VERSION ""

NS_ :

BS_:

BU_: AVM_SD CGW IVI eHBox

BO_ 1330 DVR_N101: 8 CGW
  SG_ GeneralRecordingStatus : 0|1@0+ (1,0) [0|0] "" IVI
  SG_ SDCardStatus : 3|3@0+ (1,0) [0|0] "" IVI
  SG_ DVRWorkStatus : 7|4@0+ (1,0) [0|0] "" IVI
  SG_ LanguageStatus : 9|2@0+ (1,0) [0|0] "" IVI
  SG_ FolderStatus : 11|2@0+ (1,0) [0|0] "" IVI
  SG_ FileStatus : 14|3@0+ (1,0) [0|0] "" IVI
  SG_ PhotoReady : 15|1@0+ (1,0) [0|0] "" IVI
  SG_ CollideCheckStatus : 17|2@0+ (1,0) [0|0] "" IVI
  SG_ ParkingMonitor : 19|2@0+ (1,0) [0|0] "" IVI
  SG_ CollideSensitivityStatus : 21|2@0+ (1,0) [0|0] "" IVI
  SG_ MuteRecordStatus : 23|2@0+ (1,0) [0|0] "" IVI
  SG_ SuperpositionSpeedShow : 25|2@0+ (1,0) [0|0] "" IVI
  SG_ SuperpositionOthersShow : 27|2@0+ (1,0) [0|0] "" IVI
  SG_ RecordVideoQuality : 29|2@0+ (1,0) [0|0] "" IVI
  SG_ RecordTime : 31|2@0+ (1,0) [0|0] "" IVI
  SG_ WiFiStatus : 32|1@0+ (1,0) [0|0] "" IVI
  SG_ DVR_FileSelectStatus : 33|1@0+ (1,0) [0|0] "" IVI
  SG_ NetworkStatus : 39|4@0+ (1,0) [0|0] "" IVI
  SG_ SelftimerState : 41|2@0+ (1,0) [0|0] "" IVI
  SG_ ContrastStateRRcam : 44|3@0+ (1,0) [0|0] "" IVI
  SG_ ContrastStateFRcam : 47|3@0+ (1,0) [0|0] "" IVI
  SG_ NetworkStatus_CameraAngle : 49|2@0+ (1,0) [0|0] "" IVI
  SG_ BrightnessStateRRcam : 52|3@0+ (1,0) [0|0] "" IVI
  SG_ BrightnessStateINcam : 55|3@0+ (1,0) [0|0] "" IVI
  SG_ NetworkStatus_CameraView : 57|2@0+ (1,0) [0|0] "" IVI
  SG_ ContrastStateINcam : 60|3@0+ (1,0) [0|0] "" IVI
  SG_ BrightnessState : 63|3@0+ (1,0) [0|0] "" IVI

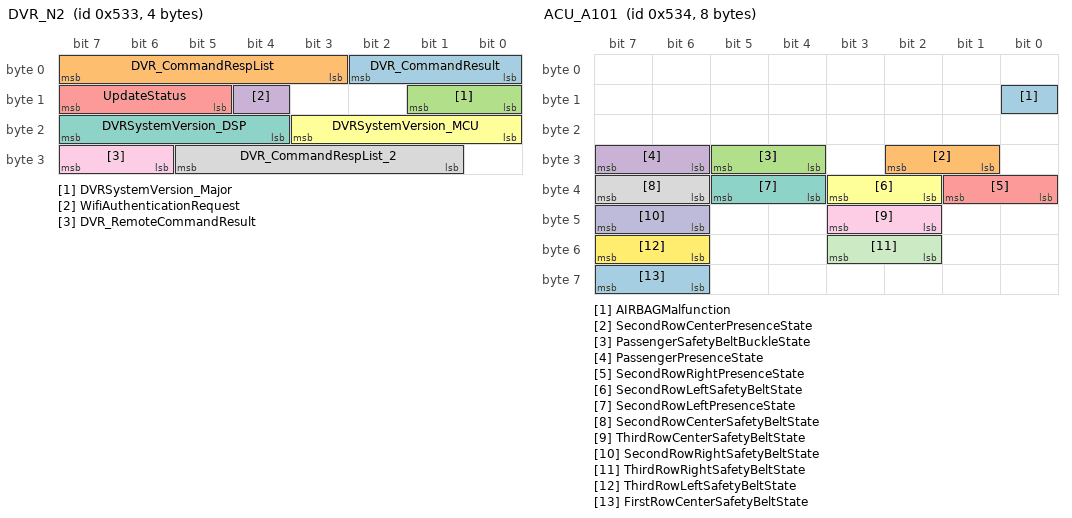
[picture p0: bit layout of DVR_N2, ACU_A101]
BO_ 1331 DVR_N2: 4 CGW
  SG_ DVR_CommandResult : 2|3@0+ (1,0) [0|0] "" IVI
  SG_ DVR_CommandRespList : 7|5@0+ (1,0) [0|0] "" IVI
  SG_ DVRSystemVersion_Major : 9|2@0+ (1,0) [0|0] "" IVI
  SG_ WifiAuthenticationRequest : 12|1@0+ (1,0) [0|0] "" IVI
  SG_ UpdateStatus : 15|3@0+ (1,0) [0|0] "" IVI
  SG_ DVRSystemVersion_MCU : 19|4@0+ (1,0) [0|0] "" IVI
  SG_ DVRSystemVersion_DSP : 23|4@0+ (1,0) [0|0] "" IVI
  SG_ DVR_CommandRespList_2 : 29|5@0+ (1,0) [0|0] "" IVI
  SG_ DVR_RemoteCommandResult : 31|2@0+ (1,0) [0|0] "" IVI

BO_ 1332 ACU_A101: 8 CGW
  SG_ AIRBAGMalfunction : 8|1@0+ (1,0) [0|0] "" IVI
  SG_ SecondRowCenterPresenceState : 26|2@0+ (1,0) [0|0] "" IVI
  SG_ PassengerSafetyBeltBuckleState : 29|2@0+ (1,0) [0|0] "" IVI
  SG_ PassengerPresenceState : 31|2@0+ (1,0) [0|0] "" IVI
  SG_ SecondRowRightPresenceState : 33|2@0+ (1,0) [0|0] "" IVI
  SG_ SecondRowLeftSafetyBeltState : 35|2@0+ (1,0) [0|0] "" IVI
  SG_ SecondRowLeftPresenceState : 37|2@0+ (1,0) [0|0] "" IVI
  SG_ SecondRowCenterSafetyBeltState : 39|2@0+ (1,0) [0|0] "" IVI
  SG_ ThirdRowCenterSafetyBeltState : 43|2@0+ (1,0) [0|0] "" IVI
  SG_ SecondRowRightSafetyBeltState : 47|2@0+ (1,0) [0|0] "" IVI
  SG_ ThirdRowRightSafetyBeltState : 51|2@0+ (1,0) [0|0] "" IVI
  SG_ ThirdRowLeftSafetyBeltState : 55|2@0+ (1,0) [0|0] "" IVI
  SG_ FirstRowCenterSafetyBeltState : 63|2@0+ (1,0) [0|0] "" IVI

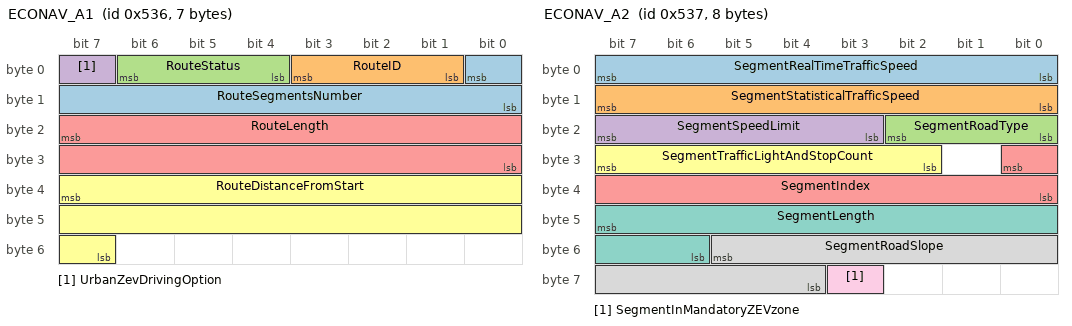
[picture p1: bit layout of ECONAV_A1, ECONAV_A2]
BO_ 1334 ECONAV_A1: 7 IVI
  SG_ RouteSegmentsNumber : 0|9@0+ (1,1) [1|512] "wu" CGW
  SG_ RouteID : 3|3@0+ (1,0) [0|0] "" CGW
  SG_ RouteStatus : 6|3@0+ (1,0) [0|0] "" CGW
  SG_ UrbanZevDrivingOption : 7|1@0+ (1,0) [0|0] "" CGW
  SG_ RouteLength : 23|16@0+ (0.1,0) [0|5000] "km" CGW
  SG_ RouteDistanceFromStart : 39|17@0+ (10,0) [0|1024000] "m" CGW

BO_ 1335 ECONAV_A2: 8 IVI
  SG_ SegmentRealTimeTrafficSpeed : 7|8@0+ (1,0) [0|200] "km/h" CGW
  SG_ SegmentStatisticalTrafficSpeed : 15|8@0+ (1,0) [0|200] "km/h" CGW
  SG_ SegmentRoadType : 18|3@0+ (1,0) [0|0] "" CGW
  SG_ SegmentSpeedLimit : 23|5@0+ (10,0) [0|200] "km/h" CGW
  SG_ SegmentIndex : 24|9@0+ (1,1) [1|512] "" CGW
  SG_ SegmentTrafficLightAndStopCount : 31|6@0+ (1,0) [0|62] "" CGW
  SG_ SegmentLength : 47|10@0+ (10,0) [0|8000] "m" CGW
  SG_ SegmentRoadSlope : 53|10@0+ (0.1,-40) [-40|40] "%" CGW
  SG_ SegmentInMandatoryZEVzone : 59|1@0+ (1,0) [0|0] "" CGW

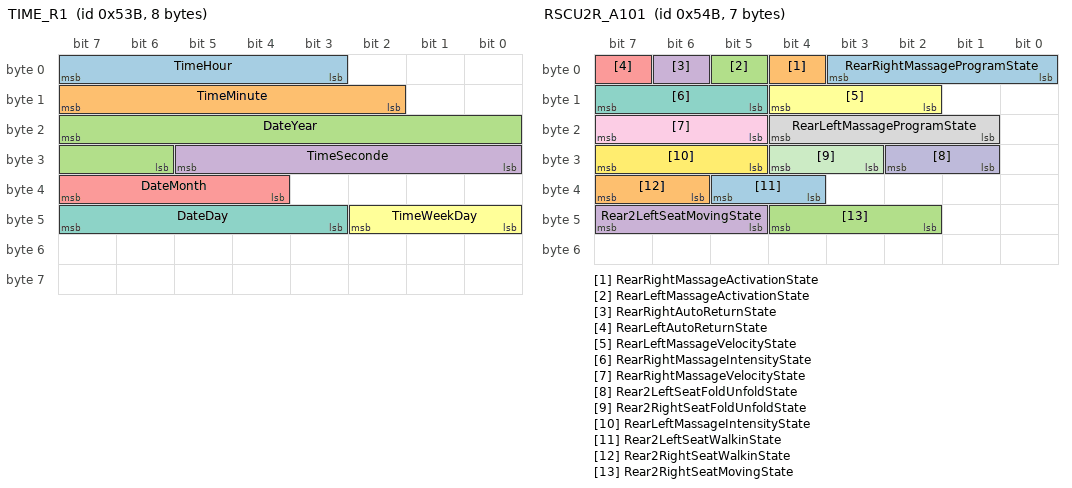
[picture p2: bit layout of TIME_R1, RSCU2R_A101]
BO_ 1339 TIME_R1: 8 IVI
  SG_ TimeHour : 7|5@0+ (1,0) [0|23] "h" CGW
  SG_ TimeMinute : 15|6@0+ (1,0) [0|59] "min" CGW
  SG_ DateYear : 23|10@0+ (1,2000) [2000|3000] "year" CGW
  SG_ TimeSeconde : 29|6@0+ (1,0) [0|59] "s" CGW
  SG_ DateMonth : 39|4@0+ (1,0) [0|12] "month" CGW
  SG_ TimeWeekDay : 42|3@0+ (1,0) [0|0] "" CGW
  SG_ DateDay : 47|5@0+ (1,0) [0|31] "day" CGW

BO_ 1341 SONAR_A4: 8 CGW
  SG_ UPA_SoundRecurrenceType : 0|1@0+ (1,0) [0|0] "" IVI
  SG_ UPA_SoundRecurrencePeriod : 7|7@0+ (0.1,0) [0|12.6] "Hz" IVI
  SG_ UPA_SystemState : 9|2@0+ (1,0) [0|0] "" IVI
  SG_ UPA_Obstacle_Zone_Front_Right : 12|3@0+ (1,0) [0|0] "" AVM_SD,IVI
  SG_ UPA_Obstacle_Zone_Front_Left : 15|3@0+ (1,0) [0|0] "" AVM_SD,IVI
  SG_ UPA_Image_DisplayRequest : 17|2@0+ (1,0) [0|0] "" AVM_SD,IVI
  SG_ UPA_Obstacle_Zone_Rear_Right : 20|3@0+ (1,0) [0|0] "" AVM_SD,IVI
  SG_ UPA_Obstacle_Zone_Rear_Left : 23|3@0+ (1,0) [0|0] "" AVM_SD,IVI
  SG_ UPA_SoundActivationBeep : 24|1@0+ (1,0) [0|0] "" IVI
  SG_ UPA_SoundErrorBeep : 25|1@0+ (1,0) [0|0] "" IVI
  SG_ UPA_Obstacle_Zone_Rear_Center : 28|3@0+ (1,0) [0|0] "" AVM_SD,IVI
  SG_ UPA_Obstacle_Zone_Front_Center : 31|3@0+ (1,0) [0|0] "" AVM_SD,IVI
  SG_ SensorAvailabilityFrontLeft : 32|1@0+ (1,0) [0|0] "" IVI
  SG_ SensorAvailabilityFrontCenter : 33|1@0+ (1,0) [0|0] "" IVI
  SG_ UPA_SoundObstacleZone : 36|3@0+ (1,0) [0|0] "" IVI
  SG_ UPAStatusDisplayRequest : 39|3@0+ (1,0) [0|0] "" IVI
  SG_ SensorAvailabilityFrontRight : 40|1@0+ (1,0) [0|0] "" IVI
  SG_ SonarObstacleDistanceDisplay : 44|4@0+ (1,0) [0|0] "" IVI
  SG_ ParkAssistVolumeState : 47|3@0+ (1,0) [0|0] "" IVI
  SG_ SensorAvailabilityRearRight : 53|1@0+ (1,0) [0|0] "" IVI
  SG_ SensorAvailabilityRearLeft : 54|1@0+ (1,0) [0|0] "" IVI
  SG_ SensorAvailabilityRearCenter : 55|1@0+ (1,0) [0|0] "" IVI
  SG_ UPA_ClosingAuthorization : 58|1@0+ (1,0) [0|0] "" IVI

BO_ 1343 HEVC_A110: 4 CGW
  SG_ V2L_InstantPower : 23|7@0+ (0.1,0) [0|12] "kW" IVI

BO_ 1345 FrCamADAS_R112: 8 CGW
  SG_ Fatigue_CustomShieldRequest : 33|2@0+ (1,0) [0|0] "" IVI
  SG_ Distraction_CustomShieldRequest : 35|2@0+ (1,0) [0|0] "" IVI

BO_ 1354 PSD_A102: 4 CGW
  SG_ PSD_R_AuthorizationState : 1|2@0+ (1,0) [0|0] "" IVI
  SG_ PSD_R_ActivationState : 4|3@0+ (1,0) [0|0] "" IVI
  SG_ PSD_R_ResponseState : 15|3@0+ (1,0) [0|0] "" IVI

BO_ 1355 RSCU2R_A101: 7 CGW
  SG_ RearRightMassageProgramState : 3|4@0+ (1,0) [0|0] "" IVI
  SG_ RearRightMassageActivationState : 4|1@0+ (1,0) [0|0] "" IVI
  SG_ RearLeftMassageActivationState : 5|1@0+ (1,0) [0|0] "" IVI
  SG_ RearRightAutoReturnState : 6|1@0+ (1,0) [0|0] "" IVI
  SG_ RearLeftAutoReturnState : 7|1@0+ (1,0) [0|0] "" IVI
  SG_ RearLeftMassageVelocityState : 12|3@0+ (1,0) [0|0] "" IVI
  SG_ RearRightMassageIntensityState : 15|3@0+ (1,0) [0|0] "" IVI
  SG_ RearLeftMassageProgramState : 20|4@0+ (1,0) [0|0] "" IVI
  SG_ RearRightMassageVelocityState : 23|3@0+ (1,0) [0|0] "" IVI
  SG_ Rear2LeftSeatFoldUnfoldState : 26|2@0+ (1,0) [0|0] "" IVI
  SG_ Rear2RightSeatFoldUnfoldState : 28|2@0+ (1,0) [0|0] "" IVI
  SG_ RearLeftMassageIntensityState : 31|3@0+ (1,0) [0|0] "" IVI
  SG_ Rear2LeftSeatWalkinState : 37|2@0+ (1,0) [0|0] "" IVI
  SG_ Rear2RightSeatWalkinState : 39|2@0+ (1,0) [0|0] "" IVI
  SG_ Rear2RightSeatMovingState : 44|3@0+ (1,0) [0|0] "" IVI
  SG_ Rear2LeftSeatMovingState : 47|3@0+ (1,0) [0|0] "" IVI

BO_ 1356 ADASISv2_A103: 8 IVI
  SG_ ADASISv2_POSITION : 7|64@0+ (1,0) [0|0] "" CGW

BO_ 1358 HEVC_R131: 8 CGW
  SG_ EV_maxChargingPower : 48|9@0+ (1,0) [0|400] "kW" IVI

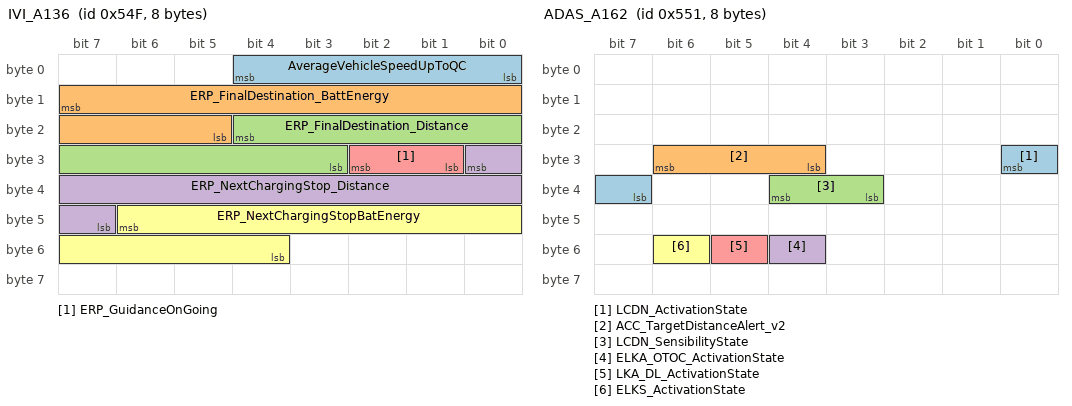
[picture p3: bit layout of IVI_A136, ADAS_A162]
BO_ 1359 IVI_A136: 8 IVI
  SG_ AverageVehicleSpeedUpToQC : 4|5@0+ (10,0) [0|200] "km/h" CGW
  SG_ ERP_FinalDestination_BattEnergy : 15|11@0+ (100,-50000) [-50000|150000] "wh" CGW
  SG_ ERP_FinalDestination_Distance : 20|10@0+ (1,0) [0|1022] "km" CGW
  SG_ ERP_NextChargingStop_Distance : 24|10@0+ (1,0) [0|1022] "km" CGW
  SG_ ERP_GuidanceOnGoing : 26|2@0+ (1,0) [0|0] "" CGW
  SG_ ERP_NextChargingStopBatEnergy : 46|11@0+ (100,-50000) [-50000|150000] "Wh" CGW

BO_ 1361 ADAS_A162: 8 CGW
  SG_ LCDN_ActivationState : 24|2@0+ (1,0) [0|0] "" IVI
  SG_ ACC_TargetDistanceAlert_v2 : 30|3@0+ (1,0) [0|0] "" IVI
  SG_ LCDN_SensibilityState : 36|2@0+ (1,0) [0|0] "" IVI
  SG_ ELKA_OTOC_ActivationState : 52|1@0+ (1,0) [0|0] "" IVI
  SG_ LKA_DL_ActivationState : 53|1@0+ (1,0) [0|0] "" IVI
  SG_ ELKS_ActivationState : 54|1@0+ (1,0) [0|0] "" IVI

BO_ 1364 HVAC_A112: 7 CGW
  SG_ ClimVariableAirFlowDisplay : 4|3@0+ (1,0) [0|0] "" IVI
  SG_ ClimRearOFFModeDisplay : 5|1@0+ (1,0) [0|0] "" IVI
  SG_ ClimRearLockStatus : 7|2@0+ (1,0) [0|0] "" IVI
  SG_ ClimLinkPrio3rdLSeatAutoDisp : 10|3@0+ (1,0) [0|0] "" IVI
  SG_ ClimIRSensorOn_Display : 12|2@0+ (1,0) [0|0] "" IVI
  SG_ ClimLinkPriorityRRSeatAutoDisp : 15|3@0+ (1,0) [0|0] "" IVI
  SG_ ProactiveRecyclingStatus : 16|1@0+ (1,0) [0|0] "" IVI
  SG_ ClimAllSeatAutoDisplay : 18|2@0+ (1,0) [0|0] "" IVI
  SG_ ClimLinkPrio3rdRSeatAutoDisp : 21|3@0+ (1,0) [0|0] "" IVI
  SG_ ClimRearOFFModeDisplayStatus : 22|1@0+ (1,0) [0|0] "" IVI
  SG_ ClimRearLockDisplayStatus : 23|1@0+ (1,0) [0|0] "" IVI
  SG_ RecyPollutionStatus : 27|2@0+ (1,0) [0|0] "" IVI
  SG_ MistingRisk : 31|4@0+ (1,0) [0|10] "WU" IVI
  SG_ SecondRightSeatModeDisp : 33|2@0+ (1,0) [0|0] "" IVI
  SG_ SecondLeftSeatModeDisp : 35|2@0+ (1,0) [0|0] "" IVI
  SG_ FrontRightSeatModeDisp : 37|2@0+ (1,0) [0|0] "" IVI
  SG_ FrontLeftSeatModeDisp : 39|2@0+ (1,0) [0|0] "" IVI
  SG_ ClimLinkOccupantForSeatDisplay : 41|2@0+ (1,0) [0|0] "" IVI
  SG_ ClimLinkOccupantForDRZoneDisp : 43|2@0+ (1,0) [0|0] "" IVI
  SG_ ClimShortcutRequest : 47|4@0+ (1,0) [0|0] "" IVI
  SG_ ClimPartialAutoState : 55|1@0+ (1,0) [0|0] "" IVI

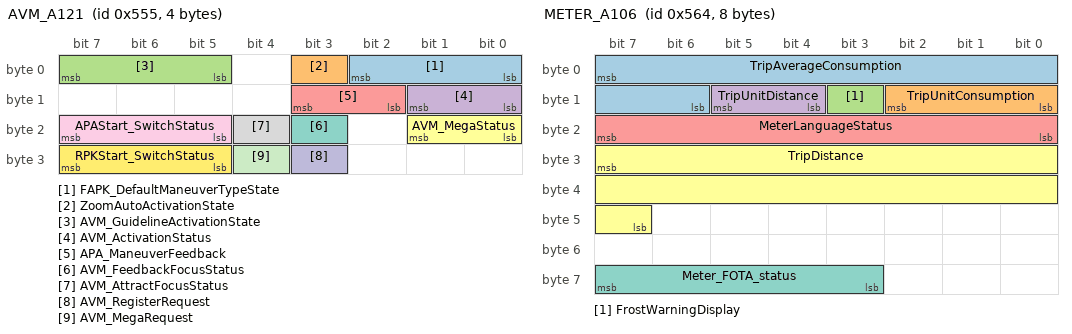
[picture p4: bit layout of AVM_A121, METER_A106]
BO_ 1365 AVM_A121: 4 CGW
  SG_ FAPK_DefaultManeuverTypeState : 2|3@0+ (1,0) [0|0] "" IVI
  SG_ ZoomAutoActivationState : 3|1@0+ (1,0) [0|0] "" IVI
  SG_ AVM_GuidelineActivationState : 7|3@0+ (1,0) [0|0] "" IVI
  SG_ AVM_ActivationStatus : 9|2@0+ (1,0) [0|0] "" IVI
  SG_ APA_ManeuverFeedback : 11|2@0+ (1,0) [0|0] "" IVI
  SG_ AVM_MegaStatus : 17|2@0+ (1,0) [0|0] "" IVI
  SG_ AVM_FeedbackFocusStatus : 19|1@0+ (1,0) [0|0] "" IVI
  SG_ AVM_AttractFocusStatus : 20|1@0+ (1,0) [0|0] "" IVI
  SG_ APAStart_SwitchStatus : 23|3@0+ (1,0) [0|0] "" IVI
  SG_ AVM_RegisterRequest : 27|1@0+ (1,0) [0|0] "" IVI
  SG_ AVM_MegaRequest : 28|1@0+ (1,0) [0|0] "" IVI
  SG_ RPKStart_SwitchStatus : 31|3@0+ (1,0) [0|0] "" IVI

BO_ 1369 ADAS_A125: 8 CGW
  SG_ OSE_RearRightDoorAlert : 17|2@0+ (1,0) [0|0] "" IVI
  SG_ OSE_RearLeftDoorAlert : 19|2@0+ (1,0) [0|0] "" IVI
  SG_ OSE_FrontLeftDoorAlert : 21|2@0+ (1,0) [0|0] "" IVI
  SG_ OSE_FronRightDoorAlert : 23|2@0+ (1,0) [0|0] "" IVI
  SG_ ELKA_AlertLeftRequest : 24|3@0+ (1,0) [0|0] "" IVI
  SG_ ELKA_AlertRightRequest : 37|3@0+ (1,0) [0|0] "" IVI
  SG_ ADAS_LinkFailureRequest : 40|1@0+ (1,0) [0|0] "" IVI
  SG_ ADAS_BranchDirection : 42|2@0+ (1,0) [0|0] "" IVI
  SG_ ADAS_LinkFailurePoint : 47|5@0+ (1,0) [0|30] "-" IVI
  SG_ OSE_ActivationState : 50|1@0+ (1,0) [0|0] "" IVI
  SG_ ELKA_ActivationState : 51|1@0+ (1,0) [0|0] "" IVI
  SG_ EgoCarCenteringPosition : 53|2@0+ (1,0) [0|0] "" IVI
  SG_ ADAS_LinkFailureCounter : 55|2@0+ (1,0) [0|3] "-" IVI
  SG_ SET_MAPAutoUpdate_State : 57|2@0+ (1,0) [0|0] "" IVI
  SG_ SET_FocusState_State : 59|2@0+ (1,0) [0|0] "" IVI
  SG_ SET_ADL3_State : 61|2@0+ (1,0) [0|0] "" IVI
  SG_ SET_ALCP2P_AlertLevel_State : 63|2@0+ (1,0) [0|0] "" IVI

BO_ 1376 HEVC_A145: 5 CGW
  SG_ CRC_HEVC_A145 : 7|8@0+ (1,0) [0|255] "" IVI
  SG_ Clock_HEVC_A145 : 15|4@0+ (1,0) [0|15] "" IVI
  SG_ ChargeTimeDisplayAtEPrct : 20|12@0+ (1,0) [1|4094] "min" IVI
  SG_ V2L_ACoutputPowerRemainingtime : 39|7@0+ (0.1,0) [0|10] "kW" IVI

BO_ 1380 METER_A106: 8 CGW
  SG_ TripAverageConsumption : 7|10@0+ (0.1,0) [0|102.3] "" IVI
  SG_ TripUnitConsumption : 10|3@0+ (1,0) [0|0] "" IVI
  SG_ FrostWarningDisplay : 11|1@0+ (1,0) [0|0] "" IVI
  SG_ TripUnitDistance : 13|2@0+ (1,0) [0|0] "" IVI
  SG_ MeterLanguageStatus : 23|8@0+ (1,0) [0|0] "" IVI
  SG_ TripDistance : 31|17@0+ (0.1,0) [0|13107.1] "" IVI
  SG_ Meter_FOTA_status : 63|5@0+ (1,0) [0|0] "" IVI

BO_ 1381 SRRR_A106: 6 CGW
  SG_ BSWrad_ActivationState : 0|1@0+ (1,0) [0|0] "" IVI
  SG_ CTA_AlertStatus : 7|2@0+ (1,0) [0|0] "" IVI
  SG_ CTA_CollisionRiskAlert : 16|1@0+ (1,0) [0|0] "" IVI

BO_ 1384 IVI_A123: 8 IVI
  SG_ MexModeState_v3 : 3|4@0+ (1,0) [0|0] "" CGW
  SG_ MexAutoState : 4|1@0+ (1,0) [0|0] "" CGW
  SG_ ADBSettingRequest : 7|3@0+ (1,0) [0|0] "" CGW
  SG_ CurrentSpecificUserState : 11|2@0+ (1,0) [0|0] "" CGW
  SG_ VDCSettingRequest : 15|4@0+ (1,0) [0|0] "" CGW
  SG_ ClimRearModeOFFPush : 16|1@0+ (1,0) [0|1] "-" CGW
  SG_ ClimLeftFlowDistrRequest : 19|3@0+ (1,0) [0|0] "" CGW
  SG_ ClimRearLockRequest : 25|2@0+ (1,0) [0|0] "" CGW
  SG_ ClimRearLeftFlowDistRequest : 28|3@0+ (1,0) [0|0] "" CGW
  SG_ ClimRearRightFlowDistRequest : 31|3@0+ (1,0) [0|0] "" CGW
  SG_ FrontLeftSeatAutoRequest : 33|2@0+ (1,0) [0|0] "" CGW
  SG_ ClimRecyclingModeRequest : 36|3@0+ (1,0) [0|0] "" CGW
  SG_ ClimLinkPrioRearSeatsAutoReq : 39|3@0+ (1,0) [0|0] "" CGW
  SG_ FrontRightSeatAutoRequest : 41|2@0+ (1,0) [0|0] "" CGW
  SG_ ClimVariableAirFlowRequest : 44|3@0+ (1,0) [0|0] "" CGW
  SG_ ClimRightFlowDistrRequest : 47|3@0+ (1,0) [0|0] "" CGW
  SG_ SuspensionSettingRequest2_v2 : 51|4@0+ (1,0) [0|0] "" CGW
  SG_ DriveModeRequest2_v2 : 55|4@0+ (1,0) [0|0] "" CGW
  SG_ SecondRowRightSeatAutoRequest : 58|2@0+ (1,0) [0|0] "" CGW
  SG_ SecondRowLeftSeatAutoRequest : 60|2@0+ (1,0) [0|0] "" CGW

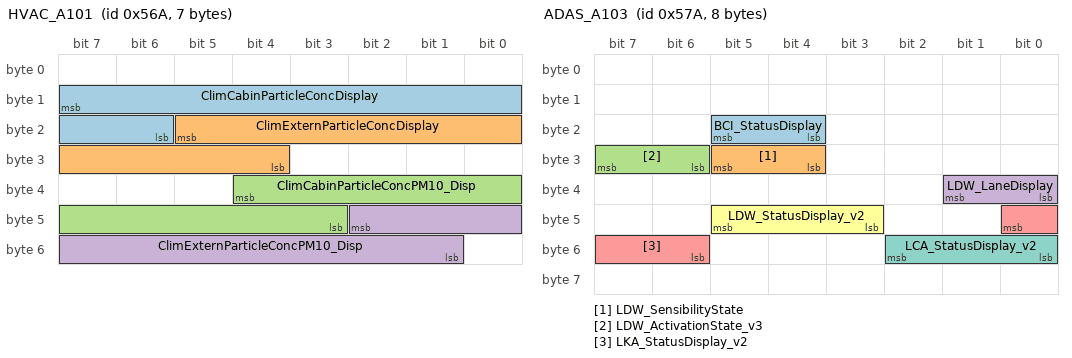
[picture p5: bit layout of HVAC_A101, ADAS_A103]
BO_ 1386 HVAC_A101: 7 CGW
  SG_ ClimCabinParticleConcDisplay : 15|10@0+ (5,0) [0|4095] "µg/m3" IVI
  SG_ ClimExternParticleConcDisplay : 21|10@0+ (5,0) [0|4095] "µg/m3" IVI
  SG_ ClimCabinParticleConcPM10_Disp : 36|10@0+ (5,0) [0|4095] "µg/m3" IVI
  SG_ ClimExternParticleConcPM10_Disp : 42|10@0+ (5,0) [0|4095] "µg/m3" IVI

BO_ 1392 IVI_A119: 8 IVI
  SG_ HUD_ADASactivationRequest2 : 1|2@0+ (1,0) [0|0] "" CGW
  SG_ VSPsoundChoiceActivationRequest2 : 4|3@0+ (1,0) [0|0] "" CGW
  SG_ FAPK_DefaultManeuverTypeRequest2 : 7|3@0+ (1,0) [0|0] "" CGW
  SG_ AmbientLightingColor_v3 : 8|7@0+ (1,0) [0|0] "" CGW
  SG_ FOTA_ReadyToSleep_IVI : 9|1@0+ (1,0) [0|0] "" CGW
  SG_ VSPSoundActivationRequest2 : 11|2@0+ (1,0) [0|0] "" CGW
  SG_ HUD_TurnByTurnActivationRequest2 : 13|2@0+ (1,0) [0|0] "" CGW
  SG_ HUD_TSRactivationRequest2 : 15|2@0+ (1,0) [0|0] "" CGW
  SG_ SET_Acceleration_Request2 : 17|3@0+ (1,0) [0|0] "" CGW
  SG_ SET_NavigatDriveAssist_Request2 : 25|2@0+ (1,0) [0|0] "" CGW
  SG_ SET_ALCActivationByTSIG_Request2 : 27|2@0+ (1,0) [0|0] "" CGW
  SG_ SET_Deceleration_Request2 : 30|3@0+ (1,0) [0|0] "" CGW
  SG_ SET_OvertakingAssist_Request2 : 33|2@0+ (1,0) [0|0] "" CGW
  SG_ SET_LaneChangeSwiftness_Request2 : 36|3@0+ (1,0) [0|0] "" CGW
  SG_ SET_CornerSpeedLevel_Request2 : 39|3@0+ (1,0) [0|0] "" CGW
  SG_ SET_VoiceGuidance_Request2 : 41|2@0+ (1,0) [0|0] "" CGW
  SG_ SET_PositionInLane_Request2 : 44|3@0+ (1,0) [0|0] "" CGW
  SG_ SET_OvertakeRelatSpeed_Request2 : 47|3@0+ (1,0) [0|0] "" CGW
  SG_ IVI_SafeModeAck : 48|1@0+ (1,0) [0|0] "" CGW
  SG_ WDA_ActivationRequest2 : 50|2@0+ (1,0) [0|0] "" CGW
  SG_ RAB_ActivationRequest2 : 52|2@0+ (1,0) [0|0] "" CGW
  SG_ VirtualKeySuspendReq2 : 57|2@0+ (1,0) [0|0] "" CGW
  SG_ SET_MAPAutoUpdate_Request2 : 59|2@0+ (1,0) [0|0] "" CGW
  SG_ SET_FocusState_Request2 : 61|2@0+ (1,0) [0|0] "" CGW
  SG_ SET_ADL3_Request2 : 63|2@0+ (1,0) [0|0] "" CGW

BO_ 1398 HEVC_A155: 7 CGW
  SG_ ChargingStationComType : 11|3@0+ (1,0) [0|0] "" IVI
  SG_ V2G_ActivationState : 51|3@0+ (1,0) [0|0] "" IVI

BO_ 1402 ADAS_A103: 8 CGW
  SG_ BCI_StatusDisplay : 21|2@0+ (1,0) [0|0] "" IVI
  SG_ LDW_SensibilityState : 29|2@0+ (1,0) [0|0] "" IVI
  SG_ LDW_ActivationState_v3 : 31|2@0+ (1,0) [0|0] "" IVI
  SG_ LDW_LaneDisplay : 33|2@0+ (1,0) [0|0] "" IVI
  SG_ LKA_StatusDisplay_v2 : 40|3@0+ (1,0) [0|0] "" IVI
  SG_ LDW_StatusDisplay_v2 : 45|3@0+ (1,0) [0|0] "" IVI
  SG_ LCA_StatusDisplay_v2 : 50|3@0+ (1,0) [0|0] "" IVI

BO_ 1405 AVM_N104: 7 CGW
  SG_ AVM_SettingRequest : 52|2@0+ (1,0) [0|0] "" IVI
  SG_ RPK_ModeRequest : 55|2@0+ (1,0) [0|0] "" IVI

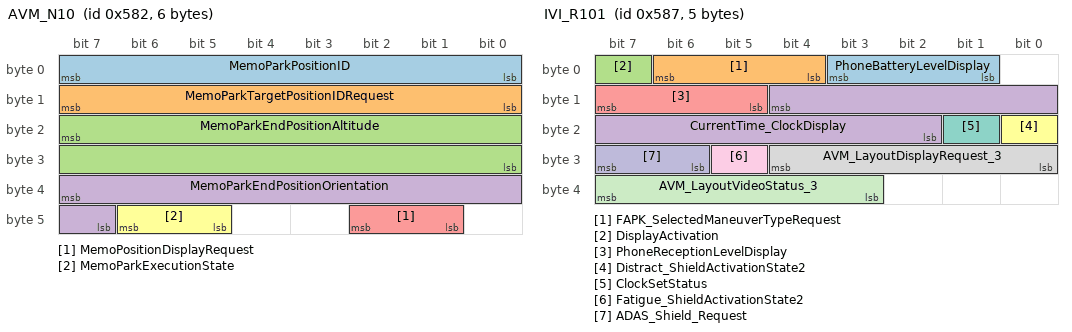
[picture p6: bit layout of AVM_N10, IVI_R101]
BO_ 1410 AVM_N10: 6 CGW
  SG_ MemoParkPositionID : 7|8@0+ (1,0) [0|250] "" IVI
  SG_ MemoParkTargetPositionIDRequest : 15|8@0+ (1,0) [0|250] "" IVI
  SG_ MemoParkEndPositionAltitude : 23|16@0+ (0.1,-500) [-500|3000] "m" IVI
  SG_ MemoParkEndPositionOrientation : 39|9@0+ (1,-180) [-180|179] "°" IVI
  SG_ MemoPositionDisplayRequest : 42|2@0+ (1,0) [0|0] "" IVI
  SG_ MemoParkExecutionState : 46|2@0+ (1,0) [0|0] "" IVI

BO_ 1412 HVAC_A108: 5 CGW
  SG_ HVAC_ClimShortcutPush : 5|1@0+ (1,0) [0|0] "" IVI

BO_ 1413 IVI_A108: 6 IVI
  SG_ AVM_ImagePositionX0 : 7|11@0+ (1,0) [0|2045] "pixel" CGW
  SG_ AVM_ImagePositionY0 : 12|11@0+ (1,0) [0|2045] "pixel" CGW
  SG_ AVM_ImagePositionX1 : 17|11@0+ (1,0) [0|2045] "pixel" CGW
  SG_ AVM_ImagePositionY1 : 38|11@0+ (1,0) [0|2045] "pixel" CGW

BO_ 1415 IVI_R101: 5 IVI
  SG_ PhoneBatteryLevelDisplay : 3|3@0+ (1,0) [0|0] "" CGW
  SG_ FAPK_SelectedManeuverTypeRequest : 6|3@0+ (1,0) [0|0] "" CGW
  SG_ DisplayActivation : 7|1@0+ (1,0) [0|0] "" CGW
  SG_ CurrentTime_ClockDisplay : 12|11@0+ (1,0) [0|1440] "min" CGW
  SG_ PhoneReceptionLevelDisplay : 15|3@0+ (1,0) [0|0] "" CGW
  SG_ Distract_ShieldActivationState2 : 16|1@0+ (1,0) [0|0] "" CGW
  SG_ ClockSetStatus : 17|1@0+ (1,0) [0|0] "" CGW
  SG_ AVM_LayoutDisplayRequest_3 : 28|5@0+ (1,0) [0|0] "" CGW
  SG_ Fatigue_ShieldActivationState2 : 29|1@0+ (1,0) [0|0] "" CGW
  SG_ ADAS_Shield_Request : 31|2@0+ (1,0) [0|0] "" CGW
  SG_ AVM_LayoutVideoStatus_3 : 39|5@0+ (1,0) [0|0] "" CGW

BO_ 1421 SCCM_A102: 2 CGW
  SG_ SCCM_TelescopicMovDisplayReq : 5|2@0+ (1,0) [0|0] "" IVI
  SG_ SCCM_TiltMovDisplayReq : 7|2@0+ (1,0) [0|0] "" IVI

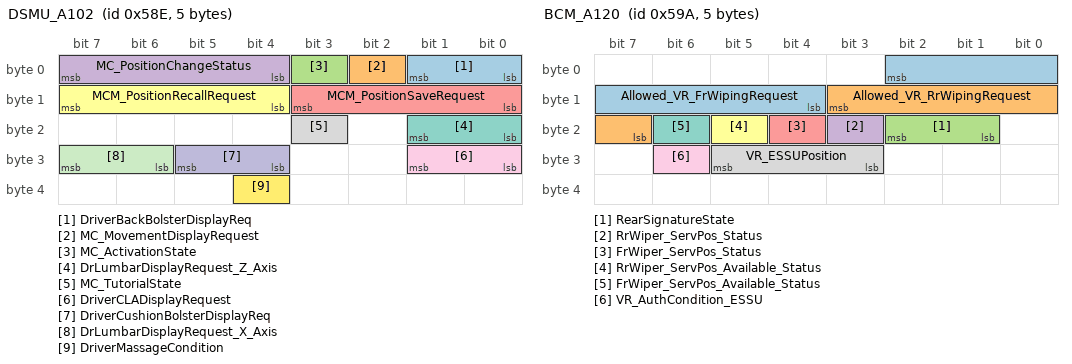
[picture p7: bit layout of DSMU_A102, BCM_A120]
BO_ 1422 DSMU_A102: 5 CGW
  SG_ DriverBackBolsterDisplayReq : 1|2@0+ (1,0) [0|0] "" IVI
  SG_ MC_MovementDisplayRequest : 2|1@0+ (1,0) [0|0] "" IVI
  SG_ MC_ActivationState : 3|1@0+ (1,0) [0|0] "" IVI
  SG_ MC_PositionChangeStatus : 7|4@0+ (1,0) [0|0] "" IVI
  SG_ MCM_PositionSaveRequest : 11|4@0+ (1,0) [0|0] "" IVI
  SG_ MCM_PositionRecallRequest : 15|4@0+ (1,0) [0|0] "" IVI
  SG_ DrLumbarDisplayRequest_Z_Axis : 17|2@0+ (1,0) [0|0] "" IVI
  SG_ MC_TutorialState : 19|1@0+ (1,0) [0|0] "" IVI
  SG_ DriverCLADisplayRequest : 25|2@0+ (1,0) [0|0] "" IVI
  SG_ DriverCushionBolsterDisplayReq : 29|2@0+ (1,0) [0|0] "" IVI
  SG_ DrLumbarDisplayRequest_X_Axis : 31|2@0+ (1,0) [0|0] "" IVI
  SG_ DriverMassageCondition : 36|1@0+ (1,0) [0|0] "" IVI

BO_ 1424 AVM_N11: 8 CGW
  SG_ MemoParkEndPositionLongitude : 7|29@0+ (0.00010,-18000) [-18000.0000|17959.9999] "min" IVI
  SG_ MemoParkEndPositionLatitude : 26|28@0+ (0.00010,-9000) [-9000.0000|8959.9999] "min" IVI

BO_ 1429 AVM_N12: 7 CGW
  SG_ MemoParkStartPositionLongitude : 7|16@0+ (0.00010,-0.2) [-0.2|0.2] "min" IVI
  SG_ MemoParkStartPositionLatitude : 23|16@0+ (0.00010,-0.2) [-0.2|0.2] "min" IVI
  SG_ MemoParkStartPositionAltitude : 39|9@0+ (0.1,-25.5) [-25.5|25.5] "m" IVI
  SG_ MemoParkStartPositionOrientation : 46|9@0+ (1,-180) [-180|179] "°" IVI

BO_ 1434 BCM_A120: 5 CGW
  SG_ Allowed_VR_FrWipingRequest : 2|7@0+ (1,0) [0|0] "" IVI
  SG_ Allowed_VR_RrWipingRequest : 11|5@0+ (1,0) [0|0] "" IVI
  SG_ RearSignatureState : 18|2@0+ (1,0) [0|0] "" IVI
  SG_ RrWiper_ServPos_Status : 19|1@0+ (1,0) [0|0] "" IVI
  SG_ FrWiper_ServPos_Status : 20|1@0+ (1,0) [0|0] "" IVI
  SG_ RrWiper_ServPos_Available_Status : 21|1@0+ (1,0) [0|0] "" IVI
  SG_ FrWiper_ServPos_Available_Status : 22|1@0+ (1,0) [0|0] "" IVI
  SG_ VR_ESSUPosition : 29|3@0+ (1,0) [0|0] "" IVI
  SG_ VR_AuthCondition_ESSU : 30|1@0+ (1,0) [0|0] "" IVI

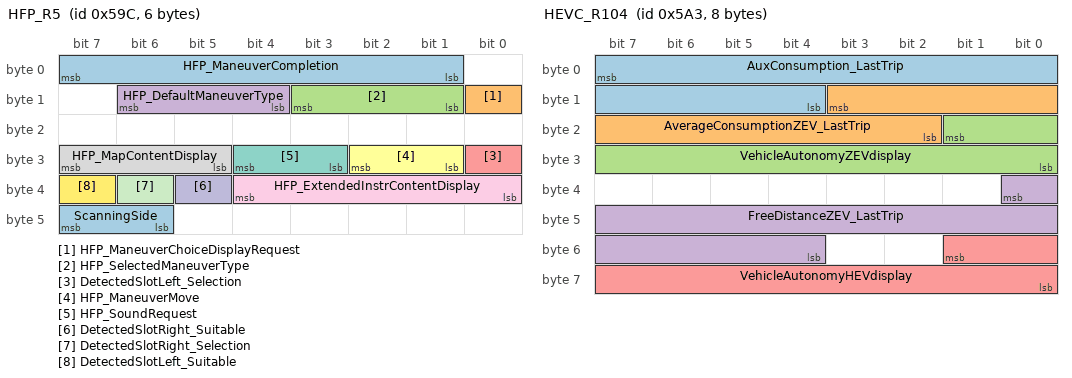
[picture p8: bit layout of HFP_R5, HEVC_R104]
BO_ 1436 HFP_R5: 6 CGW
  SG_ HFP_ManeuverCompletion : 7|7@0+ (1,0) [0|100] "%" IVI
  SG_ HFP_ManeuverChoiceDisplayRequest : 8|1@0+ (1,0) [0|0] "" IVI
  SG_ HFP_SelectedManeuverType : 11|3@0+ (1,0) [0|0] "" IVI
  SG_ HFP_DefaultManeuverType : 14|3@0+ (1,0) [0|0] "" IVI
  SG_ DetectedSlotLeft_Selection : 24|1@0+ (1,0) [0|0] "" IVI
  SG_ HFP_ManeuverMove : 26|2@0+ (1,0) [0|0] "" IVI
  SG_ HFP_SoundRequest : 28|2@0+ (1,0) [0|0] "" IVI
  SG_ HFP_MapContentDisplay : 31|3@0+ (1,0) [0|0] "" AVM_SD,IVI
  SG_ HFP_ExtendedInstrContentDisplay : 36|5@0+ (1,0) [0|0] "" IVI
  SG_ DetectedSlotRight_Suitable : 37|1@0+ (1,0) [0|0] "" IVI
  SG_ DetectedSlotRight_Selection : 38|1@0+ (1,0) [0|0] "" IVI
  SG_ DetectedSlotLeft_Suitable : 39|1@0+ (1,0) [0|0] "" IVI
  SG_ ScanningSide : 47|2@0+ (1,0) [0|0] "" IVI

BO_ 1439 HEVC_A133: 7 CGW
  SG_ InstantPowerZEVdisplay : 7|14@0+ (0.1,-500) [-500|500] "kW" IVI
  SG_ InstantConsumptionZEVdisplay_v3 : 23|11@0+ (0.1,-102.2) [-102.2|102.2] "" IVI
  SG_ InstantChargingApparentPower : 28|12@0+ (0.1,0) [0|400] "kW" IVI

BO_ 1443 HEVC_R104: 8 CGW
  SG_ AuxConsumption_LastTrip : 7|12@0+ (0.1,0) [0|409.4] "kWh" IVI
  SG_ AverageConsumptionZEV_LastTrip : 11|10@0+ (0.1,0) [0|102.2] "" IVI
  SG_ VehicleAutonomyZEVdisplay : 17|10@0+ (1,0) [0|1022] "wu" IVI
  SG_ FreeDistanceZEV_LastTrip : 32|13@0+ (0.1,0) [0|819] "" IVI
  SG_ VehicleAutonomyHEVdisplay : 49|10@0+ (1,0) [0|1022] "" IVI

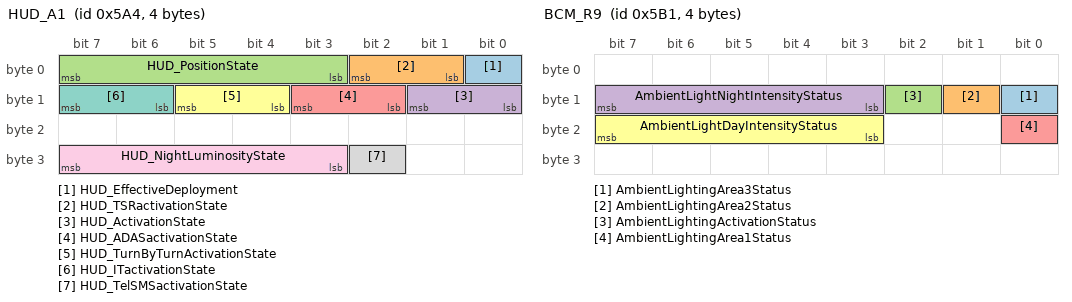
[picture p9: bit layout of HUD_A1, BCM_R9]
BO_ 1444 HUD_A1: 4 CGW
  SG_ HUD_EffectiveDeployment : 0|1@0+ (1,0) [0|0] "" IVI
  SG_ HUD_TSRactivationState : 2|2@0+ (1,0) [0|0] "" IVI
  SG_ HUD_PositionState : 7|5@0+ (1,0) [0|0] "" IVI
  SG_ HUD_ActivationState : 9|2@0+ (1,0) [0|0] "" IVI
  SG_ HUD_ADASactivationState : 11|2@0+ (1,0) [0|0] "" IVI
  SG_ HUD_TurnByTurnActivationState : 13|2@0+ (1,0) [0|0] "" IVI
  SG_ HUD_ITactivationState : 15|2@0+ (1,0) [0|0] "" IVI
  SG_ HUD_TelSMSactivationState : 26|1@0+ (1,0) [0|0] "" IVI
  SG_ HUD_NightLuminosityState : 31|5@0+ (1,0) [0|0] "" IVI

BO_ 1447 MMI_SR_CANHS_R_02: 8 CGW
  SG_ SR_CustomerRecordStatus : 10|2@0+ (1,0) [0|0] "" IVI

BO_ 1448 IVI_N20: 8 IVI
  SG_ ParkEndPositionLongitude : 7|29@0+ (0.00010,-18000) [-18000|17959.9999] "min" CGW
  SG_ ParkEndPositionLatitude : 26|28@0+ (0.00010,-9000) [-9000|8959.9999] "min" CGW

BO_ 1449 IVI_A109: 8 IVI
  SG_ ClimFrontDefrostPush : 0|1@0+ (1,0) [0|1] "-" CGW
  SG_ ClimRearDefrostPush : 1|1@0+ (1,0) [0|1] "-" CGW
  SG_ SecondRowLeftSeatAutoPush : 2|1@0+ (1,0) [0|1] "-" CGW
  SG_ SecondRowRightSeatAutoPush : 3|1@0+ (1,0) [0|1] "-" CGW
  SG_ ThirdRowLeftSeatAutoPush : 4|1@0+ (1,0) [0|1] "-" CGW
  SG_ ThirdRowRightSeatAutoPush : 5|1@0+ (1,0) [0|1] "-" CGW
  SG_ ClimHeatedSteeringWheelPush : 6|1@0+ (1,0) [0|1] "-" CGW
  SG_ ClimHeatedSteeringWheelAutoPush : 7|1@0+ (1,0) [0|1] "-" CGW
  SG_ ClimRearLeftTempRequest : 15|9@0+ (0.5,10) [10|127.5] "°" CGW
  SG_ ClimRearRightTempRequest : 22|9@0+ (0.5,10) [10|127.5] "°" CGW
  SG_ ClimRearRightFlowDistrVentPush : 24|1@0+ (1,0) [0|1] "" CGW
  SG_ ClimRearLeftFlowDistrVentPush : 25|1@0+ (1,0) [0|1] "" CGW
  SG_ ClimRearRightFlowDistrDefPush : 26|1@0+ (1,0) [0|1] "" CGW
  SG_ ClimRearLeftFlowDistrDefPush : 27|1@0+ (1,0) [0|1] "" CGW
  SG_ ClimRearRightSyncPush : 28|1@0+ (1,0) [0|1] "" CGW
  SG_ ClimRearLeftSyncPush : 29|1@0+ (1,0) [0|1] "" CGW
  SG_ ClimLinkPriorityHeatStrgAutoReq : 34|3@0+ (1,0) [0|0] "" CGW
  SG_ ClimRearRightAutoNormalPush : 35|1@0+ (1,0) [0|1] "" CGW
  SG_ ClimRearLeftAutoNormalPush : 36|1@0+ (1,0) [0|1] "" CGW
  SG_ ClimRearACPush : 37|1@0+ (1,0) [0|1] "" CGW
  SG_ ClimRearRightFlowDistrFeetPush : 38|1@0+ (1,0) [0|1] "" CGW
  SG_ ClimRearLeftFlowDistrFeetPush : 39|1@0+ (1,0) [0|1] "" CGW
  SG_ ClimFPrearLeftBlowingRequest : 43|4@0+ (1,0) [0|0] "" CGW
  SG_ ClimFPrearRightBlowingRequest : 47|4@0+ (1,0) [0|0] "" CGW
  SG_ ClimLinkPriorityRRSeatAutoReq : 50|3@0+ (1,0) [0|0] "" CGW
  SG_ ClimACmaxPush : 51|1@0+ (1,0) [0|1] "-" CGW
  SG_ ClimAllSeatAutoNormalRequest : 57|2@0+ (1,0) [0|0] "" CGW
  SG_ ClimLinkPrio3rdRSeatAutoReq : 60|3@0+ (1,0) [0|0] "" CGW
  SG_ ClimLinkPrio3rdLSeatAutoReq : 63|3@0+ (1,0) [0|0] "" CGW

BO_ 1450 MMI_SR_CANHS_R_01: 8 CGW
  SG_ SR_AutomaticRecordStatus : 14|2@0+ (1,0) [0|0] "" IVI

BO_ 1455 VKM_N111: 5 CGW
  SG_ Owner_Key_registration_progress : 7|7@0+ (1,0) [0|100] "wu" IVI
  SG_ VirtualKeyGen2MenuState : 15|6@0+ (1,0) [0|0] "" IVI

BO_ 1457 BCM_R9: 4 CGW
  SG_ AmbientLightingArea3Status : 8|1@0+ (1,0) [0|0] "" IVI
  SG_ AmbientLightingArea2Status : 9|1@0+ (1,0) [0|0] "" IVI
  SG_ AmbientLightingActivationStatus : 10|1@0+ (1,0) [0|0] "" IVI
  SG_ AmbientLightNightIntensityStatus : 15|5@0+ (5,0) [0|100] "%" IVI
  SG_ AmbientLightingArea1Status : 16|1@0+ (1,0) [0|0] "" IVI
  SG_ AmbientLightDayIntensityStatus : 23|5@0+ (5,0) [0|100] "%" IVI

BO_ 1458 HEVC_R112: 8 CGW
  SG_ PnCHEVCactivationStatus : 31|2@0+ (1,0) [0|0] "" IVI
  SG_ SportUsageMPUState : 57|1@0+ (1,0) [0|0] "" IVI
  SG_ SportUsageActivationState : 58|1@0+ (1,0) [0|0] "" IVI
  SG_ PWTConditioningMode : 61|2@0+ (1,0) [0|0] "" IVI

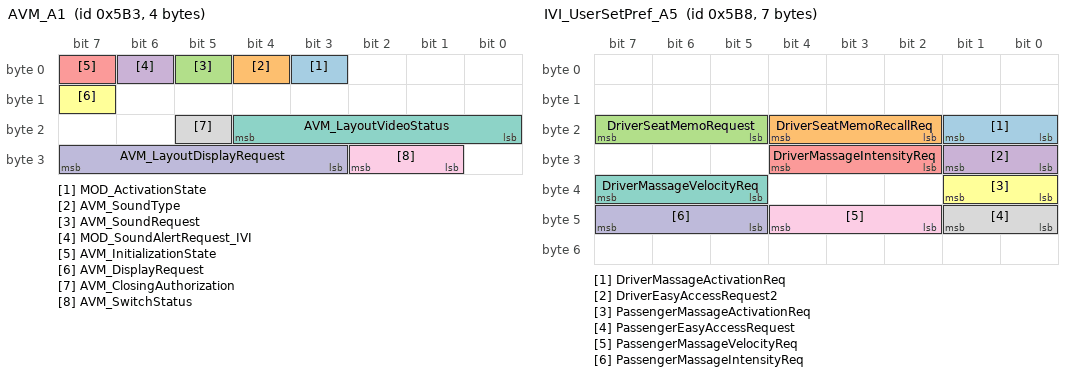
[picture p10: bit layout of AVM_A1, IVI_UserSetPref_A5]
BO_ 1459 AVM_A1: 4 CGW
  SG_ MOD_ActivationState : 3|1@0+ (1,0) [0|0] "" IVI
  SG_ AVM_SoundType : 4|1@0+ (1,0) [0|0] "" IVI
  SG_ AVM_SoundRequest : 5|1@0+ (1,0) [0|0] "" IVI
  SG_ MOD_SoundAlertRequest_IVI : 6|1@0+ (1,0) [0|0] "" IVI
  SG_ AVM_InitializationState : 7|1@0+ (1,0) [0|0] "" IVI
  SG_ AVM_DisplayRequest : 15|1@0+ (1,0) [0|0] "" IVI
  SG_ AVM_LayoutVideoStatus : 20|5@0+ (1,0) [0|0] "" IVI
  SG_ AVM_ClosingAuthorization : 21|1@0+ (1,0) [0|0] "" IVI
  SG_ AVM_SwitchStatus : 26|2@0+ (1,0) [0|0] "" IVI
  SG_ AVM_LayoutDisplayRequest : 31|5@0+ (1,0) [0|0] "" IVI

BO_ 1462 HVAC_A105: 8 CGW
  SG_ ClimRearLeftTempDisplay : 7|9@0+ (0.5,0) [10|127.5] "°" IVI
  SG_ ClimFrontDefrostDisplayStatus : 8|1@0+ (1,0) [0|0] "" IVI
  SG_ ClimHeatedSteerWheelDispStatus : 9|1@0+ (1,0) [0|0] "" IVI
  SG_ ClimRearLeftTempDisplayStatus : 10|1@0+ (1,0) [0|0] "" IVI
  SG_ ClimHeatedSteerWheelAutoDisplay : 12|2@0+ (1,0) [0|0] "" IVI
  SG_ ClimFrontDefrostDisplay : 14|2@0+ (1,0) [0|0] "" IVI
  SG_ ClimRearRightTempDisplay : 23|9@0+ (0.5,0) [10|127.5] "°" IVI
  SG_ ClimRearRightSyncDisplayStatus : 24|1@0+ (1,0) [0|0] "" IVI
  SG_ ClimRearRightSyncDisplay : 26|2@0+ (1,0) [0|0] "" IVI
  SG_ ClimRearLeftSyncDisplayStatus : 27|1@0+ (1,0) [0|0] "" IVI
  SG_ ClimRearLeftSyncDisplay : 29|2@0+ (1,0) [0|0] "" IVI
  SG_ ClimRearRightTempDisplayStatus : 30|1@0+ (1,0) [0|0] "" IVI
  SG_ ClimRearRightFlowDistDispStatus : 32|1@0+ (1,0) [0|0] "" IVI
  SG_ ClimRearRightFlowDistrDisplay : 35|3@0+ (1,0) [0|0] "" IVI
  SG_ ClimRearLeftFlowDistrDispStatus : 36|1@0+ (1,0) [0|0] "" IVI
  SG_ ClimRearLeftFlowDistrDisplay : 39|3@0+ (1,0) [0|0] "" IVI
  SG_ ClimRearLeftBlowingAutoDisplay : 41|2@0+ (1,0) [0|0] "" IVI
  SG_ ClimRearRightBlowingAutoDisplay : 43|2@0+ (1,0) [0|0] "" IVI
  SG_ ClimRearRightBlowLevelDisplay : 47|4@0+ (1,0) [0|0] "" IVI
  SG_ ClimRearACDisplay : 49|2@0+ (1,0) [0|0] "" IVI
  SG_ ClimRearRightBlowLevlDispStatus : 50|1@0+ (1,0) [0|0] "" IVI
  SG_ ClimRearLeftBlowLevelDispStatus : 51|1@0+ (1,0) [0|0] "" IVI
  SG_ ClimRearLeftBlowLevelDisplay : 55|4@0+ (1,0) [0|0] "" IVI
  SG_ ClimLinkPrioritHeatStrgAutoDisp : 58|3@0+ (1,0) [0|0] "" IVI
  SG_ ClimRearRightAutoDisplay : 60|2@0+ (1,0) [0|0] "" IVI
  SG_ ClimRearLeftAutoDisplay : 62|2@0+ (1,0) [0|0] "" IVI
  SG_ ClimRearACDisplayStatus : 63|1@0+ (1,0) [0|0] "" IVI

BO_ 1464 IVI_UserSetPref_A5: 7 IVI
  SG_ DriverMassageActivationReq : 17|2@0+ (1,0) [0|0] "" CGW
  SG_ DriverSeatMemoRecallReq : 20|3@0+ (1,0) [0|0] "" CGW
  SG_ DriverSeatMemoRequest : 23|3@0+ (1,0) [0|0] "" CGW
  SG_ DriverEasyAccessRequest2 : 25|2@0+ (1,0) [0|0] "" CGW
  SG_ DriverMassageIntensityReq : 28|3@0+ (1,0) [0|0] "" CGW
  SG_ PassengerMassageActivationReq : 33|2@0+ (1,0) [0|0] "" CGW
  SG_ DriverMassageVelocityReq : 39|3@0+ (1,0) [0|0] "" CGW
  SG_ PassengerEasyAccessRequest : 41|2@0+ (1,0) [0|0] "" CGW
  SG_ PassengerMassageVelocityReq : 44|3@0+ (1,0) [0|0] "" CGW
  SG_ PassengerMassageIntensityReq : 47|3@0+ (1,0) [0|0] "" CGW

BO_ 1465 IVI_A110: 8 IVI
  SG_ PreSoakHVACfunctionsRequest : 0|2@0+ (1,0) [0|0] "" CGW
  SG_ PreSoakTempValue_MMI_v2 : 7|7@0+ (0.5,16) [16|32] "°C" CGW
  SG_ PreSoakFRseatRequest : 10|3@0+ (1,0) [0|0] "" CGW
  SG_ PreSoakFLseatRequest : 13|3@0+ (1,0) [0|0] "" CGW
  SG_ PreSoakSecondRLseatRequest : 18|3@0+ (1,0) [0|0] "" CGW
  SG_ PreSoakSecondRRseatRequest : 21|3@0+ (1,0) [0|0] "" CGW
  SG_ PreSoak_eACmodeRequest : 23|2@0+ (1,0) [0|0] "" CGW
  SG_ PreSoakThirdRLseatRequest : 26|3@0+ (1,0) [0|0] "" CGW
  SG_ PreSoakBatteryHeatingRequest : 28|2@0+ (1,0) [0|0] "" CGW
  SG_ PreSoakSecondRCseatRequest : 31|3@0+ (1,0) [0|0] "" CGW
  SG_ LivingLightModeRequest : 32|1@0+ (1,0) [0|0] "" CGW
  SG_ PreSoakAirPurifierRequest : 34|2@0+ (1,0) [0|0] "" CGW
  SG_ PreSoakFrontDefrostRequest : 36|2@0+ (1,0) [0|0] "" CGW
  SG_ PreSoakThirdRRseatRequest : 39|3@0+ (1,0) [0|0] "" CGW
  SG_ SecondRowCentralSeatRequest : 43|4@0+ (1,0) [0|0] "" CGW
  SG_ PreSoakRearDefrostRequest : 45|2@0+ (1,0) [0|0] "" CGW
  SG_ PreSoakHeatedStrgWheelRequest : 47|2@0+ (1,0) [0|0] "" CGW
  SG_ FrontRightSeatRequest : 51|4@0+ (1,0) [0|0] "" CGW
  SG_ FrontLeftSeatRequest : 55|4@0+ (1,0) [0|0] "" CGW
  SG_ Dccharge_NextStationTimeArrival : 63|7@0+ (1,0) [0|120] "min" CGW

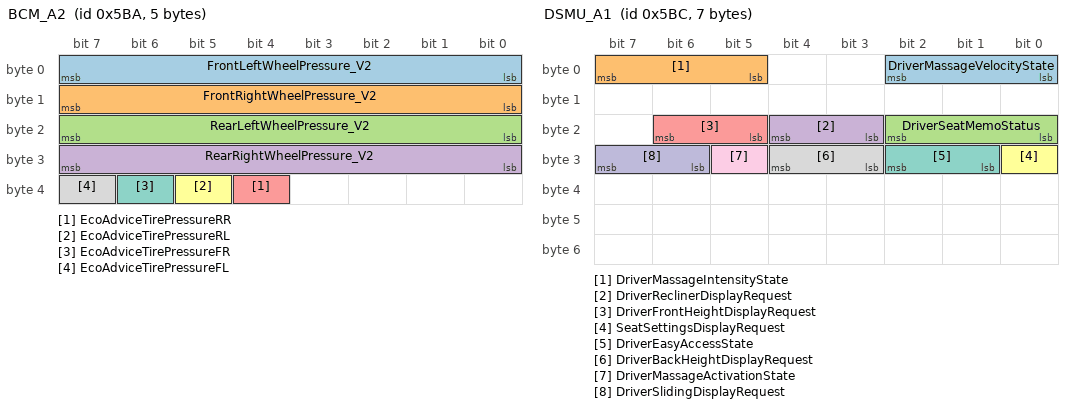
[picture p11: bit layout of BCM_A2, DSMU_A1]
BO_ 1466 BCM_A2: 5 CGW
  SG_ FrontLeftWheelPressure_V2 : 7|8@0+ (30,0) [0|7620] "mbar" IVI
  SG_ FrontRightWheelPressure_V2 : 15|8@0+ (30,0) [0|7620] "mbar" IVI
  SG_ RearLeftWheelPressure_V2 : 23|8@0+ (30,0) [0|7620] "mbar" IVI
  SG_ RearRightWheelPressure_V2 : 31|8@0+ (30,0) [0|7620] "mbar" IVI
  SG_ EcoAdviceTirePressureRR : 36|1@0+ (1,0) [0|0] "" IVI
  SG_ EcoAdviceTirePressureRL : 37|1@0+ (1,0) [0|0] "" IVI
  SG_ EcoAdviceTirePressureFR : 38|1@0+ (1,0) [0|0] "" IVI
  SG_ EcoAdviceTirePressureFL : 39|1@0+ (1,0) [0|0] "" IVI

BO_ 1468 DSMU_A1: 7 CGW
  SG_ DriverMassageVelocityState : 2|3@0+ (1,0) [0|0] "" IVI
  SG_ DriverMassageIntensityState : 7|3@0+ (1,0) [0|0] "" IVI
  SG_ DriverSeatMemoStatus : 18|3@0+ (1,0) [0|0] "" IVI
  SG_ DriverReclinerDisplayRequest : 20|2@0+ (1,0) [0|0] "" IVI
  SG_ DriverFrontHeightDisplayRequest : 22|2@0+ (1,0) [0|0] "" IVI
  SG_ SeatSettingsDisplayRequest : 24|1@0+ (1,0) [0|0] "" IVI
  SG_ DriverEasyAccessState : 26|2@0+ (1,0) [0|0] "" IVI
  SG_ DriverBackHeightDisplayRequest : 28|2@0+ (1,0) [0|0] "" IVI
  SG_ DriverMassageActivationState : 29|1@0+ (1,0) [0|0] "" IVI
  SG_ DriverSlidingDisplayRequest : 31|2@0+ (1,0) [0|0] "" IVI

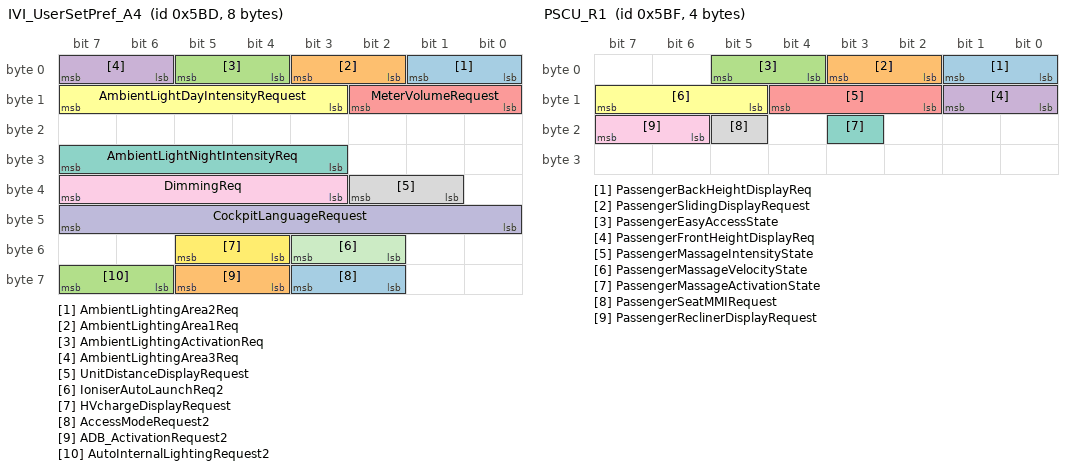
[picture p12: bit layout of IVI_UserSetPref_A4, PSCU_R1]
BO_ 1469 IVI_UserSetPref_A4: 8 IVI
  SG_ AmbientLightingArea2Req : 1|2@0+ (1,0) [0|0] "" CGW
  SG_ AmbientLightingArea1Req : 3|2@0+ (1,0) [0|0] "" CGW
  SG_ AmbientLightingActivationReq : 5|2@0+ (1,0) [0|0] "" CGW
  SG_ AmbientLightingArea3Req : 7|2@0+ (1,0) [0|0] "" CGW
  SG_ MeterVolumeRequest : 10|3@0+ (1,0) [0|0] "" CGW
  SG_ AmbientLightDayIntensityRequest : 15|5@0+ (5,0) [0|100] "%" CGW
  SG_ AmbientLightNightIntensityReq : 31|5@0+ (5,0) [0|100] "%" CGW
  SG_ UnitDistanceDisplayRequest : 34|2@0+ (1,0) [0|0] "" CGW
  SG_ DimmingReq : 39|5@0+ (1,0) [0|0] "" CGW
  SG_ CockpitLanguageRequest : 47|8@0+ (1,0) [0|0] "" CGW
  SG_ IoniserAutoLaunchReq2 : 51|2@0+ (1,0) [0|0] "" CGW
  SG_ HVchargeDisplayRequest : 53|2@0+ (1,0) [0|0] "" CGW
  SG_ AccessModeRequest2 : 59|2@0+ (1,0) [0|0] "" CGW
  SG_ ADB_ActivationRequest2 : 61|2@0+ (1,0) [0|0] "" CGW
  SG_ AutoInternalLightingRequest2 : 63|2@0+ (1,0) [0|0] "" CGW

BO_ 1471 PSCU_R1: 4 CGW
  SG_ PassengerBackHeightDisplayReq : 1|2@0+ (1,0) [0|0] "" IVI
  SG_ PassengerSlidingDisplayRequest : 3|2@0+ (1,0) [0|0] "" IVI
  SG_ PassengerEasyAccessState : 5|2@0+ (1,0) [0|0] "" IVI
  SG_ PassengerFrontHeightDisplayReq : 9|2@0+ (1,0) [0|0] "" IVI
  SG_ PassengerMassageIntensityState : 12|3@0+ (1,0) [0|0] "" IVI
  SG_ PassengerMassageVelocityState : 15|3@0+ (1,0) [0|0] "" IVI
  SG_ PassengerMassageActivationState : 19|1@0+ (1,0) [0|0] "" IVI
  SG_ PassengerSeatMMIRequest : 21|1@0+ (1,0) [0|0] "" IVI
  SG_ PassengerReclinerDisplayRequest : 23|2@0+ (1,0) [0|0] "" IVI

BO_ 1472 MULTIDRIVE_A1: 8 IVI
  SG_ MexModeState : 44|3@0+ (1,0) [0|0] "" CGW

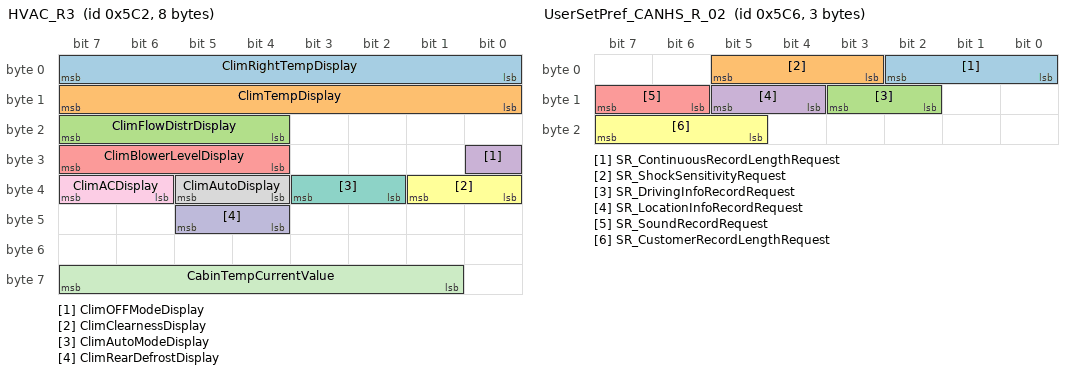
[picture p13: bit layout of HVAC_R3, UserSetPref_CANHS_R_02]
BO_ 1474 HVAC_R3: 8 CGW
  SG_ ClimRightTempDisplay : 7|8@0+ (0.5,0) [10|127.5] "°" IVI
  SG_ ClimTempDisplay : 15|8@0+ (0.5,0) [10|127.5] "°" IVI
  SG_ ClimFlowDistrDisplay : 23|4@0+ (1,0) [0|0] "" IVI
  SG_ ClimOFFModeDisplay : 24|1@0+ (1,0) [0|0] "" IVI
  SG_ ClimBlowerLevelDisplay : 31|4@0+ (1,0) [0|0] "" IVI
  SG_ ClimClearnessDisplay : 33|2@0+ (1,0) [0|0] "" IVI
  SG_ ClimAutoModeDisplay : 35|2@0+ (1,0) [0|0] "" IVI
  SG_ ClimAutoDisplay : 37|2@0+ (1,0) [0|0] "" IVI
  SG_ ClimACDisplay : 39|2@0+ (1,0) [0|0] "" IVI
  SG_ ClimRearDefrostDisplay : 45|2@0+ (1,0) [0|0] "" IVI
  SG_ CabinTempCurrentValue : 63|7@0+ (1,-40) [-40|60] "°C" IVI

BO_ 1478 UserSetPref_CANHS_R_02: 3 IVI
  SG_ SR_ContinuousRecordLengthRequest : 2|3@0+ (1,0) [0|0] "" CGW
  SG_ SR_ShockSensitivityRequest : 5|3@0+ (1,0) [0|0] "" CGW
  SG_ SR_DrivingInfoRecordRequest : 11|2@0+ (1,0) [0|0] "" CGW
  SG_ SR_LocationInfoRecordRequest : 13|2@0+ (1,0) [0|0] "" CGW
  SG_ SR_SoundRecordRequest : 15|2@0+ (1,0) [0|0] "" CGW
  SG_ SR_CustomerRecordLengthRequest : 23|3@0+ (1,0) [0|0] "" CGW

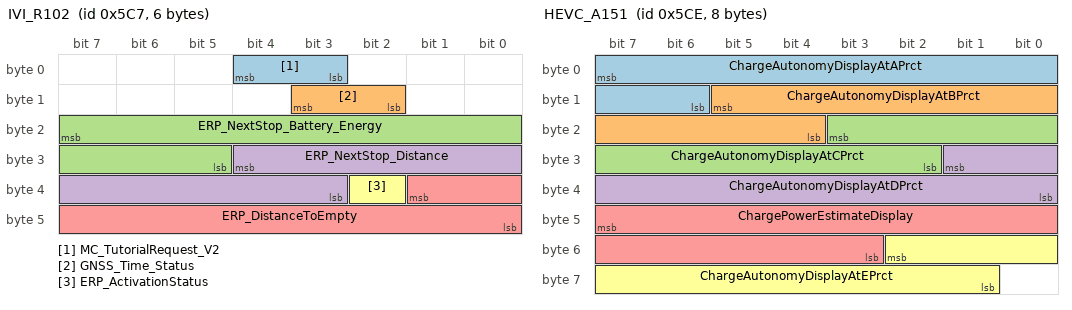
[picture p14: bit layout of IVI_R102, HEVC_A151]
BO_ 1479 IVI_R102: 6 IVI
  SG_ MC_TutorialRequest_V2 : 4|2@0+ (1,0) [0|0] "" CGW
  SG_ GNSS_Time_Status : 11|2@0+ (1,0) [0|0] "" CGW
  SG_ ERP_NextStop_Battery_Energy : 23|11@0+ (100,-50000) [-50000|150000] "Wh" CGW
  SG_ ERP_NextStop_Distance : 28|10@0+ (1,0) [0|1022] "wu" CGW
  SG_ ERP_DistanceToEmpty : 33|10@0+ (1,0) [0|1022] "km" CGW
  SG_ ERP_ActivationStatus : 34|1@0+ (1,0) [0|0] "" CGW

BO_ 1480 HEVC_A152: 8 CGW
  SG_ ChargeTimeDisplayAtAPrct : 23|12@0+ (1,0) [1|4094] "min" IVI
  SG_ ChargeTimeDisplayAtBPrct : 27|12@0+ (1,0) [1|4094] "min" IVI
  SG_ ChargeTimeDisplayAtCPrct : 47|12@0+ (1,0) [1|4094] "min" IVI
  SG_ ChargeTimeDisplayAtDPrct : 51|12@0+ (1,0) [1|4094] "min" IVI

BO_ 1482 IVI_UserSetPref_A2: 8 IVI
  SG_ TSR_OSPActivationRequest2 : 1|2@0+ (1,0) [0|0] "" CGW
  SG_ TPMS_PressureFrontAxleRequest2 : 7|6@0+ (10,140) [150|760] "kPa" CGW
  SG_ TPMS_PressureRearAxleRequest2 : 15|6@0+ (10,140) [150|760] "kPa" CGW
  SG_ LDW_ActivationRequest2 : 17|2@0+ (1,0) [0|0] "" CGW
  SG_ LDW_VibrationIntensityReq2 : 20|3@0+ (1,0) [0|0] "" CGW
  SG_ SailingStopActivationRequest2 : 25|2@0+ (1,0) [0|0] "" CGW
  SG_ AEB_FCWactivationRequest2 : 28|3@0+ (1,0) [0|0] "" CGW
  SG_ LDW_SensibilityRequest2 : 31|3@0+ (1,0) [0|0] "" CGW
  SG_ FKP_ActivationRequest2 : 33|2@0+ (1,0) [0|0] "" CGW
  SG_ MOD_ActivationRequest2 : 35|2@0+ (1,0) [0|0] "" CGW
  SG_ SonarAutoDisplayRequest2 : 37|2@0+ (1,0) [0|0] "" CGW
  SG_ DW_ActivationRequest2 : 39|2@0+ (1,0) [0|0] "" CGW
  SG_ BSWrad_ActivationRequest2 : 41|2@0+ (1,0) [0|0] "" CGW
  SG_ HFP_DefaultManeuverTypeRequest2 : 44|3@0+ (1,0) [0|0] "" CGW
  SG_ HandDrivingActivationRequest2 : 47|2@0+ (1,0) [0|0] "" CGW
  SG_ LKA_ActivationRequest2 : 51|2@0+ (1,0) [0|0] "" CGW
  SG_ SailingIdleActivationReq2 : 53|2@0+ (1,0) [0|0] "" CGW
  SG_ CTA_ActivationRequest2 : 59|2@0+ (1,0) [0|0] "" CGW
  SG_ AFS_ActivationRequest2 : 61|2@0+ (1,0) [0|0] "" CGW
  SG_ LCA_ActivationRequest2 : 63|2@0+ (1,0) [0|0] "" CGW

BO_ 1486 HEVC_A151: 8 CGW
  SG_ ChargeAutonomyDisplayAtAPrct : 7|10@0+ (1,0) [1|1022] "km" IVI
  SG_ ChargeAutonomyDisplayAtBPrct : 13|10@0+ (1,0) [1|1022] "km" IVI
  SG_ ChargeAutonomyDisplayAtCPrct : 19|10@0+ (1,0) [1|1022] "km" IVI
  SG_ ChargeAutonomyDisplayAtDPrct : 25|10@0+ (1,0) [1|1022] "km" IVI
  SG_ ChargePowerEstimateDisplay : 47|13@0+ (0.1,0) [0.1|500] "kW" IVI
  SG_ ChargeAutonomyDisplayAtEPrct : 50|10@0+ (1,0) [1|1022] "km" IVI

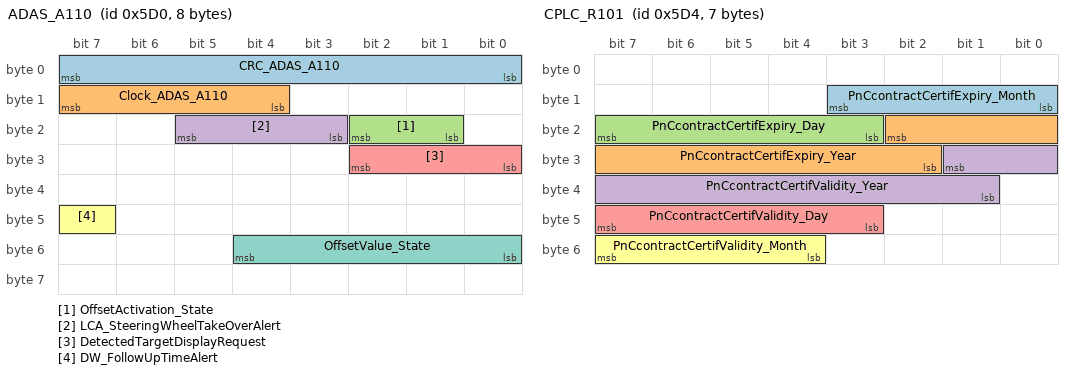
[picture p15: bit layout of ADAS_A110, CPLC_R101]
BO_ 1488 ADAS_A110: 8 CGW
  SG_ CRC_ADAS_A110 : 7|8@0+ (1,0) [0|255] "" IVI
  SG_ Clock_ADAS_A110 : 15|4@0+ (1,0) [0|15] "" IVI
  SG_ OffsetActivation_State : 18|2@0+ (1,0) [0|0] "" IVI
  SG_ LCA_SteeringWheelTakeOverAlert : 21|3@0+ (1,0) [0|0] "" IVI
  SG_ DetectedTargetDisplayRequest : 26|3@0+ (1,0) [0|0] "" IVI
  SG_ DW_FollowUpTimeAlert : 47|1@0+ (1,0) [0|0] "" IVI
  SG_ OffsetValue_State : 52|5@0+ (1,0) [0|0] "" IVI

BO_ 1490 HUD_A101: 3 CGW
  SG_ HUD_IVI_Status : 2|2@0+ (1,0) [0|0] "" IVI
  SG_ HUD_RotationPositionState : 7|5@0+ (1,0) [0|0] "" IVI
  SG_ HUD_FOTA_status : 15|5@0+ (1,0) [0|0] "" IVI

BO_ 1491 METER_UserSetPref_A1: 8 CGW
  SG_ ParkAssistVolumeRequest : 7|3@0+ (1,0) [0|0] "" IVI

BO_ 1492 CPLC_R101: 7 CGW
  SG_ PnCcontractCertifExpiry_Month : 11|4@0+ (1,0) [0|12] "month" IVI
  SG_ PnCcontractCertifExpiry_Year : 18|9@0+ (1,2000) [2000|2500] "year" IVI
  SG_ PnCcontractCertifExpiry_Day : 23|5@0+ (1,0) [0|31] "day" IVI
  SG_ PnCcontractCertifValidity_Year : 25|9@0+ (1,2000) [2000|2500] "year" IVI
  SG_ PnCcontractCertifValidity_Day : 47|5@0+ (1,0) [0|31] "day" IVI
  SG_ PnCcontractCertifValidity_Month : 55|4@0+ (1,0) [0|12] "month" IVI

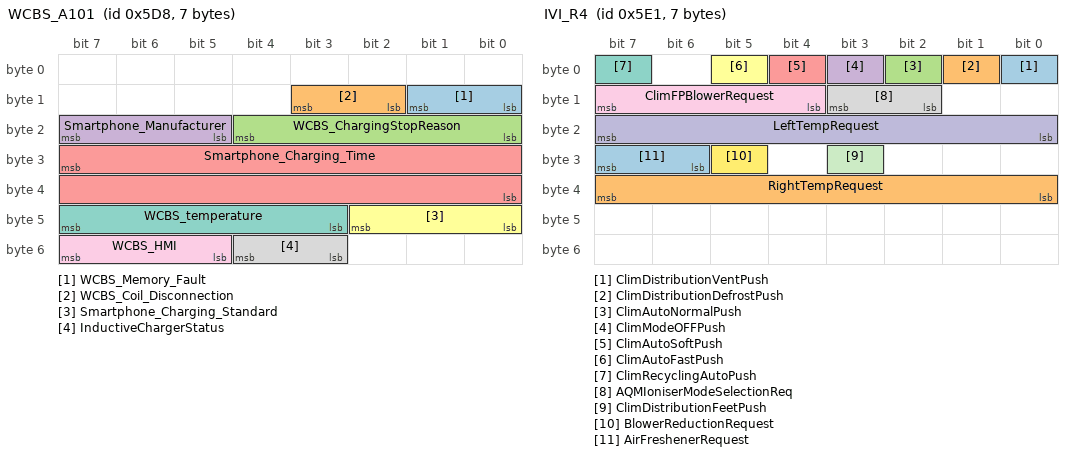
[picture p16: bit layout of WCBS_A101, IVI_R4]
BO_ 1496 WCBS_A101: 7 CGW
  SG_ WCBS_Memory_Fault : 9|2@0+ (1,0) [0|0] "" IVI
  SG_ WCBS_Coil_Disconnection : 11|2@0+ (1,0) [0|0] "" IVI
  SG_ WCBS_ChargingStopReason : 20|5@0+ (1,0) [0|0] "" IVI
  SG_ Smartphone_Manufacturer : 23|3@0+ (1,0) [0|0] "" IVI
  SG_ Smartphone_Charging_Time : 31|16@0+ (1,1) [1|36000] "s" IVI
  SG_ Smartphone_Charging_Standard : 42|3@0+ (1,0) [0|0] "" IVI
  SG_ WCBS_temperature : 47|5@0+ (5,0) [0|100] "°C" IVI
  SG_ InductiveChargerStatus : 52|2@0+ (1,0) [0|0] "" IVI
  SG_ WCBS_HMI : 55|3@0+ (1,0) [0|0] "" IVI

BO_ 1498 ADAS_A155: 5 CGW
  SG_ AD_DistanceDuration : 7|14@0+ (0.1,-0.1) [0|1638] "km" IVI
  SG_ AD_TimeDuration : 9|10@0+ (1,-1) [0|1022] "min" IVI
  SG_ RouteConf_IVI_Request : 24|1@0+ (1,0) [0|0] "" IVI
  SG_ AD_MapLisence_Status : 35|2@0+ (1,0) [0|0] "" IVI

BO_ 1502 CDM_A107: 3 CGW
  SG_ MultiDriveMode_ECM_v2 : 7|4@0+ (1,0) [0|0] "" IVI

BO_ 1503 PSCU_A101: 6 CGW
  SG_ PassengerBackBolsterDisplayReq : 1|2@0+ (1,0) [0|0] "" IVI
  SG_ PassengerSeatMemoState : 7|3@0+ (1,0) [0|0] "" IVI
  SG_ PassengerSwitchMassageRequest : 9|1@0+ (1,0) [0|0] "" IVI
  SG_ PsgerCushionBolsterDisplayReq : 11|2@0+ (1,0) [0|0] "" IVI
  SG_ PsLumbarDisplayRequest_Z_Axis : 13|2@0+ (1,0) [0|0] "" IVI
  SG_ PsLumbarDisplayRequest_X_Axis : 15|2@0+ (1,0) [0|0] "" IVI
  SG_ PassengerCLADisplayRequest : 23|2@0+ (1,0) [0|0] "" IVI
  SG_ PassengerOttomanMotorErrorState : 24|1@0+ (1,0) [0|0] "" IVI
  SG_ PsMassagePopUpActivationState : 25|1@0+ (1,0) [0|0] "" IVI
  SG_ PsMassageExecuteState : 28|3@0+ (1,0) [0|0] "" IVI
  SG_ PassengerMassageCondition : 29|1@0+ (1,0) [0|0] "" IVI
  SG_ PassengerLifterMotorErrorState : 32|1@0+ (1,0) [0|0] "" IVI
  SG_ PassengerReclinerMotorErrorState : 34|2@0+ (1,0) [0|0] "" IVI
  SG_ PassengerMemoryPopUpReq : 35|1@0+ (1,0) [0|0] "" IVI
  SG_ PassengerMemorySetState : 36|1@0+ (1,0) [0|0] "" IVI
  SG_ PassengerMemoryRecallState : 39|3@0+ (1,0) [0|0] "" IVI
  SG_ PassengerSlideMotorErrorState : 47|2@0+ (1,0) [0|0] "" IVI

BO_ 1505 IVI_R4: 7 IVI
  SG_ ClimDistributionVentPush : 0|1@0+ (1,0) [0|1] "" CGW
  SG_ ClimDistributionDefrostPush : 1|1@0+ (1,0) [0|1] "" CGW
  SG_ ClimAutoNormalPush : 2|1@0+ (1,0) [0|1] "" CGW
  SG_ ClimModeOFFPush : 3|1@0+ (1,0) [0|1] "" CGW
  SG_ ClimAutoSoftPush : 4|1@0+ (1,0) [0|1] "" CGW
  SG_ ClimAutoFastPush : 5|1@0+ (1,0) [0|1] "" CGW
  SG_ ClimRecyclingAutoPush : 7|1@0+ (1,0) [0|1] "" CGW
  SG_ AQMIoniserModeSelectionReq : 11|2@0+ (1,0) [0|0] "" CGW
  SG_ ClimFPBlowerRequest : 15|4@0+ (1,0) [0|0] "" CGW
  SG_ LeftTempRequest : 23|8@0+ (0.5,10) [10|127.5] "°" CGW
  SG_ ClimDistributionFeetPush : 27|1@0+ (1,0) [0|1] "" CGW
  SG_ BlowerReductionRequest : 29|1@0+ (1,0) [0|0] "" CGW
  SG_ AirFreshenerRequest : 31|2@0+ (1,0) [0|0] "" CGW
  SG_ RightTempRequest : 39|8@0+ (0.5,10) [10|127.5] "°" CGW

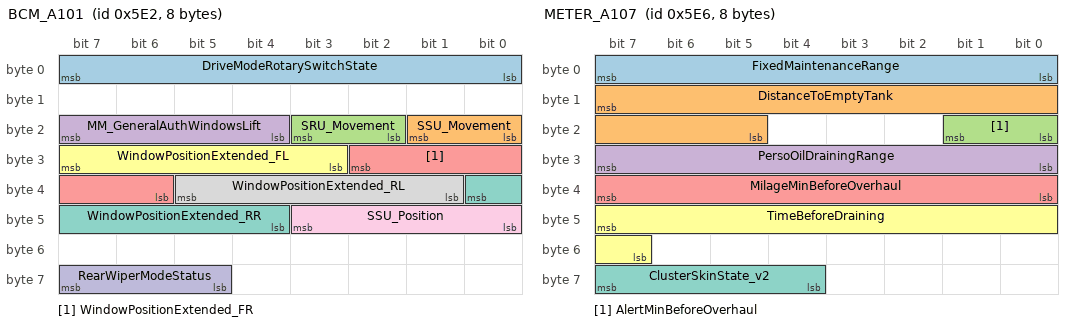
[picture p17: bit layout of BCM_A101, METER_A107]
BO_ 1506 BCM_A101: 8 CGW
  SG_ DriveModeRotarySwitchState : 7|8@0+ (1,0) [0|255] "Position" IVI
  SG_ SSU_Movement : 17|2@0+ (1,0) [0|0] "" IVI
  SG_ SRU_Movement : 19|2@0+ (1,0) [0|0] "" IVI
  SG_ MM_GeneralAuthWindowsLift : 23|4@0+ (1,0) [0|0] "" IVI
  SG_ WindowPositionExtended_FR : 26|5@0+ (1,0) [0|0] "" IVI
  SG_ WindowPositionExtended_FL : 31|5@0+ (1,0) [0|0] "" IVI
  SG_ WindowPositionExtended_RR : 32|5@0+ (1,0) [0|0] "" IVI
  SG_ WindowPositionExtended_RL : 37|5@0+ (1,0) [0|0] "" IVI
  SG_ SSU_Position : 43|4@0+ (1,0) [0|0] "" IVI
  SG_ RearWiperModeStatus : 63|3@0+ (1,0) [0|0] "" IVI

BO_ 1508 BCM_A115: 8 CGW
  SG_ RESPreSoak_ProgStatus : 9|2@0+ (1,0) [0|0] "" IVI
  SG_ InternalLightingIntensityState : 47|3@0+ (1,0) [0|0] "" IVI
  SG_ RES_ProgrammationForbidden : 60|1@0+ (1,0) [0|0] "" IVI

BO_ 1509 RemoteFunctionService_TCU_Frame: 8 CGW
  SG_ RemoteFunctionService_TCU : 7|64@0+ (1,0) [0|0] "" IVI

BO_ 1510 METER_A107: 8 CGW
  SG_ FixedMaintenanceRange : 7|8@0+ (250,0) [0|63250] "km" IVI
  SG_ DistanceToEmptyTank : 15|11@0+ (1,0) [0|2046] "km" IVI
  SG_ AlertMinBeforeOverhaul : 17|2@0+ (1,0) [0|0] "" IVI
  SG_ PersoOilDrainingRange : 31|8@0+ (250,0) [0|63500] "km" IVI
  SG_ MilageMinBeforeOverhaul : 39|8@0+ (250,0) [0|63500] "km" IVI
  SG_ TimeBeforeDraining : 47|9@0+ (1,0) [0|511] "day" IVI
  SG_ ClusterSkinState_v2 : 63|4@0+ (1,0) [0|0] "" IVI

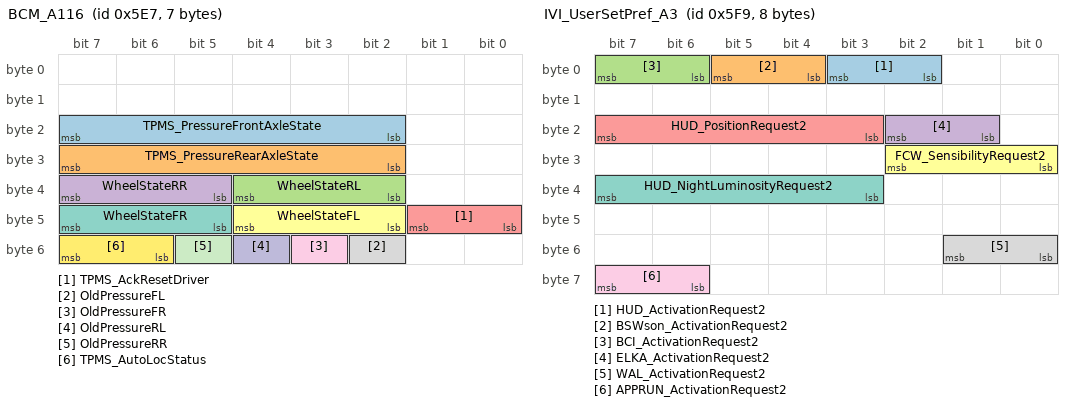
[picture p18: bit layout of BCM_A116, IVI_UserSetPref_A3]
BO_ 1511 BCM_A116: 7 CGW
  SG_ TPMS_PressureFrontAxleState : 23|6@0+ (10,150) [150|760] "kPa" IVI
  SG_ TPMS_PressureRearAxleState : 31|6@0+ (10,150) [150|760] "kPa" IVI
  SG_ WheelStateRL : 36|3@0+ (1,0) [0|0] "" IVI
  SG_ WheelStateRR : 39|3@0+ (1,0) [0|0] "" IVI
  SG_ TPMS_AckResetDriver : 41|2@0+ (1,0) [0|0] "" IVI
  SG_ WheelStateFL : 44|3@0+ (1,0) [0|0] "" IVI
  SG_ WheelStateFR : 47|3@0+ (1,0) [0|0] "" IVI
  SG_ OldPressureFL : 50|1@0+ (1,0) [0|0] "" IVI
  SG_ OldPressureFR : 51|1@0+ (1,0) [0|0] "" IVI
  SG_ OldPressureRL : 52|1@0+ (1,0) [0|0] "" IVI
  SG_ OldPressureRR : 53|1@0+ (1,0) [0|0] "" IVI
  SG_ TPMS_AutoLocStatus : 55|2@0+ (1,0) [0|0] "" IVI

BO_ 1516 METER_UserSetPref_A2: 8 CGW
  SG_ LDW_SoundLevelRequest_v2 : 23|3@0+ (1,0) [0|0] "" IVI

BO_ 1519 IVI_A101: 8 IVI
  SG_ UserSettingCopySource : 2|3@0+ (1,0) [0|0] "" CGW
  SG_ UserSettingCopyTarget : 5|3@0+ (1,0) [0|0] "" CGW
  SG_ User5_RegistrationState : 8|1@0+ (1,0) [0|0] "" CGW
  SG_ User4_RegistrationState : 9|1@0+ (1,0) [0|0] "" CGW
  SG_ KeyLinkInitializationState : 10|1@0+ (1,0) [0|0] "" CGW
  SG_ KeyLinkActivationState : 11|1@0+ (1,0) [0|0] "" CGW
  SG_ User3_RegistrationState : 12|1@0+ (1,0) [0|0] "" CGW
  SG_ User2_RegistrationState : 13|1@0+ (1,0) [0|0] "" CGW
  SG_ User1_RegistrationState : 14|1@0+ (1,0) [0|0] "" CGW
  SG_ UserSettingCopyRequest : 15|1@0+ (1,0) [0|0] "" CGW
  SG_ ClimLinkFreshRecyAndAutoPush : 16|1@0+ (1,0) [0|1] "" CGW
  SG_ ADA1ActivationRequest2 : 18|2@0+ (1,0) [0|0] "" CGW
  SG_ ASAactivationRequest2 : 20|2@0+ (1,0) [0|0] "" CGW
  SG_ CurrentUserState_v2 : 23|3@0+ (1,0) [0|0] "" CGW
  SG_ SteeringSettingRequest2_v2 : 31|4@0+ (1,0) [0|0] "" CGW
  SG_ PowerTrainSettingRequest2 : 39|4@0+ (1,0) [0|0] "" CGW
  SG_ ClimAQSSensitivityRequest : 42|3@0+ (1,0) [0|0] "" CGW
  SG_ UserProfileResetRequest : 45|3@0+ (1,0) [0|0] "" CGW
  SG_ MC_ActivationRequest : 47|2@0+ (1,0) [0|0] "" CGW
  SG_ MC_PositionRecallRequest : 51|4@0+ (1,0) [0|0] "" CGW
  SG_ VMCSettingRequest : 55|4@0+ (1,0) [0|0] "" CGW
  SG_ MC_PositionCalculate : 59|4@0+ (1,0) [0|0] "" CGW
  SG_ MC_PositionSaveRequest : 63|4@0+ (1,0) [0|0] "" CGW

BO_ 1523 HEVC_R107: 3 CGW
  SG_ EcomodeRangeIncreaseDisplay : 7|8@0+ (1,0) [0|255] "" IVI
  SG_ HVbatInstantInputPower_v2 : 15|11@0+ (0.25,-255) [-255|255] "kW" IVI
  SG_ HVchargeDisplayState : 19|1@0+ (1,0) [0|0] "" IVI

BO_ 1526 HEVC_R110: 8 CGW
  SG_ PEBWaterTemp_BLMS : 7|8@0+ (1,-40) [-40|120] "°C" IVI
  SG_ CHG_FaultType_BLMS : 10|3@0+ (1,0) [0|0] "" IVI

BO_ 1529 IVI_UserSetPref_A3: 8 IVI
  SG_ HUD_ActivationRequest2 : 3|2@0+ (1,0) [0|0] "" CGW
  SG_ BSWson_ActivationRequest2 : 5|2@0+ (1,0) [0|0] "" CGW
  SG_ BCI_ActivationRequest2 : 7|2@0+ (1,0) [0|0] "" CGW
  SG_ ELKA_ActivationRequest2 : 18|2@0+ (1,0) [0|0] "" CGW
  SG_ HUD_PositionRequest2 : 23|5@0+ (1,0) [0|0] "" CGW
  SG_ FCW_SensibilityRequest2 : 26|3@0+ (1,0) [0|0] "" CGW
  SG_ HUD_NightLuminosityRequest2 : 39|5@0+ (1,0) [0|0] "" CGW
  SG_ WAL_ActivationRequest2 : 49|2@0+ (1,0) [0|0] "" CGW
  SG_ APPRUN_ActivationRequest2 : 63|2@0+ (1,0) [0|0] "" CGW

BO_ 1531 IVI_UserSetPref_A1: 8 IVI
  SG_ AutoFrontWiperActivationRequest2 : 1|2@0+ (1,0) [0|0] "" CGW
  SG_ AHL_ActivationRequest2 : 3|2@0+ (1,0) [0|0] "" CGW
  SG_ ParkAssistVolumeRequest2 : 7|3@0+ (1,0) [0|0] "" CGW
  SG_ IKeyAccessActivationRequest2 : 9|2@0+ (1,0) [0|0] "" CGW
  SG_ FrontRearWiperDropRequest2 : 11|2@0+ (1,0) [0|0] "" CGW
  SG_ FrontParkAssistActivationReq2 : 13|2@0+ (1,0) [0|0] "" CGW
  SG_ AutoRearWiperActivationRequest2 : 15|2@0+ (1,0) [0|0] "" CGW
  SG_ WGSactivationRequest2 : 16|2@0+ (1,0) [0|0] "" CGW
  SG_ SingleDoorOpeningActivationReq2 : 18|2@0+ (1,0) [0|0] "" CGW
  SG_ RearParkAssistActivationReq2 : 20|2@0+ (1,0) [0|0] "" CGW
  SG_ AutoLightSensitivityRequest2 : 23|3@0+ (1,0) [0|0] "" CGW
  SG_ AutoReLockActivationReq2 : 25|2@0+ (1,0) [0|0] "" CGW
  SG_ MotorwayFlashersNumberRequest2 : 28|3@0+ (1,0) [0|0] "" CGW
  SG_ AutoFMHactivationRequest2 : 30|2@0+ (1,0) [0|0] "" CGW
  SG_ SilentModeActivationRequest2 : 33|2@0+ (1,0) [0|0] "" CGW
  SG_ AutoLockActivationReq2 : 36|3@0+ (1,0) [0|0] "" CGW
  SG_ AutoUnLockActivationReq2 : 39|3@0+ (1,0) [0|0] "" CGW
  SG_ ParkAssistSensitivityRequest2 : 44|3@0+ (1,0) [0|0] "" CGW
  SG_ AutoFoldingActivationRequest2 : 47|3@0+ (1,0) [0|0] "" CGW
  SG_ PredictiveShiftActivationRequest2 : 49|2@0+ (1,0) [0|0] "" CGW
  SG_ AirCondEcoActivationRequest2 : 51|2@0+ (1,0) [0|0] "" CGW
  SG_ CruiseEcoActivationRequest2 : 55|2@0+ (1,0) [0|0] "" CGW
  SG_ AutoFMHdurationRequest2 : 59|4@0+ (1,0) [0|0] "" CGW
  SG_ ISS_EcoActivationRequest2 : 63|2@0+ (1,0) [0|0] "" CGW

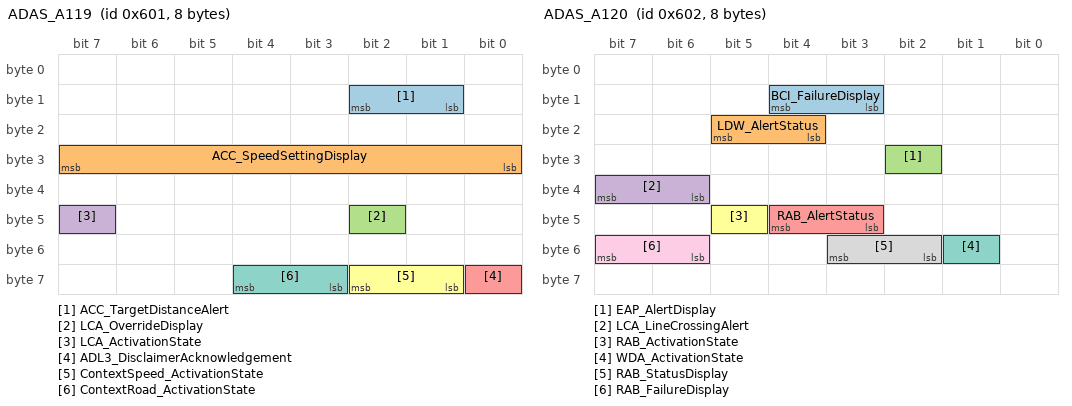
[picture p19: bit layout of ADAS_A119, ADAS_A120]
BO_ 1537 ADAS_A119: 8 CGW
  SG_ ACC_TargetDistanceAlert : 10|2@0+ (1,0) [0|0] "" IVI
  SG_ ACC_SpeedSettingDisplay : 31|8@0+ (1,0) [0|255] "wu" IVI
  SG_ LCA_OverrideDisplay : 42|1@0+ (1,0) [0|0] "" IVI
  SG_ LCA_ActivationState : 47|1@0+ (1,0) [0|0] "" IVI
  SG_ ADL3_DisclaimerAcknowledgement : 56|1@0+ (1,0) [0|0] "" IVI
  SG_ ContextSpeed_ActivationState : 58|2@0+ (1,0) [0|0] "" IVI
  SG_ ContextRoad_ActivationState : 60|2@0+ (1,0) [0|0] "" IVI

BO_ 1538 ADAS_A120: 8 CGW
  SG_ BCI_FailureDisplay : 12|2@0+ (1,0) [0|0] "" IVI
  SG_ LDW_AlertStatus : 21|2@0+ (1,0) [0|0] "" IVI
  SG_ EAP_AlertDisplay : 26|1@0+ (1,0) [0|0] "" IVI
  SG_ LCA_LineCrossingAlert : 39|2@0+ (1,0) [0|0] "" IVI
  SG_ RAB_AlertStatus : 44|2@0+ (1,0) [0|0] "" IVI
  SG_ RAB_ActivationState : 45|1@0+ (1,0) [0|0] "" IVI
  SG_ WDA_ActivationState : 49|1@0+ (1,0) [0|0] "" IVI
  SG_ RAB_StatusDisplay : 51|2@0+ (1,0) [0|0] "" IVI
  SG_ RAB_FailureDisplay : 55|2@0+ (1,0) [0|0] "" IVI

CM_ BO_ 1386 "[C1AHS-T3-2017]: Specific C1A  frame";
VAL_ 1330 GeneralRecordingStatus 0 "turn on" 1 "turn off";
VAL_ 1330 SDCardStatus 0 "SD insert" 1 "SD pull out" 2 "SD failure" 3 "SD full" 4 "emergency video full" 5 "photo full" 6 "emergency video and photo full" 7 "Need format";
VAL_ 1330 DVRWorkStatus 0 "general recording mode" 1 "stop recording mode" 2 "manually start emergency video mode" 3 "auto start emergency video mode" 4 "general video list mode" 5 "emergency video list mode" 6 "photo list mode" 7 "video file playing status" 8 "video file paused status" 9 "photo file playing status" 10 "video playing end" 11 "power off status" 12 "system failure" 13 "inside monitoring mode" 14 "file is exporting" 15 "invalid value";
VAL_ 1330 LanguageStatus 0 "chinese" 1 "english" 2 "Not used" 3 "invalid value";
VAL_ 1330 FolderStatus 0 "only one page" 1 "current is the first page" 2 "current is the last page" 3 "invalid value";
VAL_ 1330 FileStatus 0 "no file" 1 "only one file" 2 "current is the first file" 3 "current is the last file" 4 "Not used" 5 "Not used" 6 "Not used" 7 "invalid value";
VAL_ 1330 PhotoReady 0 "pictures are ready" 1 "No picture";
VAL_ 1330 CollideCheckStatus 0 "turn off collision detection" 1 "turn on collision detection" 2 "reserved" 3 "invalid value";
VAL_ 1330 ParkingMonitor 0 "turn off parking monitoring" 1 "turn on parking monitoring" 2 "reserved" 3 "invalid value";
VAL_ 1330 CollideSensitivityStatus 0 "low sensibility" 1 "medium sensibility" 2 "high sensibility" 3 "invalid value";
VAL_ 1330 MuteRecordStatus 0 "turn off recording" 1 "turn on recording" 2 "reserved" 3 "invalid value";
VAL_ 1330 SuperpositionSpeedShow 0 "turn off overlay display" 1 "turn on overlay display" 2 "reserved" 3 "invalid value";
VAL_ 1330 SuperpositionOthersShow 0 "turn off overlay display" 1 "turn on overlay display" 2 "reserved" 3 "invalid value";
VAL_ 1330 RecordVideoQuality 0 "1080P-30fps" 1 "720P-30fps" 2 "reserved" 3 "invalid value";
VAL_ 1330 RecordTime 0 "1min" 1 "3min" 2 "5min" 3 "invalid value";
VAL_ 1330 WiFiStatus 0 "turn on" 1 "turn off";
VAL_ 1330 DVR_FileSelectStatus 0 "File selected" 1 "File unselected";
VAL_ 1330 NetworkStatus 0 "Connection Successful" 1 "Initialization failed" 2 "No available AP found" 3 "Authentication failed" 4 "Connection refused" 5 "Connection failed" 6 "SSID checksum error" 7 "Passwd checksum error" 8 "reserved" 9 "reserved" 10 "reserved" 11 "reserved" 12 "reserved" 13 "reserved" 14 "reserved" 15 "invalid value";
VAL_ 1330 SelftimerState 0 "Unavailable" 1 "Timer1" 2 "Timer2" 3 "Timer3";
VAL_ 1330 ContrastStateRRcam 0 "Unavailable" 1 "Level1" 2 "Level2" 3 "Level3" 4 "Level4" 5 "Level5" 6 "Not Used" 7 "Not Used";
VAL_ 1330 ContrastStateFRcam 0 "Unavailable" 1 "Level1" 2 "Level2" 3 "Level3" 4 "Level4" 5 "Level5" 6 "Not Used" 7 "Not Used";
VAL_ 1330 NetworkStatus_CameraAngle 0 "camera angle can be changed" 1 "camera right angle limitation" 2 "camera left angle limitation" 3 "invalid value";
VAL_ 1330 BrightnessStateRRcam 0 "Unavailable" 1 "Level1" 2 "Level2" 3 "Level3" 4 "Level4" 5 "Level5" 6 "Not Used" 7 "Not Used";
VAL_ 1330 BrightnessStateINcam 0 "Unavailable" 1 "Level1" 2 "Level2" 3 "Level3" 4 "Level4" 5 "Level5" 6 "Not Used" 7 "Not Used";
VAL_ 1330 NetworkStatus_CameraView 0 "invalid value" 1 "FR camera is displayed" 2 "RR camera is displayed" 3 "INCAM is displayed";
VAL_ 1330 ContrastStateINcam 0 "Unavailable" 1 "Level1" 2 "Level2" 3 "Level3" 4 "Level4" 5 "Level5" 6 "Not Used" 7 "Not Used";
VAL_ 1330 BrightnessState 0 "Unavailable" 1 "Level1" 2 "Level2" 3 "Level3" 4 "Level4" 5 "Level5" 6 "Not Used" 7 "Not Used";
VAL_ 1331 DVR_CommandResult 0 "Command reception success" 1 "Command reception Failed" 2 "Successful implementation" 3 "Execution failure" 4 "reserved" 5 "reserved" 6 "reserved" 7 "invalid value";
VAL_ 1331 DVR_CommandRespList 0 "enter general video" 1 "stop recorded" 2 "enter emergency video" 3 "enter general video directory" 4 "enter emergency video directory" 5 "enter picture directory" 6 "format SD" 7 "factory reset" 8 "photograph" 9 "move file" 10 "deleted file" 11 "turn on video" 12 "play/pause" 13 "format eMMC (reserved)" 14 "play the previous file" 15 "play the next file" 16 "exit play" 17 "filesselected 1" 18 "filesselected 2" 19 "filesselected 3" 20 "filesselected 4" 21 "filesselected 5" 22 "filesselected 6" 23 "filesselected 7" 24 "filesselected 8" 25 "filesselected 9" 26 "select all" 27 "cancel" 28 "previous" 29 "next" 30 "Enable Update" 31 "invalid value";
VAL_ 1331 DVRSystemVersion_Major 0 "Major version number is zero" 1 "Major version number is one" 2 "Major version number is two" 3 "invalid value";
VAL_ 1331 WifiAuthenticationRequest 0 "Request DA to send SSID and Password" 1 "No request";
VAL_ 1331 UpdateStatus 0 "Need to update software" 1 "MCU updating" 2 "DSP updating" 3 "update successful" 4 "update fail" 5 "reserved" 6 "reserved" 7 "invalid value";
VAL_ 1331 DVRSystemVersion_MCU 0 "MCU version number is zero" 1 "MCU version number is one" 2 "MCU version number is two" 3 "MCU version number is three" 4 "MCU version number is four" 5 "MCU version number is five" 6 "MCU version number is six" 7 "MCU version number is seven" 8 "MCU version number is eight" 9 "MCU version number is nine" 10 "reserved" 11 "reserved" 12 "reserved" 13 "reserved" 14 "reserved" 15 "invalid value";
VAL_ 1331 DVRSystemVersion_DSP 0 "DSP version number is zero" 1 "DSP version number is one" 2 "DSP version number is two" 3 "DSP version number is three" 4 "DSP version number is four" 5 "DSP version number is five" 6 "DSP version number is six" 7 "DSP version number is seven" 8 "DSP version number is eight" 9 "DSP version number is nine" 10 "reserved" 11 "reserved" 12 "reserved" 13 "reserved" 14 "reserved" 15 "invalid value";
VAL_ 1331 DVR_CommandRespList_2 0 "Taking inner camera photo" 1 "Taking inner camera video" 2 "Fast forward 10 sec" 3 "Fast forward 20 sec" 4 "Fast rewind 10 sec" 5 "Fast rewind 20 sec" 6 "Play back progress 0%" 7 "Play back progress 10%" 8 "Play back progress 20%" 9 "Play back progress 30%" 10 "Play back progress 40%" 11 "Play back progress 50%" 12 "Play back progress 60%" 13 "Play back progress 70%" 14 "Play back progress 80%" 15 "Play back progress 90%" 16 "Play back progress 100%" 17 "Not Used" 18 "Not Used" 19 "Not Used" 20 "Not Used" 21 "Not Used" 22 "Not Used" 23 "Not Used" 24 "Not Used" 25 "Not Used" 26 "Not Used" 27 "Not Used" 28 "Not Used" 29 "Not Used" 30 "Not Used" 31 "Not Used";
VAL_ 1331 DVR_RemoteCommandResult 0 "Successful implementation" 1 "Execution failure" 2 "reserved" 3 "invalid value";
VAL_ 1332 AIRBAGMalfunction 0 "no AIRBAG system malfunction" 1 "AIRBAG system malfunction";
VAL_ 1332 SecondRowCenterPresenceState 0 "Not monitored" 1 "Present" 2 "Absent" 3 "Unknown";
VAL_ 1332 PassengerSafetyBeltBuckleState 0 "SB Not monitored" 1 "SB unfastened" 2 "SB fastened" 3 "Unavailable";
VAL_ 1332 PassengerPresenceState 0 "Not monitored" 1 "Present" 2 "Absent" 3 "Unknown";
VAL_ 1332 SecondRowRightPresenceState 0 "Not monitored" 1 "Present" 2 "Absent" 3 "Unknown";
VAL_ 1332 SecondRowLeftSafetyBeltState 0 "SB not monitored" 1 "SB unfastened" 2 "SB fastened" 3 "Unavailable";
VAL_ 1332 SecondRowLeftPresenceState 0 "Not monitored" 1 "Present" 2 "Absent" 3 "Unknown";
VAL_ 1332 SecondRowCenterSafetyBeltState 0 "SB not monitored" 1 "SB unfastened" 2 "SB fastened" 3 "Unavailable";
VAL_ 1332 ThirdRowCenterSafetyBeltState 0 "SB not monitored" 1 "SB unfastened" 2 "SB fastened" 3 "Unavailable";
VAL_ 1332 SecondRowRightSafetyBeltState 0 "SB not monitored" 1 "SB unfastened" 2 "SB fastened" 3 "Unavailable";
VAL_ 1332 ThirdRowRightSafetyBeltState 0 "SB not monitored" 1 "SB unfastened" 2 "SB fastened" 3 "Unavailable";
VAL_ 1332 ThirdRowLeftSafetyBeltState 0 "SB not monitored" 1 "SB unfastened" 2 "SB fastened" 3 "Unavailable";
VAL_ 1332 FirstRowCenterSafetyBeltState 0 "SB Not monitored" 1 "SB unfastened" 2 "SB fastened" 3 "Unavailable";
VAL_ 1334 RouteID 0 "No route available" 1 "Route 1" 2 "Route 2" 3 "Route 3" 4 "Route 4" 5 "Route 5" 6 "Route 6" 7 "Route 7";
VAL_ 1334 RouteStatus 0 "Not Available" 1 "Route under calculation" 2 "Route Available From User Input" 3 "Route Available From Estimation" 4 "GPS Signal Lost" 5 "Driver Stopped Following the Route" 6 "Not used" 7 "Not used";
VAL_ 1334 UrbanZevDrivingOption 0 "No ZEV urban mode preference" 1 "ZEV urban mode preference";
VAL_ 1335 SegmentRoadType 0 "Highway" 1 "Freeway" 2 "Rural" 3 "Urban" 4 "Residential" 5 "Service" 6 "Other/unknown" 7 "Unavailable";
VAL_ 1335 SegmentInMandatoryZEVzone 0 "No restrictions" 1 "Segment In Mandatory ZEV Zone";
VAL_ 1339 TimeWeekDay 0 "Monday" 1 "Tuesday" 2 "Wednesday" 3 "Thursday" 4 "Friday" 5 "Saturday" 6 "Sunday" 7 "Unavailable";
VAL_ 1341 UPA_SoundRecurrenceType 0 "Discontinuous sound" 1 "Continuous sound";
VAL_ 1341 UPA_SystemState 0 "Manoeuvring Mode" 1 "Normal Mode" 2 "Standby Mode" 3 "Error Mode";
VAL_ 1341 UPA_Obstacle_Zone_Front_Right 0 "No detection" 1 "Reserve" 2 "Detect level 2 (70~50cm)" 3 "Detect level 3 (50~30cm)" 4 "Detect level 4 (30~cm)" 5 "Detect level 5" 6 "Reserve" 7 "Unavailable";
VAL_ 1341 UPA_Obstacle_Zone_Front_Left 0 "No detection" 1 "Reserve" 2 "Detect level 2 (70~50cm)" 3 "Detect level 3 (50~30cm)" 4 "Detect level 4 (30~cm)" 5 "Detect level 5" 6 "Reserve" 7 "Unavailable";
VAL_ 1341 UPA_Image_DisplayRequest 0 "No display request" 1 "Rear Detection ON" 2 "Front Detection ON" 3 "Front and Rear Detection ON";
VAL_ 1341 UPA_Obstacle_Zone_Rear_Right 0 "No detection" 1 "Detect level 1 (~70cm)" 2 "Detect level 2 (70~50cm)" 3 "Detect level 3 (50~30cm)" 4 "Detect level 4 (30~cm)" 5 "Detect level 5" 6 "Reserve" 7 "Unavailable";
VAL_ 1341 UPA_Obstacle_Zone_Rear_Left 0 "No detection" 1 "Detect level 1 (~70cm)" 2 "Detect level 2 (70~50cm)" 3 "Detect level 3 (50~30cm)" 4 "Detect level 4 (30~cm)" 5 "Detect level 5" 6 "Reserve" 7 "Unavailable";
VAL_ 1341 UPA_SoundActivationBeep 0 "No Request" 1 "Request";
VAL_ 1341 UPA_SoundErrorBeep 0 "No error sound" 1 "Error sound";
VAL_ 1341 UPA_Obstacle_Zone_Rear_Center 0 "No detection" 1 "Detect level 1 (   ~70cm)" 2 "Detect level 2 (70~50cm)" 3 "Detect level 3 (50~30cm)" 4 "Detect level 4 (30~cm)" 5 "Detect level 5" 6 "Reserve" 7 "Unavailable";
VAL_ 1341 UPA_Obstacle_Zone_Front_Center 0 "No detection" 1 "Detect level 1 (   ~70cm)" 2 "Detect level 2 (70~50cm)" 3 "Detect level 3 (50~30cm)" 4 "Detect level 4 (30~cm)" 5 "Detect level 5" 6 "Reserve" 7 "Unavailable";
VAL_ 1341 SensorAvailabilityFrontLeft 0 "Sensor not available" 1 "Sensor available";
VAL_ 1341 SensorAvailabilityFrontCenter 0 "Sensor not available" 1 "Sensor available";
VAL_ 1341 UPA_SoundObstacleZone 0 "No Sound" 1 "Sound front left" 2 "Sound front center" 3 "Sound front right" 4 "Sound rear left" 5 "Sound rear center" 6 "Sound rear right" 7 "reserved";
VAL_ 1341 UPAStatusDisplayRequest 0 "no upa status display request" 1 "Rear and front UPA de-activated" 2 "Rear UPA de-activated and front UPA activated" 3 "Not used" 4 "Rear UPA activated and front UPA de-activated" 5 "Sonar temporarily unavailable" 6 "Rear and front UPA activated" 7 "System Error";
VAL_ 1341 SensorAvailabilityFrontRight 0 "Sensor not available" 1 "Sensor available";
VAL_ 1341 SonarObstacleDistanceDisplay 0 "No detect / No display" 1 "Distance 1" 2 "Distance 2" 3 "Distance 3" 4 "Distance 4" 5 "Distance 5" 6 "Distance 6" 7 "Distance 7" 8 "Distance 8" 9 "Distance 9" 10 "Distance 10" 11 "Distance 11" 12 "Distance 12" 13 "Reserved" 14 "Reserved" 15 "Reserved";
VAL_ 1341 ParkAssistVolumeState 0 "Level 0 (off)" 1 "Level 1" 2 "Level 2" 3 "Level 3" 4 "Level 4" 5 "Level 5" 6 "Not used" 7 "Not used";
VAL_ 1341 SensorAvailabilityRearRight 0 "Sensor not available" 1 "Sensor available";
VAL_ 1341 SensorAvailabilityRearLeft 0 "Sensor not available" 1 "Sensor available";
VAL_ 1341 SensorAvailabilityRearCenter 0 "Sensor not available" 1 "Sensor available";
VAL_ 1341 UPA_ClosingAuthorization 0 "Not authorized" 1 "Authorized";
VAL_ 1345 Fatigue_CustomShieldRequest 0 "No request" 1 "Fatigue activation request" 2 "Fatigue deactivation request" 3 "Reset request";
VAL_ 1345 Distraction_CustomShieldRequest 0 "No request" 1 "Distraction activation request" 2 "Distraction deactivation request" 3 "Reset request";
VAL_ 1354 PSD_R_AuthorizationState 0 "PSDNotAuthorized_AllMovementsInhibited" 1 "PSDAuthorized_AllMovementsAuthorized" 2 "PSDFailure_AllMovementsInhibited" 3 "Not Used";
VAL_ 1354 PSD_R_ActivationState 0 "No activation" 1 "Opening_movement_ongoing" 2 "Closing_movement_ongoing" 3 "Movement_delayed" 4 "Antipinch_movement_ongoing" 5 "Not Used" 6 "Not Used" 7 "Not Used";
VAL_ 1354 PSD_R_ResponseState 0 "No activation" 1 "ActivationRequest_Accepted" 2 "ActivationRequest_Completed" 3 "ActivationRequest_Rejected_Underqualified" 4 "Failure_detected" 5 "Antipinch_detected" 6 "Not Used" 7 "Not Used";
VAL_ 1355 RearRightMassageProgramState 0 "Massage not Running" 1 "Program 1 running" 2 "Program 2 running" 3 "Program 3 running" 4 "Program 4 running" 5 "Program 5 running" 6 "Program 6 running" 7 "Program 7 running" 8 "Program 8 running" 9 "Program 9 running" 10 "Program 10 running" 11 "Program 11 running" 12 "Program 12 running" 13 "Program 13 running" 14 "Program 14 running" 15 "Not used";
VAL_ 1355 RearRightMassageActivationState 0 "Massage OFF" 1 "Massage ON";
VAL_ 1355 RearLeftMassageActivationState 0 "Massage OFF" 1 "Massage ON";
VAL_ 1355 RearRightAutoReturnState 0 "AutoReturn OFF" 1 "AutoReturn ON";
VAL_ 1355 RearLeftAutoReturnState 0 "AutoReturn OFF" 1 "AutoReturn ON";
VAL_ 1355 RearLeftMassageVelocityState 0 "No velocity" 1 "velocity 1" 2 "velocity 2" 3 "velocity 3" 4 "velocity 4" 5 "velocity 5" 6 "Not Used" 7 "Not Used";
VAL_ 1355 RearRightMassageIntensityState 0 "No intensity" 1 "Intensity 1" 2 "Intensity 2" 3 "Intensity 3" 4 "Intensity 4" 5 "Intensity 5" 6 "Not Used" 7 "Not Used";
VAL_ 1355 RearLeftMassageProgramState 0 "Massage not Running" 1 "Program 1 running" 2 "Program 2 running" 3 "Program 3 running" 4 "Program 4 running" 5 "Program 5 running" 6 "Program 6 running" 7 "Program 7 running" 8 "Program 8 running" 9 "Program 9 running" 10 "Program 10 running" 11 "Program 11 running" 12 "Program 12 running" 13 "Program 13 running" 14 "Program 14 running" 15 "Not used";
VAL_ 1355 RearRightMassageVelocityState 0 "No velocity" 1 "velocity 1" 2 "velocity 2" 3 "velocity 3" 4 "velocity 4" 5 "velocity 5" 6 "Not Used" 7 "Not Used";
VAL_ 1355 Rear2LeftSeatFoldUnfoldState 0 "fixed position" 1 "on going" 2 "not used" 3 "unavailable";
VAL_ 1355 Rear2RightSeatFoldUnfoldState 0 "fixed position" 1 "on going" 2 "not used" 3 "unavailable";
VAL_ 1355 RearLeftMassageIntensityState 0 "No intensity" 1 "Intensity 1" 2 "Intensity 2" 3 "Intensity 3" 4 "Intensity 4" 5 "Intensity 5" 6 "Not Used" 7 "Not Used";
VAL_ 1355 Rear2LeftSeatWalkinState 0 "fixed position" 1 "on going" 2 "not used" 3 "unavailable";
VAL_ 1355 Rear2RightSeatWalkinState 0 "fixed position" 1 "on going" 2 "not used" 3 "unavailable";
VAL_ 1355 Rear2RightSeatMovingState 0 "Not moving" 1 "Seat manual moving" 2 "Anti pinch detection" 3 "Walkin lock open" 4 "During walkin forward" 5 "During walkin backward" 6 "During folding" 7 "During unfolding";
VAL_ 1355 Rear2LeftSeatMovingState 0 "Not moving" 1 "Seat manual moving" 2 "Anti pinch detection" 3 "Walkin lock open" 4 "During walkin forward" 5 "During walkin backward" 6 "During folding" 7 "During unfolding";
VAL_ 1356 ADASISv2_POSITION 0 "Table Value30477";
VAL_ 1359 ERP_GuidanceOnGoing 0 "No Navigation" 1 "Navigation on-going" 2 "Re-routing" 3 "Not used";
VAL_ 1361 LCDN_ActivationState 0 "Unavailable" 1 "Activated" 2 "Deactivated" 3 "Not used";
VAL_ 1361 ACC_TargetDistanceAlert_v2 0 "No ACC warning" 1 "ACC approach warning" 2 "ACC collision warning" 3 "ACC cancel warning" 4 "ACC alert reminder" 5 "Not used" 6 "Not used" 7 "Not used";
VAL_ 1361 LCDN_SensibilityState 0 "Unavailable" 1 "Low sensibility" 2 "Middle sensibility" 3 "High sensibility";
VAL_ 1361 ELKA_OTOC_ActivationState 0 "Activated" 1 "Deactivated";
VAL_ 1361 LKA_DL_ActivationState 0 "Activated" 1 "Deactivated";
VAL_ 1361 ELKS_ActivationState 0 "Activated" 1 "Deactivated";
VAL_ 1364 ClimVariableAirFlowDisplay 0 "No display" 1 "Level 1" 2 "Level 2" 3 "Level 3" 4 "Level 4" 5 "Level 5" 6 "OFF" 7 "Not used";
VAL_ 1364 ClimRearOFFModeDisplay 0 "No display" 1 "OFF Mode Activated Display";
VAL_ 1364 ClimRearLockStatus 0 "No display" 1 "Rear climate lock display" 2 "Rear climate unlock display" 3 "Not used";
VAL_ 1364 ClimLinkPrio3rdLSeatAutoDisp 0 "No display" 1 "Level 1" 2 "Level 2" 3 "Level 3" 4 "Level 4" 5 "Level 5" 6 "OFF" 7 "Not Used";
VAL_ 1364 ClimIRSensorOn_Display 0 "No display" 1 "IR sensing function link to Auto ON" 2 "IR sensing function link to Auto OFF" 3 "Not Used";
VAL_ 1364 ClimLinkPriorityRRSeatAutoDisp 0 "No display" 1 "Level 1" 2 "Level 2" 3 "Level 3" 4 "Level 4" 5 "Level 5" 6 "OFF" 7 "Not used";
VAL_ 1364 ProactiveRecyclingStatus 0 "Proactive prohibited" 1 "Proactive authorized";
VAL_ 1364 ClimAllSeatAutoDisplay 0 "No display" 1 "Auto activated" 2 "Auto not activated" 3 "Not Used";
VAL_ 1364 ClimLinkPrio3rdRSeatAutoDisp 0 "No display" 1 "Level 1" 2 "Level 2" 3 "Level 3" 4 "Level 4" 5 "Level 5" 6 "OFF" 7 "Not Used";
VAL_ 1364 ClimRearOFFModeDisplayStatus 0 "Function not available" 1 "Function available";
VAL_ 1364 ClimRearLockDisplayStatus 0 "Function not available" 1 "Function available";
VAL_ 1364 RecyPollutionStatus 0 "No Pollution" 1 "Pollution limited" 2 "Pollution protected" 3 "Unavailable value";
VAL_ 1364 SecondRightSeatModeDisp 0 "No display" 1 "Seat Heater" 2 "Seat Ventilation" 3 "Not used";
VAL_ 1364 SecondLeftSeatModeDisp 0 "No display" 1 "Seat Heater" 2 "Seat Ventilation" 3 "Not used";
VAL_ 1364 FrontRightSeatModeDisp 0 "No display" 1 "Seat Heater" 2 "Seat Ventilation" 3 "Not used";
VAL_ 1364 FrontLeftSeatModeDisp 0 "No display" 1 "Seat Heater" 2 "Seat Ventilation" 3 "Not used";
VAL_ 1364 ClimLinkOccupantForSeatDisplay 0 "No display" 1 "SeatOccupantLink ON" 2 "SeatOccupantLink OFF" 3 "Not Used";
VAL_ 1364 ClimLinkOccupantForDRZoneDisp 0 "No display" 1 "DRZNOccupantLink ON" 2 "DRZNOccupantLink OFF" 3 "Not Used";
VAL_ 1364 ClimShortcutRequest 0 "NoRequest" 1 "FrControlPanel" 2 "RrControlPanel" 3 "FrontLeftSeat" 4 "FrontRightSeat" 5 "FrontLeftSeat and FrontRightSeat" 6 "RearLeftSeat" 7 "RearRightSeat" 8 "RearLeftSeat and RearRightSeat" 9 "Not used" 10 "Not used" 11 "Not used" 12 "Not used" 13 "Not used" 14 "Not used" 15 "Not used";
VAL_ 1364 ClimPartialAutoState 0 "Manual" 1 "FAN AUTO";
VAL_ 1365 FAPK_DefaultManeuverTypeState 0 "Not Used" 1 "park in / parallel" 2 "park in / perpendicular" 3 "park in / angled" 4 "mode auto" 5 "Not Used" 6 "Not Used" 7 "Unavailable";
VAL_ 1365 ZoomAutoActivationState 0 "Zoom auto Deactivated" 1 "Zoom auto Activated";
VAL_ 1365 AVM_GuidelineActivationState 0 "Static and Dynamic Guideline Deactivated" 1 "Static Guideline Activated" 2 "Dynamic Guideline Activated" 3 "Static and Dynamic Guideline Activated" 4 "Not Used" 5 "Not Used" 6 "Not Used" 7 "Unavailable";
VAL_ 1365 AVM_ActivationStatus 0 "No request" 1 "Impossible to execute request" 2 "Operational" 3 "Not Used";
VAL_ 1365 APA_ManeuverFeedback 0 "No request" 1 "Feedback 1" 2 "Feedback 2" 3 "Unavailable";
VAL_ 1365 AVM_MegaStatus 0 "Not support" 1 "OFF" 2 "ON" 3 "Reserved";
VAL_ 1365 AVM_FeedbackFocusStatus 0 "FocusL0FeedbackStatus" 1 "FocusL1FeedbackStatus";
VAL_ 1365 AVM_AttractFocusStatus 0 "AttractLevel1FocusStatus" 1 "AttractLevel2FocusStatus";
VAL_ 1365 APAStart_SwitchStatus 0 "No display" 1 "unusable" 2 "display switch" 3 "display switch maneuver1" 4 "display switch maneuver2" 5 "display switch maneuver3" 6 "display switch maneuver4" 7 "display switch maneuver5";
VAL_ 1365 AVM_RegisterRequest 0 "Not requested" 1 "Requested";
VAL_ 1365 AVM_MegaRequest 0 "Not requested" 1 "Requested";
VAL_ 1365 RPKStart_SwitchStatus 0 "No display" 1 "unusable" 2 "display switch" 3 "display switch maneuver1" 4 "display switch maneuver2" 5 "display switch maneuver3" 6 "display switch maneuver4" 7 "display switch maneuver5";
VAL_ 1369 OSE_RearRightDoorAlert 0 "No alert" 1 "Level1" 2 "Level2" 3 "Not Used";
VAL_ 1369 OSE_RearLeftDoorAlert 0 "No alert" 1 "Level1" 2 "Level2" 3 "Not Used";
VAL_ 1369 OSE_FrontLeftDoorAlert 0 "No alert" 1 "Level1" 2 "Level2" 3 "Not Used";
VAL_ 1369 OSE_FronRightDoorAlert 0 "No alert" 1 "Level1" 2 "Level2" 3 "Not Used";
VAL_ 1369 ELKA_AlertLeftRequest 0 "No Alert" 1 "Oncoming Alert level 1" 2 "Oncoming Alert level 2" 3 "Overtaking Alert level 1" 4 "Overtaking Alert level 2" 5 "Roadedge Alert level 1" 6 "Roadedge Alert level 2" 7 "Alert reminder";
VAL_ 1369 ELKA_AlertRightRequest 0 "No Alert" 1 "Oncoming Alert level 1" 2 "Oncoming Alert level 2" 3 "Overtaking Alert level 1" 4 "Overtaking Alert level 2" 5 "Roadedge Alert level 1" 6 "Roadedge Alert level 2" 7 "Alert reminder";
VAL_ 1369 ADAS_LinkFailureRequest 0 "No request" 1 "Request";
VAL_ 1369 ADAS_BranchDirection 0 "No branch" 1 "Left branch" 2 "Right branch" 3 "Not Used";
VAL_ 1369 OSE_ActivationState 0 "Activated" 1 "Deactivated";
VAL_ 1369 ELKA_ActivationState 0 "Activated" 1 "Deactivated";
VAL_ 1369 EgoCarCenteringPosition 0 "Not Operative" 1 "Operative Left" 2 "Operative Center" 3 "Operative Right";
VAL_ 1369 SET_MAPAutoUpdate_State 0 "Invalid" 1 "OFF" 2 "ON" 3 "Not used";
VAL_ 1369 SET_FocusState_State 0 "Invalid" 1 "OFF" 2 "ON" 3 "Not used";
VAL_ 1369 SET_ADL3_State 0 "Invalid" 1 "OFF" 2 "ON" 3 "Not used";
VAL_ 1369 SET_ALCP2P_AlertLevel_State 0 "Invalid" 1 "Lv1" 2 "Lv2" 3 "Lv3";
VAL_ 1376 ChargeTimeDisplayAtEPrct 0 "No Display";
VAL_ 1380 TripUnitConsumption 0 "L / 100 km and kWh/100km" 1 "Km / L and km/kWh" 2 "MPGus and M/kWh (MPGe)" 3 "MPGuk and M/kWh (MPGe)" 4 "KWh / 100 Km" 5 "KWh / 100 miles" 6 "MPGe (US)" 7 "MPGe (UK)";
VAL_ 1380 FrostWarningDisplay 0 "No alert" 1 "Frost warning Alert";
VAL_ 1380 TripUnitDistance 0 "Km" 1 "Miles" 2 "not used" 3 "not used";
VAL_ 1380 MeterLanguageStatus 0 "Unavailable value" 1 "Language 1 à 253" 255 "Not used";
VAL_ 1380 Meter_FOTA_status 0 "Idle" 1 "Installation in progress" 2 "Copying in progress" 3 "Vehicle Condition check in progress" 4 "Ready for activation" 5 "Switch in progress" 6 "Reboot in progress" 7 "Component version check in progress" 8 "Configuration install in progress" 9 "Activation complete" 10 "Cancel in progress" 11 "Error detected" 12 "Update Error detected" 13 "Rollback in progress" 14 "Rollback complete" 15 "Ready for Slave Distribution" 16 "Slave Distribution in progress" 17 "Slave Integrity check in progress" 18 "Slave Distribution complete" 19 "Slave Installation in progress" 20 "Slave Copying in progress" 21 "Slave Installation complete" 22 "Not used" 23 "Not used" 24 "Not used" 25 "Not used" 26 "Not used" 27 "Not used" 28 "Not used" 29 "Not used" 30 "Not used" 31 "invalid";
VAL_ 1381 BSWrad_ActivationState 0 "Activated" 1 "Deactivated";
VAL_ 1381 CTA_AlertStatus 0 "No alert" 1 "Right alert" 2 "Left alert" 3 "Right and Left alert";
VAL_ 1381 CTA_CollisionRiskAlert 0 "Low collision risk" 1 "High collision risk";
VAL_ 1384 MexModeState_v3 0 "Unavailable" 1 "MEX MODE ECO" 2 "MEX MODE MUD" 3 "MEX MODE MY SENSE" 4 "MEX MODE SPORT" 5 "Reserved" 6 "MEX MODE ECOPLUS" 7 "MEX MODE SNOW" 8 "MEX MODE OFFROAD" 9 "MEX MODE ALLROADS" 10 "MEX MODE PERSO" 11 "MEX MODE SAND" 12 "MEX MODE RACE" 13 "MEX MODE NORMAL" 14 "MEX MODE EXTREM" 15 "MEX MODE PERFO";
VAL_ 1384 MexAutoState 0 "Auto-adaptive function not active" 1 "Auto-adaptive function active";
VAL_ 1384 ADBSettingRequest 0 "No request" 1 "Mode 1 (Normal)" 2 "Mode 2 (Sport)" 3 "Mode 3" 4 "Mode 4" 5 "Mode 5" 6 "Mode 6" 7 "Reset Request";
VAL_ 1384 CurrentSpecificUserState 0 "No specific mode" 1 "Valet mode" 2 "Beginner mode" 3 "Not used";
VAL_ 1384 VDCSettingRequest 0 "No request" 1 "Mode 1" 2 "Mode 2" 3 "Mode 3" 4 "Mode 4" 5 "Mode 5" 6 "Mode 6" 7 "Mode 7" 8 "Mode 8" 9 "Mode 9" 10 "Mode 10" 11 "Mode 11" 12 "Mode 12" 13 "Mode 13" 14 "Mode 14" 15 "Reset Request";
VAL_ 1384 ClimLeftFlowDistrRequest 0 "No request" 1 "Feet" 2 "Vent" 3 "Vent + Feet" 4 "Defrost" 5 "Defrost + Feet" 6 "Defrost + Vent" 7 "Defrost + Vent + Feet";
VAL_ 1384 ClimRearLockRequest 0 "No request" 1 "Rear climate lock request" 2 "Rear climate unlock request" 3 "Reset request";
VAL_ 1384 ClimRearLeftFlowDistRequest 0 "No request" 1 "Feet" 2 "Vent" 3 "Vent + Feet" 4 "Defrost" 5 "Defrost + Feet" 6 "Defrost + Vent" 7 "Defrost + Vent + Feet";
VAL_ 1384 ClimRearRightFlowDistRequest 0 "No request" 1 "Feet" 2 "Vent" 3 "Vent + Feet" 4 "Defrost" 5 "Defrost + Feet" 6 "Defrost + Vent" 7 "Defrost + Vent + Feet";
VAL_ 1384 FrontLeftSeatAutoRequest 0 "No request" 1 "Auto mode activation" 2 "Auto mode deactivation" 3 "Reset request";
VAL_ 1384 ClimRecyclingModeRequest 0 "No request" 1 "Fresh" 2 "Auto" 3 "Recycling" 4 "Auto + Fresh" 5 "Auto + Recycling" 6 "Not Used" 7 "Not Used";
VAL_ 1384 ClimLinkPrioRearSeatsAutoReq 0 "No request" 1 "Level 1" 2 "Level 2" 3 "Level 3" 4 "Level 4" 5 "Level 5" 6 "OFF request" 7 "Reset request";
VAL_ 1384 FrontRightSeatAutoRequest 0 "No request" 1 "Auto mode activation" 2 "Auto mode deactivation" 3 "Reset request";
VAL_ 1384 ClimVariableAirFlowRequest 0 "No request" 1 "Level 1" 2 "Level 2" 3 "Level 3" 4 "Level 4" 5 "Level 5" 6 "OFF request" 7 "Reset request";
VAL_ 1384 ClimRightFlowDistrRequest 0 "No request" 1 "Feet" 2 "Vent" 3 "Vent + Feet" 4 "Defrost" 5 "Defrost + Feet" 6 "Defrost + Vent" 7 "Defrost + Vent + Feet";
VAL_ 1384 SuspensionSettingRequest2_v2 0 "No request" 1 "VADA Setting 1" 2 "VADA Setting 2" 3 "VADA Setting 3" 4 "VADA Setting 4" 5 "VADA Setting 5" 6 "VADA Setting 6" 7 "VADA Setting 7" 8 "VADA Setting 8" 9 "VADA Setting 9" 10 "VADA Setting 10" 11 "VADA Setting 11" 12 "VADA Setting 12" 13 "VADA Setting 13" 14 "Reserved" 15 "Reset request";
VAL_ 1384 DriveModeRequest2_v2 0 "No request" 1 "Mode 1" 2 "Mode 2" 3 "Mode 3" 4 "Mode 4" 5 "Mode 5" 6 "Mode 6" 7 "Mode 7" 8 "Mode 8" 9 "Mode 9" 10 "Mode 10" 11 "Mode 11" 12 "Mode 12" 13 "Mode 13" 14 "Mode 14" 15 "Not used";
VAL_ 1384 SecondRowRightSeatAutoRequest 0 "No request" 1 "Auto mode activation" 2 "Auto mode deactivation" 3 "Reset request";
VAL_ 1384 SecondRowLeftSeatAutoRequest 0 "No request" 1 "Auto mode activation" 2 "Auto mode deactivation" 3 "Reset request";
VAL_ 1392 HUD_ADASactivationRequest2 0 "No request" 1 "Activation request" 2 "De-activation request" 3 "Reset request";
VAL_ 1392 VSPsoundChoiceActivationRequest2 0 "No VSP Choice request" 1 "VSP Choice 1" 2 "VSP Choice 2" 3 "VSP Choice 3" 4 "VSP Choice 4" 5 "VSP Choice 5" 6 "Reset" 7 "Not used";
VAL_ 1392 FAPK_DefaultManeuverTypeRequest2 0 "no request" 1 "park in / parallel" 2 "park in / perpendicular" 3 "park in / angled" 4 "mode auto" 5 "reset request" 6 "Not Used" 7 "Not Used";
VAL_ 1392 AmbientLightingColor_v3 0 "No request" 1 "Color 1" 2 "Color 2" 3 "Color 3" 4 "Color 4" 5 "Color 5" 6 "Color 6" 7 "Color 7" 8 "Color 8" 9 "Color 9" 10 "Color 10" 11 "Color 11" 12 "Color 12" 13 "Color 13" 14 "Color 14" 15 "Color 15" 16 "Color 16" 17 "Color 17" 18 "Color 18" 19 "Color 19" 20 "Color 20" 21 "Color 21" 22 "Color 22" 23 "Color 23" 24 "Color 24" 25 "Color 25" 26 "Color 26" 27 "Color 27" 28 "Color 28" 29 "Color 29" 30 "Color 30" 31 "Color 31" 32 "Color 32" 33 "Color 33" 34 "Color 34" 35 "Color 35" 36 "Color 36" 37 "Color 37" 38 "Color 38" 39 "Color 39" 40 "Color 40" 41 "Color 41" 42 "Color 42" 43 "Color 43" 44 "Color 44" 45 "Color 45" 46 "Color 46" 47 "Color 47" 48 "Color 48" 49 "Color 49" 50 "Color 50" 51 "Color 51" 52 "Color 52" 53 "Color 53" 54 "Color 54" 55 "Color 55" 56 "Color 56" 57 "Color 57" 58 "Color 58" 59 "Color 59" 60 "Color 60" 61 "Color 61" 62 "Color 62" 63 "Color 63" 64 "Color 64" 65 "Color 65" 66 "Color 66" 67 "Color 67" 68 "Color 68" 69 "Color 69" 70 "Color 70" 71 "Color 71" 72 "Color 72" 73 "Color 73" 74 "Color 74" 75 "Color 75" 76 "Color 76" 77 "Color 77" 78 "Color 78" 79 "Color 79" 80 "Color 80" 81 "Color 81" 82 "Color 82" 83 "Color 83" 84 "Color 84" 85 "Color 85" 86 "Color 86" 87 "Color 87" 88 "Color 88" 89 "Color 89" 90 "Color 90" 91 "Color 91" 92 "Color 92" 93 "Color 93" 94 "Color 94" 95 "Color 95" 96 "Color 96" 97 "Color 97" 98 "Color 98" 99 "Color 99" 100 "Color 100" 101 "Color 101" 102 "Color 102" 103 "Color 103" 104 "Color 104" 105 "Color 105" 106 "Color 106" 107 "Color 107" 108 "Color 108" 109 "Color 109" 110 "Color 110" 111 "Color 111" 112 "Color 112" 113 "Color 113" 114 "Color 114" 115 "Color 115" 116 "Color 116" 117 "Color 117" 118 "Color 118" 119 "Color 119" 120 "Color 120" 121 "Color 121" 122 "Color 122" 123 "Color 123" 124 "Color 124" 125 "Color 125" 126 "Color 126" 127 "Reset Request";
VAL_ 1392 FOTA_ReadyToSleep_IVI 0 "Refuse to sleep due to FOTA" 1 "Ready to sleep";
VAL_ 1392 VSPSoundActivationRequest2 0 "No VSP request" 1 "VSP activated" 2 "VSP no activated" 3 "Reset request";
VAL_ 1392 HUD_TurnByTurnActivationRequest2 0 "No request" 1 "Activation request" 2 "De-activation request" 3 "Reset request";
VAL_ 1392 HUD_TSRactivationRequest2 0 "No request" 1 "Activation request" 2 "De-activation request" 3 "Reset request";
VAL_ 1392 SET_Acceleration_Request2 0 "No request" 1 "Quick" 2 "Standard" 3 "Gentle" 4 "Reset request" 5 "Not used" 6 "Not used" 7 "Not used";
VAL_ 1392 SET_NavigatDriveAssist_Request2 0 "No request" 1 "OFF" 2 "ON" 3 "Reset request";
VAL_ 1392 SET_ALCActivationByTSIG_Request2 0 "No request" 1 "OFF" 2 "ON" 3 "Reset request";
VAL_ 1392 SET_Deceleration_Request2 0 "No request" 1 "Quick" 2 "Standard" 3 "Gentle" 4 "Reset request" 5 "Not used" 6 "Not used" 7 "Not used";
VAL_ 1392 SET_OvertakingAssist_Request2 0 "No request" 1 "OFF" 2 "ON" 3 "Reset request";
VAL_ 1392 SET_LaneChangeSwiftness_Request2 0 "No request" 1 "Swift" 2 "Standard" 3 "Comfort" 4 "Reset request" 5 "Not used" 6 "Not used" 7 "Not used";
VAL_ 1392 SET_CornerSpeedLevel_Request2 0 "No request" 1 "Quick" 2 "Standard" 3 "Gentle" 4 "Reset request" 5 "Not used" 6 "Not used" 7 "Not used";
VAL_ 1392 SET_VoiceGuidance_Request2 0 "No request" 1 "OFF" 2 "ON" 3 "Reset request";
VAL_ 1392 SET_PositionInLane_Request2 0 "No request" 1 "To_hard_shoulder" 2 "Centre" 3 "To_overtake_lane" 4 "Reset request" 5 "Not Used" 6 "Not Used" 7 "Not Used";
VAL_ 1392 SET_OvertakeRelatSpeed_Request2 0 "No request" 1 "Low" 2 "Middle" 3 "High" 4 "Reset request" 5 "Not used" 6 "Not used" 7 "Not used";
VAL_ 1392 IVI_SafeModeAck 0 "Not activated" 1 "Activated";
VAL_ 1392 WDA_ActivationRequest2 0 "No request" 1 "Activation request" 2 "Deactivation request" 3 "Reset request";
VAL_ 1392 RAB_ActivationRequest2 0 "No request" 1 "Activation request" 2 "Deactivation request" 3 "Reset Request";
VAL_ 1392 VirtualKeySuspendReq2 0 "No Request" 1 "VK Suspend" 2 "VK Resume" 3 "VK Factory Reset (Switch to Default VK State)";
VAL_ 1392 SET_MAPAutoUpdate_Request2 0 "No request" 1 "OFF" 2 "ON" 3 "Reset request";
VAL_ 1392 SET_FocusState_Request2 0 "No request" 1 "OFF" 2 "ON" 3 "Reset request";
VAL_ 1392 SET_ADL3_Request2 0 "No request" 1 "OFF" 2 "ON" 3 "Reset request";
VAL_ 1398 ChargingStationComType 0 "AC Basic" 1 "AC HLC ISO15118" 2 "DC Combo basic" 3 "DC Combo HLC ISO15118" 4 "DC CHAdeMO" 5 "DC GB/T" 6 "AC BPT Dynamic" 7 "Unavailable";
VAL_ 1398 V2G_ActivationState 0 "Charge Service not activated" 1 "Charge Service activated" 2 "Charge Service deactivated due to an error" 3 "Charge Service deactivated due to certificate error" 4 "Charge Service deactivated due to durability inhibition" 5 "Charge Service activated and V2G session ongoing" 6 "unavailable" 7 "Charge service activated and waiting for resume";
VAL_ 1402 BCI_StatusDisplay 0 "No display" 1 "Not operational" 2 "Operational" 3 "Not used";
VAL_ 1402 LDW_SensibilityState 0 "Unavailable" 1 "Low sensibility" 2 "Middle sensibility" 3 "High sensibility";
VAL_ 1402 LDW_ActivationState_v3 0 "Unavailable" 1 "Activated" 2 "Deactivated" 3 "Not used";
VAL_ 1402 LDW_LaneDisplay 0 "No display" 1 "Right lane monitoring" 2 "Left lane monitoring" 3 "Right and left lane monitoring";
VAL_ 1402 LKA_StatusDisplay_v2 0 "No display" 1 "Not operational" 2 "Operational" 3 "Temporary failure" 4 "Permanent failure" 5 "OFF Value" 6 "Not Used" 7 "Not Used";
VAL_ 1402 LDW_StatusDisplay_v2 0 "No display" 1 "Not operational" 2 "Operational" 3 "Temporary failure" 4 "Permanent failure" 5 "OFF Value" 6 "Not Used" 7 "Not Used";
VAL_ 1402 LCA_StatusDisplay_v2 0 "No display" 1 "Not operational" 2 "Operational" 3 "Temporary failure" 4 "Permanent failure" 5 "MRM active" 6 "Not Used" 7 "Not Used";
VAL_ 1405 AVM_SettingRequest 0 "Not Requested" 1 "All Setting" 2 "Save Location Setting" 3 "Display Settings";
VAL_ 1405 RPK_ModeRequest 0 "Normal Mode Request" 1 "RPK Mode Request" 2 "RPK Register Mode Request" 3 "Not Used";
VAL_ 1410 MemoPositionDisplayRequest 0 "No display" 1 "Display1" 2 "Display2" 3 "Display3";
VAL_ 1410 MemoParkExecutionState 0 "No display" 1 "Execution state1" 2 "Execution state2" 3 "Execution state3";
VAL_ 1412 HVAC_ClimShortcutPush 0 "Switch not pushed" 1 "Switch pushed";
VAL_ 1415 PhoneBatteryLevelDisplay 0 "No display" 1 "Low Battery" 2 "Level 1" 3 "Level 2" 4 "Level 3" 5 "Level 4" 6 "Level 5" 7 "Level 6";
VAL_ 1415 FAPK_SelectedManeuverTypeRequest 0 "no request" 1 "park in / parallel" 2 "park in / perpendicular" 3 "park in / angled" 4 "park out" 5 "mode auto" 6 "Not Used" 7 "Not Used";
VAL_ 1415 DisplayActivation 0 "No display" 1 "Display";
VAL_ 1415 PhoneReceptionLevelDisplay 0 "No display" 1 "No reception" 2 "Level 1" 3 "Level 2" 4 "Level 3" 5 "Level 4" 6 "Level 5" 7 "Level 6";
VAL_ 1415 Distract_ShieldActivationState2 0 "Deactivated" 1 "Activated";
VAL_ 1415 ClockSetStatus 0 "Clock set" 1 "Clock not set";
VAL_ 1415 AVM_LayoutDisplayRequest_3 0 "no message" 1 "Layout 1" 2 "Layout 2" 3 "Layout 3" 4 "Layout 4" 5 "Layout 5" 6 "Layout 6" 7 "Layout 7" 8 "Layout 8" 9 "Layout 9" 10 "Layout 10" 11 "Layout 11" 12 "Layout 12" 13 "Layout 13" 14 "Layout 14" 15 "Layout 15" 16 "Layout 16" 17 "Layout 17" 18 "Layout 18" 19 "Layout 19" 20 "Layout 20" 21 "Layout 21" 22 "Layout 22" 23 "Layout 23" 24 "Layout 24" 25 "Layout 25" 26 "Layout 26" 27 "Layout 27" 28 "Layout 28" 29 "Layout 29" 30 "Layout 30" 31 "Layout 31";
VAL_ 1415 Fatigue_ShieldActivationState2 0 "Deactivated" 1 "Activated";
VAL_ 1415 ADAS_Shield_Request 0 "No request" 1 "CustomShield request" 2 "Full shield request" 3 "Not Used";
VAL_ 1415 AVM_LayoutVideoStatus_3 0 "No display (unavailable)" 1 "Layout 1" 2 "Layout 2" 3 "Layout 3" 4 "Layout 4" 5 "Layout 5" 6 "Layout 6" 7 "Layout 7" 8 "Layout 8" 9 "Layout 9" 10 "Layout 10" 11 "Layout 11" 12 "Layout 12" 13 "Layout 13" 14 "Layout 14" 15 "Layout 15" 16 "Layout 16" 17 "Layout 17" 18 "Layout 18" 19 "Layout 19" 20 "Layout 20" 21 "Layout 21" 22 "Layout 22" 23 "Layout 23" 24 "Layout 24" 25 "Layout 25" 26 "Layout 26" 27 "Layout 27" 28 "Layout 28" 29 "Layout 29" 30 "Layout 30" 31 "Layout 31";
VAL_ 1421 SCCM_TelescopicMovDisplayReq 0 "No display request" 1 "Telescopic forward display request" 2 "Telescopic backward display request" 3 "Not used";
VAL_ 1421 SCCM_TiltMovDisplayReq 0 "No display request" 1 "Tilt up display request" 2 "Tilt down display request" 3 "Not used";
VAL_ 1422 DriverBackBolsterDisplayReq 0 "No display request" 1 "Backrest bolster increase Display Request" 2 "Backrest bolster decrease Display Request" 3 "Not monitored";
VAL_ 1422 MC_MovementDisplayRequest 0 "No display requested" 1 "Display requested";
VAL_ 1422 MC_ActivationState 0 "Magic Cockpit OFF" 1 "Magic Cockpit ON";
VAL_ 1422 MC_PositionChangeStatus 0 "Unavailable" 1 "MC position 1" 2 "MC position 2" 3 "MC position 3" 4 "MC position 4" 5 "MC position 5" 6 "MC position 6" 7 "MC position 7" 8 "MC position 8" 9 "MC position 9" 10 "MC position 10" 11 "MC position 11" 12 "MC position 12" 13 "MC position 13" 14 "MC position 14" 15 "Position Change On Going";
VAL_ 1422 MCM_PositionSaveRequest 0 "No request" 1 "Save MC position 1" 2 "Save MC position 2" 3 "Save MC position 3" 4 "Save MC position 4" 5 "Save MC position 5" 6 "Save MC position 6" 7 "Save MC position 7" 8 "Save MC position 8" 9 "Save MC position 9" 10 "Save MC position 10" 11 "Save MC position 11" 12 "Save MC position 12" 13 "Save MC position 13" 14 "Save MC position 14" 15 "Unavailable";
VAL_ 1422 MCM_PositionRecallRequest 0 "No request" 1 "Recall MC position 1" 2 "Recall MC position 2" 3 "Recall MC position 3" 4 "Recall MC position 4" 5 "Recall MC position 5" 6 "Recall MC position 6" 7 "Recall MC position 7" 8 "Recall MC position 8" 9 "Recall MC position 9" 10 "Recall MC position 10" 11 "Recall MC position 11" 12 "Recall MC position 12" 13 "Recall MC position 13" 14 "Recall MC position 14" 15 "Reset Request";
VAL_ 1422 DrLumbarDisplayRequest_Z_Axis 0 "No display request" 1 "Z Axis Upward" 2 "Z Axis Downward" 3 "Not monitored";
VAL_ 1422 MC_TutorialState 0 "Not Done" 1 "Done";
VAL_ 1422 DriverCLADisplayRequest 0 "No Display Request" 1 "CLA Forward Display Request" 2 "CLA Backward Display Request" 3 "Not Used";
VAL_ 1422 DriverCushionBolsterDisplayReq 0 "No display request" 1 "Cushion bolster increase Display Request" 2 "Cushion bolster decrease Display Request" 3 "Not monitored";
VAL_ 1422 DrLumbarDisplayRequest_X_Axis 0 "No display request" 1 "X Axis Frontward" 2 "X Axis Backward" 3 "Not monitored";
VAL_ 1422 DriverMassageCondition 0 "Function not available" 1 "Function available";
VAL_ 1434 Allowed_VR_FrWipingRequest 0 "Table Value150974";
VAL_ 1434 Allowed_VR_RrWipingRequest 0 "Table Value150975";
VAL_ 1434 RearSignatureState 0 "Unavailable" 1 "Activated" 2 "Deactivated" 3 "Not used";
VAL_ 1434 RrWiper_ServPos_Status 0 "Not activated" 1 "Activated";
VAL_ 1434 FrWiper_ServPos_Status 0 "Not activated" 1 "Activated";
VAL_ 1434 RrWiper_ServPos_Available_Status 0 "Not Available" 1 "Available";
VAL_ 1434 FrWiper_ServPos_Available_Status 0 "Not Available" 1 "Available";
VAL_ 1434 VR_ESSUPosition 0 "Not Available" 1 "All roof Clear" 2 "Front Area roof Clear & Rear area roof opacified" 3 "Front Area roof opacified & Rear area roof clear" 4 "All roof opacified" 5 "Not Used" 6 "Not Used" 7 "Not Used";
VAL_ 1434 VR_AuthCondition_ESSU 0 "Not satisfied" 1 "Satisfied";
VAL_ 1436 HFP_ManeuverChoiceDisplayRequest 0 "Maneuver choice not possible" 1 "Maneuver choice possible";
VAL_ 1436 HFP_SelectedManeuverType 0 "unavailable" 1 "park in / parallel" 2 "park in / perpendicular" 3 "park in / angled" 4 "park out" 5 "Not used" 6 "Not used" 7 "Not used";
VAL_ 1436 HFP_DefaultManeuverType 0 "unavailable" 1 "park in / parallel" 2 "park in / perpendicular" 3 "park in / angled" 4 "park out" 5 "Not used" 6 "Not used" 7 "Not used";
VAL_ 1436 DetectedSlotLeft_Selection 0 "Slot left not selected by user" 1 "Slot left selected by user";
VAL_ 1436 HFP_ManeuverMove 0 "Unavailable" 1 "First move" 2 "Backward move" 3 "Forward move";
VAL_ 1436 HFP_SoundRequest 0 "no sound" 1 "level 1 sound" 2 "level 2 sound" 3 "unavailable";
VAL_ 1436 HFP_MapContentDisplay 0 "Empty Display" 1 "scanning Display" 2 "parkOutConfirmation Display" 3 "guidance Display" 4 "Not used" 5 "Not used" 6 "Not used" 7 "unavailable";
VAL_ 1436 HFP_ExtendedInstrContentDisplay 0 "instruction 1" 1 "instruction 2" 2 "instruction 3" 3 "instruction 4" 4 "instruction 5" 5 "instruction 6" 6 "instruction 7" 7 "instruction 8" 8 "instruction 9" 9 "instruction 10" 10 "instruction 11" 11 "instruction 12" 12 "instruction 13" 13 "instruction 14" 14 "Instruction 15" 15 "Instruction 16" 16 "Instruction 17" 17 "Instruction 18" 18 "Instruction 19" 19 "instruction 20" 20 "Instruction 21" 21 "Instruction 22" 22 "Instruction 23" 23 "Instruction 24" 24 "Instruction 25" 25 "Instruction 26" 26 "Instruction 27" 27 "Instruction 28" 28 "Instruction 29" 29 "Instruction 30" 30 "Instruction 31" 31 "Unavailable";
VAL_ 1436 DetectedSlotRight_Suitable 0 "Slot right unavailable for parking" 1 "Slot right available for parking";
VAL_ 1436 DetectedSlotRight_Selection 0 "Slot right not selected by user" 1 "Slot right selected by user";
VAL_ 1436 DetectedSlotLeft_Suitable 0 "Slot left unavailable for parking" 1 "Slot left available for parking";
VAL_ 1436 ScanningSide 0 "no scanning side" 1 "left" 2 "right" 3 "unavailable";
VAL_ 1444 HUD_EffectiveDeployment 0 "HUD not deployed" 1 "HUD deployed";
VAL_ 1444 HUD_TSRactivationState 0 "Unavailable" 1 "Activated" 2 "De-activated" 3 "Not used";
VAL_ 1444 HUD_PositionState 0 "Step 1" 1 "Step 2" 2 "Step 3" 3 "Step 4" 4 "Step 5" 5 "Step 6" 6 "Step 7" 7 "Step 8" 8 "Step 9" 9 "Step 10" 10 "Step 11" 11 "Step 12" 12 "Step 13" 13 "Step 14" 14 "Step 15" 15 "Step 16" 16 "Step 17" 17 "Step 18" 18 "Step 19" 19 "Step 20" 20 "Step 21" 21 "Not used" 22 "Not used" 23 "Not used" 24 "Not used" 25 "Not used" 26 "Not used" 27 "Not used" 28 "Not used" 29 "Not used" 30 "Not used" 31 "Not used";
VAL_ 1444 HUD_ActivationState 0 "Unavailable" 1 "HUD activated" 2 "HUD de-activated" 3 "Not used";
VAL_ 1444 HUD_ADASactivationState 0 "Unavailable" 1 "Activated" 2 "De-activated" 3 "Not used";
VAL_ 1444 HUD_TurnByTurnActivationState 0 "Unavailable" 1 "Activated" 2 "De-activated" 3 "Not used";
VAL_ 1444 HUD_ITactivationState 0 "Unavailable" 1 "Activated" 2 "De-activated" 3 "Not used";
VAL_ 1444 HUD_TelSMSactivationState 0 "Activated" 1 "No activated";
VAL_ 1444 HUD_NightLuminosityState 0 "Step 1" 1 "Step 2" 2 "Step 3" 3 "Step 4" 4 "Step 5" 5 "Step 6" 6 "Step 7" 7 "Step 8" 8 "Step 9" 9 "Step 10" 10 "Step 11" 11 "Step 12" 12 "Step 13" 13 "Step 14" 14 "Step 15" 15 "Step 16" 16 "Step 17" 17 "Step 18" 18 "Step 19" 19 "Step 20" 20 "Step 21" 21 "Not used" 22 "Not used" 23 "Not used" 24 "Not used" 25 "Not used" 26 "Not used" 27 "Not used" 28 "Not used" 29 "Not used" 30 "Not used" 31 "Not used";
VAL_ 1447 SR_CustomerRecordStatus 0 "No request" 1 "Customer Record In Progress" 2 "Customer Record Stopped" 3 "Customer Record End";
VAL_ 1449 ClimLinkPriorityHeatStrgAutoReq 0 "No request" 1 "Level 1" 2 "Level 2" 3 "Level 3" 4 "Level 4" 5 "Level 5" 6 "OFF request" 7 "Reset request";
VAL_ 1449 ClimFPrearLeftBlowingRequest 0 "No Request" 1 "Level 1" 2 "Level 2" 3 "Level 3" 4 "Level 4" 5 "Level 5" 6 "Level 6" 7 "Level 7" 8 "Level 8" 9 "Level 9" 10 "Level 10" 11 "Level 11" 12 "Level 12" 13 "Level 13" 14 "Level 14" 15 "Blower OFF";
VAL_ 1449 ClimFPrearRightBlowingRequest 0 "No Request" 1 "Level 1" 2 "Level 2" 3 "Level 3" 4 "Level 4" 5 "Level 5" 6 "Level 6" 7 "Level 7" 8 "Level 8" 9 "Level 9" 10 "Level 10" 11 "Level 11" 12 "Level 12" 13 "Level 13" 14 "Level 14" 15 "Blower OFF";
VAL_ 1449 ClimLinkPriorityRRSeatAutoReq 0 "No request" 1 "Level 1" 2 "Level 2" 3 "Level 3" 4 "Level 4" 5 "Level 5" 6 "OFF request" 7 "Reset request";
VAL_ 1449 ClimAllSeatAutoNormalRequest 0 "No Request" 1 "OFF" 2 "ON" 3 "Not used";
VAL_ 1449 ClimLinkPrio3rdRSeatAutoReq 0 "No request" 1 "Level 1" 2 "Level 2" 3 "Level 3" 4 "Level 4" 5 "Level 5" 6 "OFF request" 7 "Reset request";
VAL_ 1449 ClimLinkPrio3rdLSeatAutoReq 0 "No request" 1 "Level 1" 2 "Level 2" 3 "Level 3" 4 "Level 4" 5 "Level 5" 6 "OFF request" 7 "Reset request";
VAL_ 1450 SR_AutomaticRecordStatus 0 "No request" 1 "Automatic Record In Progress" 2 "Automatic Record End" 3 "Not used";
VAL_ 1455 VirtualKeyGen2MenuState 0 "No display request" 1 "Go back to top menu" 2 "Cancel operation" 3 "Registration Start Condition not satisfied - pairing password" 4 "Registration Start Condition not satisfied - key fob" 5 "Registration Start Condition satisfied" 6 "Display pairing password for Owner Key Registration" 7 "Registration communication not started" 8 "Paring password not correct (Owner Key Registration)" 9 "Registration communication in progress" 10 "Registration communication error detected" 11 "Registration completed" 12 "Unpairing Start Condition not satisfied" 13 "Unpairing completed" 14 "Owner Key Change Start Condition not satisfied - pairing password" 15 "Owner Key Change Start Condition not satisfied - key fob" 16 "Owner Key Change Start Condition satisfied" 17 "Display pairing password for Owner Key Change" 18 "Owner Key Change communication not started" 19 "Paring password not correct (Owner Key Change)" 20 "Owner Key Change communication in progress" 21 "Owner Key Change communication error detected" 22 "Owner Key Change completed" 23 "Friend key termination Start Condition not satisfied" 24 "FriendKey1 termination completed" 25 "FriendKey2 termination completed" 26 "FriendKey3 termination completed" 27 "FriendKey4 termination completed" 28 "FriendKey5 termination completed" 29 "All Friend key termination completed" 30 "Display friend key list for owner" 31 "Display friend key list for friend" 32 "Reserved" 33 "Reserved" 34 "Reserved" 35 "Reserved" 36 "Reserved" 37 "Reserved" 38 "Reserved" 39 "Reserved" 40 "Reserved" 41 "Reserved" 42 "Reserved" 43 "Reserved" 44 "Reserved" 45 "Reserved" 46 "Reserved" 47 "Reserved" 48 "Reserved" 49 "Reserved" 50 "Reserved" 51 "Reserved" 52 "Reserved" 53 "Reserved" 54 "Reserved" 55 "Reserved" 56 "Reserved" 57 "Reserved" 58 "Reserved" 59 "Reserved" 60 "Reserved" 61 "Reserved" 62 "Reserved" 63 "Unavailable value";
VAL_ 1457 AmbientLightingArea3Status 0 "AmbientLighting Area 3 Desactivated" 1 "AmbientLighting Area 3 Activated";
VAL_ 1457 AmbientLightingArea2Status 0 "AmbientLighting Area 2 Desactivated" 1 "AmbientLighting Area 2 Activated";
VAL_ 1457 AmbientLightingActivationStatus 0 "Deactivation State" 1 "Activation State";
VAL_ 1457 AmbientLightingArea1Status 0 "AmbientLighting Area 1 Desactivated" 1 "AmbientLighting Area 1 Activated";
VAL_ 1457 AmbientLightDayIntensityStatus 31 "Unavailable";
VAL_ 1458 PnCHEVCactivationStatus 0 "No PnC function activated" 1 "PnC function activated" 2 "Not Used" 3 "Unavailable";
VAL_ 1458 SportUsageMPUState 0 "MPU disable" 1 "MPU enable";
VAL_ 1458 SportUsageActivationState 0 "Auto requested" 1 "Forced requested";
VAL_ 1458 PWTConditioningMode 0 "no cooling request" 1 "Cooling by Radiator" 2 "Heating Recovery (by chiller)" 3 "Not Used";
VAL_ 1459 MOD_ActivationState 0 "Activated" 1 "Deactivated";
VAL_ 1459 AVM_SoundType 0 "Normal sound" 1 "Error sound";
VAL_ 1459 AVM_SoundRequest 0 "Sound not requested" 1 "Sound requested";
VAL_ 1459 MOD_SoundAlertRequest_IVI 0 "Sound alert not requested" 1 "Sound alert requested";
VAL_ 1459 AVM_InitializationState 0 "Initialization completed" 1 "Initialization on going";
VAL_ 1459 AVM_DisplayRequest 0 "Not requested" 1 "Requested";
VAL_ 1459 AVM_LayoutVideoStatus 0 "No display (unavailable)" 1 "Layout1" 2 "Layout2" 3 "Layout3" 4 "Layout4" 5 "Layout5" 6 "Layout6" 7 "Layout7" 8 "Layout8" 9 "Layout9" 10 "Layout10" 11 "Layout11" 12 "Layout12" 13 "Layout13" 14 "Layout14" 15 "Layout15" 16 "Layout16" 17 "Layout17" 18 "Layout18" 19 "Layout19" 20 "Layout20" 21 "Layout21" 22 "Layout22" 23 "Layout23" 24 "Layout24" 25 "Layout25" 26 "Layout26" 27 "Layout27" 28 "Layout28" 29 "Layout29" 30 "Layout30" 31 "Layout31";
VAL_ 1459 AVM_ClosingAuthorization 0 "Not authorized" 1 "Authorized";
VAL_ 1459 AVM_SwitchStatus 0 "OFF" 1 "ON" 2 "unavailable" 3 "Not Used";
VAL_ 1459 AVM_LayoutDisplayRequest 0 "No message" 1 "Layout 1" 2 "Layout 2" 3 "Layout 3" 4 "Layout 4" 5 "Layout 5" 6 "Layout 6" 7 "Layout 7" 8 "Layout 8" 9 "Layout 9" 10 "Layout 10" 11 "Layout 11" 12 "Layout 12" 13 "Layout 13" 14 "Layout 14" 15 "Layout 15" 16 "Layout 16" 17 "Layout 17" 18 "Layout 18" 19 "Layout 19" 20 "Layout 20" 21 "Layout 21" 22 "Layout 22" 23 "Layout 23" 24 "Layout 24" 25 "Layout 25" 26 "Layout 26" 27 "Layout 27" 28 "Layout 28" 29 "Layout 29" 30 "Layout 30" 31 "Layout 31";
VAL_ 1462 ClimRearLeftTempDisplay 0 "No display" 8 "Display Lo" 10 "Display Hi";
VAL_ 1462 ClimFrontDefrostDisplayStatus 0 "Function not available" 1 "Function available";
VAL_ 1462 ClimHeatedSteerWheelDispStatus 0 "Function not available" 1 "Function available";
VAL_ 1462 ClimRearLeftTempDisplayStatus 0 "Function not available" 1 "Function available";
VAL_ 1462 ClimHeatedSteerWheelAutoDisplay 0 "No display" 1 "Heated steering wheel Auto ON" 2 "Heated steering wheel Auto OFF" 3 "Not Used";
VAL_ 1462 ClimFrontDefrostDisplay 0 "No display" 1 "Front defrost ON" 2 "Front defrost OFF" 3 "Not Used";
VAL_ 1462 ClimRearRightTempDisplay 0 "No display" 8 "Display Lo" 10 "Display Hi";
VAL_ 1462 ClimRearRightSyncDisplayStatus 0 "Function not available" 1 "Function available";
VAL_ 1462 ClimRearRightSyncDisplay 0 "No display" 1 "Sync mode ON" 2 "Sync mode OFF" 3 "Not used";
VAL_ 1462 ClimRearLeftSyncDisplayStatus 0 "Function not available" 1 "Function available";
VAL_ 1462 ClimRearLeftSyncDisplay 0 "No display" 1 "Sync mode ON" 2 "Sync mode OFF" 3 "Not used";
VAL_ 1462 ClimRearRightTempDisplayStatus 0 "Function not available" 1 "Function available";
VAL_ 1462 ClimRearRightFlowDistDispStatus 0 "Function not available" 1 "Function available";
VAL_ 1462 ClimRearRightFlowDistrDisplay 0 "No display" 1 "Feet" 2 "Vent" 3 "Feet + Vent" 4 "Defrost" 5 "Defrost + Feet" 6 "Defrost + Vent" 7 "Defrost + Vent + Feet";
VAL_ 1462 ClimRearLeftFlowDistrDispStatus 0 "Function not available" 1 "Function available";
VAL_ 1462 ClimRearLeftFlowDistrDisplay 0 "No display" 1 "Feet" 2 "Vent" 3 "Feet + Vent" 4 "Defrost" 5 "Defrost + Feet" 6 "Defrost + Vent" 7 "Defrost + Vent + Feet";
VAL_ 1462 ClimRearLeftBlowingAutoDisplay 0 "No display" 1 "Blowing auto ON" 2 "Blowing auto OFF" 3 "Not used";
VAL_ 1462 ClimRearRightBlowingAutoDisplay 0 "No display" 1 "Blowing auto ON" 2 "Blowing auto OFF" 3 "Not used";
VAL_ 1462 ClimRearRightBlowLevelDisplay 0 "No display" 1 "Level 1" 2 "Level 2" 3 "Level 3" 4 "Level 4" 5 "Level 5" 6 "Level 6" 7 "Level 7" 8 "Level 8" 9 "Level 9" 10 "Level 10" 11 "Level 11" 12 "Level 12" 13 "Level 13" 14 "Level 14" 15 "Blower OFF";
VAL_ 1462 ClimRearACDisplay 0 "No display" 1 "AC ON" 2 "AC OFF" 3 "Not used";
VAL_ 1462 ClimRearRightBlowLevlDispStatus 0 "Function not available" 1 "Function available";
VAL_ 1462 ClimRearLeftBlowLevelDispStatus 0 "Function not available" 1 "Function available";
VAL_ 1462 ClimRearLeftBlowLevelDisplay 0 "No display" 1 "Level 1" 2 "Level 2" 3 "Level 3" 4 "Level 4" 5 "Level 5" 6 "Level 6" 7 "Level 7" 8 "Level 8" 9 "Level 9" 10 "Level 10" 11 "Level 11" 12 "Level 12" 13 "Level 13" 14 "Level 14" 15 "Blower OFF";
VAL_ 1462 ClimLinkPrioritHeatStrgAutoDisp 0 "No display" 1 "Level 1" 2 "Level 2" 3 "Level 3" 4 "Level 4" 5 "Level 5" 6 "OFF" 7 "Not used";
VAL_ 1462 ClimRearRightAutoDisplay 0 "No display" 1 "Auto ON" 2 "Auto OFF" 3 "Not used";
VAL_ 1462 ClimRearLeftAutoDisplay 0 "No display" 1 "Auto ON" 2 "Auto OFF" 3 "Not used";
VAL_ 1462 ClimRearACDisplayStatus 0 "Function not available" 1 "Function available";
VAL_ 1464 DriverMassageActivationReq 0 "No request" 1 "Activation request" 2 "Deactivation request" 3 "Reset request";
VAL_ 1464 DriverSeatMemoRecallReq 0 "No recall" 1 "Recall of memorization 1" 2 "Recall of memorization 2" 3 "Recall of memorization 3" 4 "Recall of memorization 4" 5 "Recall of memorization 5" 6 "Recall of memorization 6" 7 "Reset Request";
VAL_ 1464 DriverSeatMemoRequest 0 "No request of memorization" 1 "Request of memorization 1" 2 "Request of memorization 2" 3 "Request of memorization 3" 4 "Request of memorization 4" 5 "Request of memorization 5" 6 "Request of memorization 6" 7 "Reset Request";
VAL_ 1464 DriverEasyAccessRequest2 0 "No request" 1 "Easy access activation requested" 2 "Easy access de-activation requested" 3 "Reset Request";
VAL_ 1464 DriverMassageIntensityReq 0 "No request" 1 "Intensity 1 requested" 2 "Intensity 2 requested" 3 "Intensity 3 requested" 4 "Intensity 4 requested" 5 "Intensity 5 requested" 6 "Not used" 7 "Reset request";
VAL_ 1464 PassengerMassageActivationReq 0 "No request" 1 "Activation request" 2 "Deactivation request" 3 "Reset request";
VAL_ 1464 DriverMassageVelocityReq 0 "No request" 1 "Velocity 1 requested" 2 "Velocity 2 requested" 3 "Velocity 3 requested" 4 "Velocity 4 requested" 5 "Velocity 5 requested" 6 "Not Used" 7 "Reset request";
VAL_ 1464 PassengerEasyAccessRequest 0 "No request" 1 "Easy access activation requested" 2 "Easy access de-activation requested" 3 "Reset Request";
VAL_ 1464 PassengerMassageVelocityReq 0 "No request" 1 "Velocity 1 requested" 2 "Velocity 2 requested" 3 "Velocity 3 requested" 4 "Velocity 4 requested" 5 "Velocity 5 requested" 6 "Not Used" 7 "Reset Request";
VAL_ 1464 PassengerMassageIntensityReq 0 "No request" 1 "Intensity 1 requested" 2 "Intensity 2 requested" 3 "Intensity 3 requested" 4 "Intensity 4 requested" 5 "Intensity 5 requested" 6 "Not used" 7 "Reset Request";
VAL_ 1465 PreSoakHVACfunctionsRequest 0 "Not used" 1 "Cabin air conditioning/heating OFF request" 2 "Cabin air conditioning/heating ON request" 3 "Not used";
VAL_ 1465 PreSoakFRseatRequest 0 "Not used" 1 "Heater OFF request" 2 "Heater ON request" 3 "Ventilated OFF request" 4 "Ventilated ON request" 5 "Not used" 6 "Not used" 7 "Not used";
VAL_ 1465 PreSoakFLseatRequest 0 "Not used" 1 "Heater OFF request" 2 "Heater ON request" 3 "Ventilated OFF request" 4 "Ventilated ON request" 5 "Not used" 6 "Not used" 7 "Not used";
VAL_ 1465 PreSoakSecondRLseatRequest 0 "Not used" 1 "Heater OFF request" 2 "Heater ON request" 3 "Ventilated OFF request" 4 "Ventilated ON request" 5 "Not used" 6 "Not used" 7 "Not used";
VAL_ 1465 PreSoakSecondRRseatRequest 0 "Not used" 1 "Heater OFF request" 2 "Heater ON request" 3 "Ventilated OFF request" 4 "Ventilated ON request" 5 "Not used" 6 "Not used" 7 "Not used";
VAL_ 1465 PreSoak_eACmodeRequest 0 "Not used" 1 "Normal request" 2 "Quick request" 3 "Not used";
VAL_ 1465 PreSoakThirdRLseatRequest 0 "Not used" 1 "Heater OFF request" 2 "Heater ON request" 3 "Ventilated OFF request" 4 "Ventilated ON request" 5 "Not used" 6 "Not used" 7 "Not used";
VAL_ 1465 PreSoakBatteryHeatingRequest 0 "Not used" 1 "Battery heating OFF request" 2 "Battery heating ON request" 3 "Not used";
VAL_ 1465 PreSoakSecondRCseatRequest 0 "Not used" 1 "Heater OFF request" 2 "Heater ON request" 3 "Ventilated OFF request" 4 "Ventilated ON request" 5 "Not used" 6 "Not used" 7 "Not used";
VAL_ 1465 LivingLightModeRequest 0 "Not activated" 1 "Activated";
VAL_ 1465 PreSoakAirPurifierRequest 0 "Not used" 1 "Air purifier OFF request" 2 "Air purifier ON request" 3 "Not used";
VAL_ 1465 PreSoakFrontDefrostRequest 0 "Not used" 1 "Front defrost OFF request" 2 "Front defrost ON request" 3 "Not used";
VAL_ 1465 PreSoakThirdRRseatRequest 0 "Not used" 1 "Heater OFF request" 2 "Heater ON request" 3 "Ventilated OFF request" 4 "Ventilated ON request" 5 "Not used" 6 "Not used" 7 "Not used";
VAL_ 1465 SecondRowCentralSeatRequest 0 "No request" 1 "OFF request" 2 "Heater Low request" 3 "Heater Middle request" 4 "Heater High request" 5 "Ventilated Low request" 6 "Ventilated Middle request" 7 "Ventilated High request" 8 "Reset request" 9 "Not Used" 10 "Not Used" 11 "Not Used" 12 "Not Used" 13 "Not Used" 14 "Not Used" 15 "Not Used";
VAL_ 1465 PreSoakRearDefrostRequest 0 "Not used" 1 "Rear defrost OFF request" 2 "Rear defrost ON request" 3 "Not used";
VAL_ 1465 PreSoakHeatedStrgWheelRequest 0 "Not used" 1 "Heated steering wheel OFF request" 2 "Heated steering wheel ON request" 3 "Not used";
VAL_ 1465 FrontRightSeatRequest 0 "No request" 1 "OFF request" 2 "Heater Low request" 3 "Heater Middle request" 4 "Heater High request" 5 "Ventilated Low request" 6 "Ventilated Middle request" 7 "Ventilated High request" 8 "Reset request" 9 "Not Used" 10 "Not Used" 11 "Not Used" 12 "Not Used" 13 "Not Used" 14 "Not Used" 15 "Not Used";
VAL_ 1465 FrontLeftSeatRequest 0 "No request" 1 "OFF request" 2 "Heater Low request" 3 "Heater Middle request" 4 "Heater High request" 5 "Ventilated Low request" 6 "Ventilated Middle request" 7 "Ventilated High request" 8 "Reset request" 9 "Not Used" 10 "Not Used" 11 "Not Used" 12 "Not Used" 13 "Not Used" 14 "Not Used" 15 "Not Used";
VAL_ 1466 EcoAdviceTirePressureRR 0 "No Advice" 1 "Advice";
VAL_ 1466 EcoAdviceTirePressureRL 0 "No Advice" 1 "Advice";
VAL_ 1466 EcoAdviceTirePressureFR 0 "No Advice" 1 "Advice";
VAL_ 1466 EcoAdviceTirePressureFL 0 "No Advice" 1 "Advice";
VAL_ 1468 DriverMassageVelocityState 0 "No velocity" 1 "velocity 1" 2 "velocity 2" 3 "velocity 3" 4 "velocity 4" 5 "velocity 5" 6 "Not Used" 7 "Not Used";
VAL_ 1468 DriverMassageIntensityState 0 "No intensity" 1 "Intensity 1" 2 "Intensity 2" 3 "Intensity 3" 4 "Intensity 4" 5 "Intensity 5" 6 "Not Used" 7 "Not Used";
VAL_ 1468 DriverSeatMemoStatus 0 "Seat Position 1" 1 "Seat Position 2" 2 "Seat Position 3" 3 "Seat Position 4" 4 "Seat Position 5" 5 "Seat Position 6" 6 "No Memorized Position" 7 "Not used";
VAL_ 1468 DriverReclinerDisplayRequest 0 "No Display Request" 1 "Recliner Moving Forward Display Request" 2 "Recliner Moving Backward Display Request" 3 "Not monitored";
VAL_ 1468 DriverFrontHeightDisplayRequest 0 "No Display Request" 1 "Raise Display Request" 2 "Descent Display Request" 3 "Not monitored";
VAL_ 1468 SeatSettingsDisplayRequest 0 "No Display Request" 1 "Seat Settings Display Request";
VAL_ 1468 DriverEasyAccessState 0 "Unavailable" 1 "Easy access activated" 2 "Easy access not activated" 3 "Not used";
VAL_ 1468 DriverBackHeightDisplayRequest 0 "No Display Request" 1 "Raise Display Request" 2 "Descent Display Request" 3 "Not monitored";
VAL_ 1468 DriverMassageActivationState 0 "Massage OFF" 1 "Massage ON";
VAL_ 1468 DriverSlidingDisplayRequest 0 "No Display Request" 1 "Sliding Forward Display Request" 2 "Sliding Backward Display Request" 3 "Not monitored";
VAL_ 1469 AmbientLightingArea2Req 0 "No Request" 1 "AmbientLighting Area 2 requested" 2 "AmbientLighting Area 2 not requested" 3 "Reset Request";
VAL_ 1469 AmbientLightingArea1Req 0 "No Request" 1 "AmbientLighting Area 1 requested" 2 "AmbientLighting Area 1 not requested" 3 "Reset Request";
VAL_ 1469 AmbientLightingActivationReq 0 "No Request" 1 "AmbientLighting Activation request" 2 "AmbientLighting Desactivation request" 3 "Reset Request";
VAL_ 1469 AmbientLightingArea3Req 0 "No Request" 1 "AmbientLighting Area 3 requested" 2 "AmbientLighting Area 3 not requested" 3 "Reset Request ";
VAL_ 1469 MeterVolumeRequest 0 "No request" 1 "Volume 1" 2 "Volume 2" 3 "Volume 3" 4 "Not used" 5 "Not used" 6 "Not used" 7 "Reset request";
VAL_ 1469 AmbientLightDayIntensityRequest 30 "No Request" 31 "Reset Request";
VAL_ 1469 AmbientLightNightIntensityReq 30 "No request" 31 "Reset Request";
VAL_ 1469 UnitDistanceDisplayRequest 0 "No request" 1 "display unit in km request" 2 "display unit in mph request" 3 "Reset request";
VAL_ 1469 DimmingReq 0 "No request" 1 "Step 1" 2 "Step 2" 3 "Step 3" 4 "Step 4" 5 "Step 5" 6 "Step 6" 7 "Step 7" 8 "Step 8" 9 "Step 9" 10 "Step 10" 11 "Step 11" 12 "Step 12" 13 "Step 13" 14 "Step 14" 15 "Step 15" 16 "Step 16" 17 "Step 17" 18 "Step 18" 19 "Step 19" 20 "Step 20" 21 "Step 21" 22 "Not used" 23 "Not used" 24 "Not used" 25 "Not used" 26 "Not used" 27 "Not used" 28 "Not used" 29 "Not used" 30 "Not used" 31 "Reset request";
VAL_ 1469 CockpitLanguageRequest 0 "No Language Request" 1 "Language 01h to FEh" 255 "Reset request";
VAL_ 1469 IoniserAutoLaunchReq2 0 "No request" 1 "Activation request" 2 "Deactivation request" 3 "Reset request";
VAL_ 1469 HVchargeDisplayRequest 0 "No request" 1 "Meter ON during charge request" 2 "Meter OFF during charge request" 3 "Reset to factory parameter";
VAL_ 1469 AccessModeRequest2 0 "No request (initial value)" 1 "Standard mode requested" 2 "Secure mode requested" 3 "Access mode factory setting reset requested";
VAL_ 1469 ADB_ActivationRequest2 0 "No ADB request" 1 "ADB activated" 2 "ADB not activated" 3 "Reset request";
VAL_ 1469 AutoInternalLightingRequest2 0 "No request" 1 "internal lighting activation request" 2 "internal lighting deactivation request" 3 "Reset request";
VAL_ 1471 PassengerBackHeightDisplayReq 0 "No Display Request" 1 "Raise Display Request" 2 "Descent Display Request" 3 "Not monitored";
VAL_ 1471 PassengerSlidingDisplayRequest 0 "No Display Request" 1 "Sliding Forward Display Request" 2 "Sliding Backward Display Request" 3 "Not monitored";
VAL_ 1471 PassengerEasyAccessState 0 "Unavailable" 1 "Easy access activated" 2 "Easy access not activated" 3 "Not used";
VAL_ 1471 PassengerFrontHeightDisplayReq 0 "No Display Request" 1 "Raise Display Request" 2 "Descent Display Request" 3 "Not monitored";
VAL_ 1471 PassengerMassageIntensityState 0 "No intensity" 1 "Intensity 1" 2 "Intensity 2" 3 "Intensity 3" 4 "Intensity 4" 5 "Intensity 5" 6 "Not Used" 7 "Not Used";
VAL_ 1471 PassengerMassageVelocityState 0 "No velocity" 1 "velocity 1" 2 "velocity 2" 3 "velocity 3" 4 "velocity 4" 5 "velocity 5" 6 "Not Used" 7 "Not Used";
VAL_ 1471 PassengerMassageActivationState 0 "Massage OFF" 1 "Massage ON";
VAL_ 1471 PassengerSeatMMIRequest 0 "Multimedia Seat Settings Not Requested" 1 "Multimedia Seat Settings Requested";
VAL_ 1471 PassengerReclinerDisplayRequest 0 "No Display Request" 1 "Recliner Moving Forward Display Request" 2 "Recliner Moving Backward Display Request" 3 "Not monitored";
VAL_ 1472 MexModeState 0 "Unavailable" 1 "MEX MODE ECO" 2 "MEX MODE COMFORT" 3 "MEX MODE NORMAL" 4 "MEX MODE DYNAMIC" 5 "MEX MODE PERSONNAL" 6 "MEX MODE RACE" 7 "MEX MODE SNOW";
VAL_ 1474 ClimRightTempDisplay 0 "No display" 8 "Display Lo" 10 "Display Hi";
VAL_ 1474 ClimTempDisplay 0 "No display" 8 "Display Lo" 10 "Display Hi";
VAL_ 1474 ClimFlowDistrDisplay 0 "No display" 1 "Feet" 2 "Aerator" 3 "Feet + Aerator" 4 "Mild flow" 5 "Feet + Mild flow" 6 "Mild flow + Aerator" 7 "Feet + Aerator Mild flow" 8 "Defrost" 9 "Feet + Defrost" 10 "Aerator + Defrost" 11 "Feet + Aerator + Defrost" 12 "Mild flow + Defrost" 13 "Feet + Mild flow + Defrost" 14 "Aerator + Mild flow + Defrost" 15 "Feet + Aerator + Mild flow + Defrost";
VAL_ 1474 ClimOFFModeDisplay 0 "No Display" 1 "OFF Mode Activated Display";
VAL_ 1474 ClimBlowerLevelDisplay 0 "No display" 1 "Level 1" 2 "Level 2" 3 "Level 3" 4 "Level 4" 5 "Level 5" 6 "Level 6" 7 "Level 7" 8 "Level 8" 9 "Level 9" 10 "Level 10" 11 "Level 11" 12 "Level 12" 13 "Level 13" 14 "Level 14" 15 "Blower Off";
VAL_ 1474 ClimClearnessDisplay 0 "No display" 1 "Clearness ON" 2 "Clearness OFF" 3 "Not Used";
VAL_ 1474 ClimAutoModeDisplay 0 "No display" 1 "Soft display" 2 "Fast display" 3 "Auto display";
VAL_ 1474 ClimAutoDisplay 0 "No display" 1 "Auto activated" 2 "Auto not activated" 3 "Not used";
VAL_ 1474 ClimACDisplay 0 "No display" 1 "AC ON" 2 "AC OFF" 3 "Not used";
VAL_ 1474 ClimRearDefrostDisplay 0 "No display" 1 "Rear defrost ON" 2 "Rear defrost OFF" 3 "Not Used";
VAL_ 1478 SR_ContinuousRecordLengthRequest 0 "No request" 1 "1 minute" 2 "3 minutes" 3 "5 minutes" 4 "Not used" 5 "Not used" 6 "Not used" 7 "Reset request";
VAL_ 1478 SR_ShockSensitivityRequest 0 "No request" 1 "Low" 2 "Mid" 3 "High" 4 "Not used" 5 "Not used" 6 "Not used" 7 "Reset request";
VAL_ 1478 SR_DrivingInfoRecordRequest 0 "No request" 1 "No Record request" 2 "Record request" 3 "Reset request";
VAL_ 1478 SR_LocationInfoRecordRequest 0 "No request" 1 "No record request" 2 "Record request" 3 "Reset request";
VAL_ 1478 SR_SoundRecordRequest 0 "No request" 1 "Sound recorded request" 2 "Sound not recorded request" 3 "Reset request";
VAL_ 1478 SR_CustomerRecordLengthRequest 0 "No request" 1 "1 minute" 2 "3 minutes" 3 "5 minutes" 4 "Not used" 5 "Not used" 6 "Not used" 7 "Reset request";
VAL_ 1479 MC_TutorialRequest_V2 0 "No Request" 1 "On going" 2 "Tuto well done" 3 "Not Used";
VAL_ 1479 GNSS_Time_Status 0 "Unable to determine" 1 "Time from Satellite" 2 "Time from offboard" 3 "Not Used";
VAL_ 1479 ERP_ActivationStatus 0 "ERP OFF" 1 "ERP ON";
VAL_ 1480 ChargeTimeDisplayAtAPrct 0 "No Display";
VAL_ 1480 ChargeTimeDisplayAtBPrct 0 "No Display";
VAL_ 1480 ChargeTimeDisplayAtCPrct 0 "No Display";
VAL_ 1480 ChargeTimeDisplayAtDPrct 0 "No Display";
VAL_ 1482 TSR_OSPActivationRequest2 0 "No request" 1 "TSR/OSP ON request" 2 "TSR/OSP OFF request" 3 "Reset Requested";
VAL_ 1482 LDW_ActivationRequest2 0 "No request" 1 "LDW activation request" 2 "LDW de-activation request" 3 "Reset request";
VAL_ 1482 LDW_VibrationIntensityReq2 0 "No request" 1 "Low intensity request" 2 "Middle intensity request" 3 "High intensity request" 4 "Not used" 5 "Not used" 6 "Not used" 7 "Reset request";
VAL_ 1482 SailingStopActivationRequest2 0 "No Request" 1 "Sailing stop requested" 2 "Sailing stop not requested" 3 "Reset request";
VAL_ 1482 AEB_FCWactivationRequest2 0 "No request" 1 "AEB OFF / FCW OFF" 2 "AEB OFF / FCW ON" 3 "AEB ON / FCW OFF" 4 "AEB ON / FCW ON" 5 "Not used" 6 "Not used" 7 "Reset request";
VAL_ 1482 LDW_SensibilityRequest2 0 "No request" 1 "Low sensibility request" 2 "Middle sensibility request" 3 "High sensibility request" 4 "Not Used" 5 "Not Used" 6 "Not Used" 7 "Reset request";
VAL_ 1482 FKP_ActivationRequest2 0 "No Request" 1 "Flank Protection NOT requested" 2 "Flank Protection Requested" 3 "Reset Request";
VAL_ 1482 MOD_ActivationRequest2 0 "No request" 1 "Activation request" 2 "Deactivation request" 3 "Reset request";
VAL_ 1482 SonarAutoDisplayRequest2 0 "No request" 1 "Auto Display Activated" 2 "Auto Display Deactivated" 3 "Reset request";
VAL_ 1482 DW_ActivationRequest2 0 "No request" 1 "DW Activation request" 2 "DW Deactivation request" 3 "Reset request";
VAL_ 1482 BSWrad_ActivationRequest2 0 "No request" 1 "Activation" 2 "Deactivation" 3 "Reset request";
VAL_ 1482 HFP_DefaultManeuverTypeRequest2 0 "no request" 1 "park in / parallel" 2 "park in / perpendicular" 3 "park in / angled" 4 "park out" 5 "Not used" 6 "Not used" 7 "Reset Request";
VAL_ 1482 HandDrivingActivationRequest2 0 "No request" 1 "Right Hand Driving requested" 2 "Left Hand Driving requested" 3 "Reset request";
VAL_ 1482 LKA_ActivationRequest2 0 "No request" 1 "Activation" 2 "Deactivation" 3 "Reset request";
VAL_ 1482 SailingIdleActivationReq2 0 "No request" 1 "Sailing idle activation Requested" 2 "Sailing idle deactivation Requested" 3 "Reset request";
VAL_ 1482 CTA_ActivationRequest2 0 "No request" 1 "Activation" 2 "Deactivation" 3 "Reset request";
VAL_ 1482 AFS_ActivationRequest2 0 "No request" 1 "Activation" 2 "Deactivation" 3 "Reset request";
VAL_ 1482 LCA_ActivationRequest2 0 "No request" 1 "Activation" 2 "Deactivation" 3 "Reset request";
VAL_ 1486 ChargeAutonomyDisplayAtAPrct 0 "No Display";
VAL_ 1486 ChargeAutonomyDisplayAtBPrct 0 "No Display";
VAL_ 1486 ChargeAutonomyDisplayAtCPrct 0 "No Display";
VAL_ 1486 ChargeAutonomyDisplayAtDPrct 0 "No Display";
VAL_ 1486 ChargePowerEstimateDisplay 0 "No Display";
VAL_ 1486 ChargeAutonomyDisplayAtEPrct 0 "No Display";
VAL_ 1488 OffsetActivation_State 0 "Deactivated" 1 "Activated" 2 "Not used" 3 "Unavailable";
VAL_ 1488 LCA_SteeringWheelTakeOverAlert 0 "No alert" 1 "Alert level 1" 2 "Alert level 2" 3 "Alert level 3" 4 "Alert level 4" 5 "Alert level 5" 6 "Alert level 6" 7 "Alert level 7";
VAL_ 1488 DetectedTargetDisplayRequest 0 "No detected target display requested" 1 "Detected FAR target display requested" 2 "Detected NEAR target display requested" 3 "Detected CLOSE1 target display requested" 4 "Detected CLOSE2 target display requested" 5 "Detected CLOSE3 target display requested" 6 "Not Used" 7 "Not Used";
VAL_ 1488 DW_FollowUpTimeAlert 0 "No alert" 1 "Alert";
VAL_ 1488 OffsetValue_State 0 "Unavailable" 1 "-10" 2 "-9" 3 "-8" 4 "-7" 5 "-6" 6 "-5" 7 "-4" 8 "-3" 9 "-2" 10 "-1" 11 "0" 12 "1" 13 "2" 14 "3" 15 "4" 16 "5" 17 "6" 18 "7" 19 "8" 20 "9" 21 "10" 22 "Not used" 23 "Not used" 24 "Not used" 25 "Not used" 26 "Not used" 27 "Not used" 28 "Not used" 29 "Not used" 30 "Not used" 31 "Not used";
VAL_ 1490 HUD_IVI_Status 0 "Not Available" 1 "Available_HUD with back light ON" 2 "Available_HUD with back light OFF" 3 "not available because of AD function";
VAL_ 1490 HUD_RotationPositionState 0 "Step 1" 1 "Step 2" 2 "Step 3" 3 "Step 4" 4 "Step 5" 5 "Step 6" 6 "Step 7" 7 "Step 8" 8 "Step 9" 9 "Step 10" 10 "Step 11" 11 "Step 12" 12 "Step 13" 13 "Step 14" 14 "Step 15" 15 "Step 16" 16 "Step 17" 17 "Step 18" 18 "Step 19" 19 "Step 20" 20 "Step 21" 21 "Not used" 22 "Not used" 23 "Not used" 24 "Not used" 25 "Not used" 26 "Not used" 27 "Not used" 28 "Not used" 29 "Not used" 30 "Not used" 31 "Not used";
VAL_ 1490 HUD_FOTA_status 0 "Idle" 1 "Installation in progress" 2 "Copying in progress" 3 "Vehicle Condition check in progress" 4 "Ready for activation" 5 "Switch in progress" 6 "Reboot in progress" 7 "Component version check in progress" 8 "Configuration install in progress" 9 "Activation complete" 10 "Cancel in progress" 11 "Error detected" 12 "Update Error detected" 13 "Rollback in progress" 14 "Rollback complete" 15 "Ready for Slave Distribution" 16 "Slave Distribution in progress" 17 "Slave Integrity check in progress" 18 "Slave Distribution complete" 19 "Slave Installation in progress" 20 "Slave Copying in progress" 21 "Slave Installation complete" 22 "Not used" 23 "Not used" 24 "Not used" 25 "Not used" 26 "Not used" 27 "Not used" 28 "Not used" 29 "Not used" 30 "Not used" 31 "invalid";
VAL_ 1491 ParkAssistVolumeRequest 0 "No request " 1 "Level 0 (off)" 2 "Level 1" 3 "Level 2" 4 "Level 3" 5 "Level 4" 6 "Level 5" 7 "Reset request";
VAL_ 1496 WCBS_Memory_Fault 0 "Unavailable" 1 "No memory Fault" 2 "Memory Fault" 3 "Not Used";
VAL_ 1496 WCBS_Coil_Disconnection 0 "Unavailable" 1 "No coil disconnection" 2 "Coil disconnection" 3 "Not Used";
VAL_ 1496 WCBS_ChargingStopReason 0 "Unavailable" 1 "RX_UNKNOWN" 2 "RX_CHARGE_COMPLETE" 3 "RX_INTERNAL_FAULT" 4 "RX_OVER_VOLT" 5 "RX_OVER_TEMP" 6 "RX_OVER_CURRENT" 7 "RX_BATTERY_FAILURE" 8 "RX_NO_RESPONSE" 9 "RX_RESTART_PWR_XFER" 10 "RX_NEG_FAILURE" 11 "TX_COILSELEQFAULTCOIL" 12 "TX_ANALOGPING_FAULT" 13 "TX_INCOMPATIBLE_PWR" 14 "TX_QFOD_ERROR" 15 "TX_OVER_TEMP_FAULT" 16 "TX_RCVPWR_TIMEOUT" 17 "TX_FOD_ERROR" 18 "TX_OVER_INCURR_LIMIT" 19 "TX_INPWREXCEED" 20 "TX_OVER_COILCURR_LIMIT" 21 "Not used" 22 "Not used" 23 "Not used" 24 "Not used" 25 "Not used" 26 "Not used" 27 "Not used" 28 "Not used" 29 "Not used" 30 "Not used" 31 "Not used";
VAL_ 1496 Smartphone_Manufacturer 0 "Unavailable" 1 "Samsung" 2 "LGE" 3 "Nokia" 4 "Motorola" 5 "Apple" 6 "Others" 7 "Not Used";
VAL_ 1496 Smartphone_Charging_Standard 0 "Unavailable" 1 "WPC 1.0" 2 "WPC 1.1" 3 "WPC 1.2" 4 "WPC x.x" 5 "PMA" 6 "A4WP" 7 "Not Used";
VAL_ 1496 InductiveChargerStatus 0 "Unavailable" 1 "Object detecting" 2 "Charging" 3 "Uncharging";
VAL_ 1496 WCBS_HMI 0 "Unavailable" 1 "High temperature pop-up" 2 "Foreign Object Detected pop-up" 3 "not used" 4 "Charging on pictogram" 5 "No HMI" 6 "not used" 7 "Full charged pictogram";
VAL_ 1498 AD_DistanceDuration 0 "No Display" 1023 "Unavailable Value";
VAL_ 1498 AD_TimeDuration 0 "No Display";
VAL_ 1498 RouteConf_IVI_Request 0 "No Request" 1 "Confirm Request";
VAL_ 1498 AD_MapLisence_Status 0 "HD Map and  Route Assist Setting OFF" 1 "Route Assist Setting OFF" 2 "HD Map OFF" 3 "HD Map and  Route Assist Setting ON";
VAL_ 1502 MultiDriveMode_ECM_v2 0 "Mode ECM 1 (Normal)" 1 "Mode ECM 2" 2 "Mode ECM 3 (Sport)" 3 "Mode ECM 4" 4 "Mode ECM 5 (Eco)" 5 "Mode ECM 6 (Race)" 6 "Mode ECM 7 (Snow)" 7 "Mode8" 8 "Mode9" 9 "Mode10" 10 "Mode11" 11 "Mode12" 12 "Mode13" 13 "Mode14" 14 "Not used" 15 "Unavailable";
VAL_ 1503 PassengerBackBolsterDisplayReq 0 "No display request" 1 "Backrest bolster increase Display Request" 2 "Backrest bolster decrease Display Request" 3 "Not monitored";
VAL_ 1503 PassengerSeatMemoState 0 "Seat Position 1" 1 "Seat Position 2" 2 "Seat Position 3" 3 "Seat Position 4" 4 "Seat Position 5" 5 "Seat Position 6" 6 "Seat in No Position memorized" 7 "Not used";
VAL_ 1503 PassengerSwitchMassageRequest 0 "No massage request" 1 "Massage Request";
VAL_ 1503 PsgerCushionBolsterDisplayReq 0 "No display request" 1 "Cushion bolster increase Display Request" 2 "Cushion bolster decrease Display Request" 3 "Not monitored";
VAL_ 1503 PsLumbarDisplayRequest_Z_Axis 0 "No display request" 1 "Z Axis Upward" 2 "Z Axis Downward" 3 "Not monitored";
VAL_ 1503 PsLumbarDisplayRequest_X_Axis 0 "No display request" 1 "X Axis Frontward" 2 "X Axis Backward" 3 "Not monitored";
VAL_ 1503 PassengerCLADisplayRequest 0 "No Display Request" 1 "CLA Forward Display Request" 2 "CLA Backward Display Request" 3 "Not Used";
VAL_ 1503 PassengerOttomanMotorErrorState 0 "Normal" 1 "Motor position lost";
VAL_ 1503 PsMassagePopUpActivationState 0 "OFF" 1 "ON";
VAL_ 1503 PsMassageExecuteState 0 "No request" 1 "Massage execute failed" 2 "Massage execute forbid" 3 "Massage execute forbid for Ready OFF" 4 "Massage stop for Ready OFF" 5 "Not used" 6 "Not used" 7 "Not used";
VAL_ 1503 PassengerMassageCondition 0 "Function not available" 1 "Function available";
VAL_ 1503 PassengerLifterMotorErrorState 0 "Normal" 1 "Motor position lost";
VAL_ 1503 PassengerReclinerMotorErrorState 0 "Normal" 1 "Motor position lost" 2 "Anti-pinch" 3 "Not used";
VAL_ 1503 PassengerMemoryPopUpReq 0 "No request" 1 "Display request";
VAL_ 1503 PassengerMemorySetState 0 "No request" 1 "Memory set forbid";
VAL_ 1503 PassengerMemoryRecallState 0 "No request" 1 "Seat execute failed" 2 "Seat execute forbid" 3 "Seat executing" 4 "Seat execute forbid for not in P mode" 5 "Stop for not in P mode" 6 "Not used" 7 "Not used";
VAL_ 1503 PassengerSlideMotorErrorState 0 "Normal" 1 "Motor position lost" 2 "Anti-pinch" 3 "Not used";
VAL_ 1505 AQMIoniserModeSelectionReq 0 "No request" 1 "Off" 2 "Clean" 3 "Relax";
VAL_ 1505 ClimFPBlowerRequest 0 "No Request" 1 "Level 1" 2 "Level 2" 3 "Level 3" 4 "Level 4" 5 "Level 5" 6 "Level 6" 7 "Level 7" 8 "Level 8" 9 "Level 9" 10 "Level 10" 11 "Level 11" 12 "Level 12" 13 "Level 13" 14 "Level 14" 15 "Blower OFF";
VAL_ 1505 BlowerReductionRequest 0 "Blower Speed Reduction not Requested" 1 "Blower Speed Reduction Requested";
VAL_ 1505 AirFreshenerRequest 0 "No request" 1 "Air Freshener ON requested" 2 "Air Freshener OFF requested" 3 "Not Used";
VAL_ 1506 SSU_Movement 0 "Stopped" 1 "Opening / Tilt Up" 2 "Closing / Tilt Down" 3 "Anti Pinch";
VAL_ 1506 SRU_Movement 0 "Stopped" 1 "Opening / Tilt Up" 2 "Closing / Tilt Down" 3 "Anti Pinch";
VAL_ 1506 MM_GeneralAuthWindowsLift 0 "Action possible" 1 "Action temporary not possible" 2 "Action permanantly not possible" 3 "Reserved" 4 "Reserved" 5 "Reserved" 6 "Reserved" 7 "Reserved" 8 "Reserved" 9 "Reserved" 10 "Reserved" 11 "Reserved" 12 "Reserved" 13 "Reserved" 14 "Reserved" 15 "Reserved";
VAL_ 1506 WindowPositionExtended_FR 0 "Position invalid" 1 "Fully Close 0%" 2 "Position 5%" 3 "Position 10%" 4 "Position 15%" 5 "Position 20%" 6 "Position 25%" 7 "Position 30%" 8 "Position 35%" 9 "Position 40%" 10 "Position 45%" 11 "Position 50%" 12 "Position 55%" 13 "Position 60%" 14 "Position 65%" 15 "Position 70%" 16 "Position 75%" 17 "Position 80%" 18 "Position 85%" 19 "Position 90%" 20 "Position 95%" 21 "Fully Open 100%" 22 "Reserved" 23 "Reserved" 24 "Reserved" 25 "Reserved" 26 "Reserved" 27 "Reserved" 28 "Reserved" 29 "Reserved" 30 "Reserved" 31 "Reserved";
VAL_ 1506 WindowPositionExtended_FL 0 "Position invalid" 1 "Fully Close 0%" 2 "Position 5%" 3 "Position 10%" 4 "Position 15%" 5 "Position 20%" 6 "Position 25%" 7 "Position 30%" 8 "Position 35%" 9 "Position 40%" 10 "Position 45%" 11 "Position 50%" 12 "Position 55%" 13 "Position 60%" 14 "Position 65%" 15 "Position 70%" 16 "Position 75%" 17 "Position 80%" 18 "Position 85%" 19 "Position 90%" 20 "Position 95%" 21 "Fully Open 100%" 22 "Reserved" 23 "Reserved" 24 "Reserved" 25 "Reserved" 26 "Reserved" 27 "Reserved" 28 "Reserved" 29 "Reserved" 30 "Reserved" 31 "Reserved";
VAL_ 1506 WindowPositionExtended_RR 0 "Position invalid" 1 "Fully Close 0%" 2 "Position 5%" 3 "Position 10%" 4 "Position 15%" 5 "Position 20%" 6 "Position 25%" 7 "Position 30%" 8 "Position 35%" 9 "Position 40%" 10 "Position 45%" 11 "Position 50%" 12 "Position 55%" 13 "Position 60%" 14 "Position 65%" 15 "Position 70%" 16 "Position 75%" 17 "Position 80%" 18 "Position 85%" 19 "Position 90%" 20 "Position 95%" 21 "Position 100%" 22 "Not used" 23 "Not used" 24 "Not used" 25 "Not used" 26 "Not used" 27 "Not used" 28 "Not used" 29 "Not used" 30 "Not used" 31 "Not used";
VAL_ 1506 WindowPositionExtended_RL 0 "Position invalid" 1 "Fully Close 0%" 2 "Position 5%" 3 "Position 10%" 4 "Position 15%" 5 "Position 20%" 6 "Position 25%" 7 "Position 30%" 8 "Position 35%" 9 "Position 40%" 10 "Position 45%" 11 "Position 50%" 12 "Position 55%" 13 "Position 60%" 14 "Position 65%" 15 "Position 70%" 16 "Position 75%" 17 "Position 80%" 18 "Position 85%" 19 "Position 90%" 20 "Position 95%" 21 "Fully Open 100%" 22 "Reserved" 23 "Reserved" 24 "Reserved" 25 "Reserved" 26 "Reserved" 27 "Reserved" 28 "Reserved" 29 "Reserved" 30 "Reserved" 31 "Reserved";
VAL_ 1506 SSU_Position 0 "SunShade position invalid" 1 "SunShade position 0 (closed)(Shade Full Close)" 2 "SunShade sector 01(Shade 0%_8.4% Open)" 3 "SunShade position 1(Shade 8.4%_16.7% Open)" 4 "SunShade sector 12(Shade 16.7%_25% Open)" 5 "SunShade position 2(Shade 25.0%_33.4% Open)" 6 "SunShade sector 23(Shade 33.4%_41.6% Open)" 7 "SunShade position 3(Shade 41.6%_50% Open)" 8 "SunShade sector 34(Shade 50%_58.4% Open)" 9 "SunShade position 4(Shade 58.4%_66.7% Open)" 10 "SunShade synchro 1(Shade 66.7%_75.0% Open)" 11 "SunShade synchro 2(Shade 75.0%_83.4% Open)" 12 "SunShade synchro 3(Shade 83.4%_91.6% Open)" 13 "SunShade synchro 4(Shade 91.6%_100.0% Open)" 14 "SunShade synchro 5(Shade full Open software open end)" 15 "SunShade synchro 6(Shade mechanical open end)";
VAL_ 1506 RearWiperModeStatus 0 "No Request" 1 "Off Request" 2 "INT Request" 3 "Continuous Request" 4 "Service Position Request" 5 "Not Used" 6 "Not Used" 7 "Not Used";
VAL_ 1508 RESPreSoak_ProgStatus 0 "No programmed" 1 "1 time only (RES or Presoak)" 2 "Every two hours (5 times max)" 3 "Not used";
VAL_ 1508 InternalLightingIntensityState 0 "OFF" 1 "Level 1" 2 "Level 2" 3 "Level 3" 4 "Level 4" 5 "Level 5" 6 "Not used" 7 "Not used";
VAL_ 1508 RES_ProgrammationForbidden 0 "Programmation authorized" 1 "Programmation forbidden";
VAL_ 1509 RemoteFunctionService_TCU 0 "Table Value30440";
VAL_ 1510 FixedMaintenanceRange 254 "Fixed maintenance requested within one month" 255 "Fixed maintenance requested (time over)";
VAL_ 1510 AlertMinBeforeOverhaul 0 "No Alert " 1 "Time Prealert" 2 "Distance Prealert" 3 "Overhaul Alert";
VAL_ 1510 ClusterSkinState_v2 0 "Skin1" 1 "Skin2" 2 "Skin3" 3 "Skin4" 4 "Skin5" 5 "Skin6" 6 "Skin7" 7 "Skin8" 8 "Skin9" 9 "Skin10" 10 "Skin11" 11 "Not used" 12 "Not used" 13 "Not used" 14 "Not used" 15 "Not used";
VAL_ 1511 WheelStateRL 0 "Pressure ok and no failure" 1 "Failure" 2 "Underinflation" 3 "Underinflation and failure" 4 "Puncture" 5 "Puncture and failure" 6 "Puncture and underinflation" 7 "Puncture and underinflation and failure";
VAL_ 1511 WheelStateRR 0 "Pressure ok and no failure" 1 "Failure" 2 "Underinflation" 3 "Underinflation and failure" 4 "Puncture" 5 "Puncture and failure" 6 "Puncture and underinflation" 7 "Puncture and underinflation and failure";
VAL_ 1511 TPMS_AckResetDriver 0 "Unvailable Value" 1 "Reset driver NOT  taken into account" 2 "Reset driver taken into account" 3 "Not Used";
VAL_ 1511 WheelStateFL 0 "Pressure ok and no failure" 1 "Failure" 2 "Underinflation" 3 "Underinflation and failure" 4 "Puncture" 5 "Puncture and failure" 6 "Puncture and underinflation" 7 "Puncture and underinflation and failure";
VAL_ 1511 WheelStateFR 0 "Pressure ok and no failure" 1 "Failure" 2 "Underinflation" 3 "Underinflation and failure" 4 "Puncture" 5 "Puncture and failure" 6 "Puncture and underinflation" 7 "Puncture and underinflation and failure";
VAL_ 1511 OldPressureFL 0 "Pressure up to date" 1 "Pressure not up to date";
VAL_ 1511 OldPressureFR 0 "Pressure up to date" 1 "Pressure not up to date";
VAL_ 1511 OldPressureRL 0 "Pressure up to date" 1 "Pressure not up to date";
VAL_ 1511 OldPressureRR 0 "Pressure up to date" 1 "Pressure not up to date";
VAL_ 1511 TPMS_AutoLocStatus 0 "init phase - or autolocation not avaliable (not present)" 1 "Autolocation is active" 2 "Autolocation finished OK" 3 "autolocation not OK";
VAL_ 1516 LDW_SoundLevelRequest_v2 0 "No request" 1 "Level 0" 2 "Level 1" 3 "Level 2" 4 "Level 3" 5 "Level 4" 6 "Level 5" 7 "Reset request";
VAL_ 1519 UserSettingCopySource 0 "Not copy" 1 "Guest" 2 "User1" 3 "User2" 4 "User3" 5 "User4" 6 "User5" 7 "Not used";
VAL_ 1519 UserSettingCopyTarget 0 "Not copy" 1 "Guest" 2 "User1" 3 "User2" 4 "User3" 5 "User4" 6 "User5" 7 "Not used";
VAL_ 1519 User5_RegistrationState 0 "Not Registered" 1 "Registered";
VAL_ 1519 User4_RegistrationState 0 "Not Registered" 1 "Registered";
VAL_ 1519 KeyLinkInitializationState 0 "Initialization in progress" 1 "Initialization completed";
VAL_ 1519 KeyLinkActivationState 0 "Activate" 1 "Deactivate";
VAL_ 1519 User3_RegistrationState 0 "Not Registered" 1 "Registered";
VAL_ 1519 User2_RegistrationState 0 "Not Registered" 1 "Registered";
VAL_ 1519 User1_RegistrationState 0 "Not Registered" 1 "Registered";
VAL_ 1519 UserSettingCopyRequest 0 "No request" 1 "Request";
VAL_ 1519 ADA1ActivationRequest2 0 "No request" 1 "Activation" 2 "Deactivation" 3 "Reset request";
VAL_ 1519 ASAactivationRequest2 0 "No request" 1 "Activation" 2 "Deactivation" 3 "Reset request";
VAL_ 1519 CurrentUserState_v2 0 "Guest" 1 "User 1" 2 "User 2" 3 "User 3" 4 "User 4" 5 "User 5" 6 "Not used" 7 "Unavailable";
VAL_ 1519 SteeringSettingRequest2_v2 0 "No request" 1 "Mode EPS 1 Normal / Normal" 2 "Mode EPS 2 Normal / Confort" 3 "Mode EPS 3 Normal / Sport" 4 "Mode EPS 4" 5 "Mode EPS 5 Casual / Normal" 6 "Mode EPS 6 Casual / Confort" 7 "Mode EPS 7 Casual / Sport" 8 "Mode EPS 8" 9 "Mode EPS 9 Quick / Normal" 10 "Mode EPS 10 Quick / Confort" 11 "Mode EPS 11 Quick / Sport" 12 "Mode EPS 12" 13 "Mode EPS 13" 14 "According to DriveMode" 15 "Reset request";
VAL_ 1519 PowerTrainSettingRequest2 0 "No request" 1 "Mode1 (Standard)" 2 "Mode2 (Sport)" 3 "Mode3 (Eco)" 4 "Mode4 (Snow)" 5 "Mode5" 6 "Mode6" 7 "Mode7" 8 "Mode8" 9 "Mode9" 10 "Mode10" 11 "Mode11" 12 "Mode12" 13 "Mode13" 14 "Mode14" 15 "Reset request";
VAL_ 1519 ClimAQSSensitivityRequest 0 "No request" 1 "Level 1" 2 "Level 2" 3 "Level 3" 4 "Level 4" 5 "Level 5" 6 "OFF request" 7 "Reset request";
VAL_ 1519 UserProfileResetRequest 0 "No Request" 1 "Reset Profile 1" 2 "Reset Profile 2" 3 "Reset Profile 3" 4 "Reset Profile 4" 5 "Reset Profile 5" 6 "Reset Guest" 7 "Not used";
VAL_ 1519 MC_ActivationRequest 0 "No request" 1 "Magic Cockpit ON request" 2 "Magic Cockpit OFF request" 3 "Not used";
VAL_ 1519 MC_PositionRecallRequest 0 "No request" 1 "Recall MC position 1" 2 "Recall MC position 2" 3 "Recall MC position 3" 4 "Recall MC position 4" 5 "Recall MC position 5" 6 "Recall MC position 6" 7 "Recall MC position 7" 8 "Recall MC position 8" 9 "Recall MC position 9" 10 "Recall MC position 10" 11 "Recall MC position 11" 12 "Recall MC position 12" 13 "Recall MC position 13" 14 "Recall MC position 14" 15 "Reset Request";
VAL_ 1519 VMCSettingRequest 0 "No request" 1 "Mode1" 2 "Mode2" 3 "Mode3" 4 "Mode4" 5 "Mode5" 6 "Mode6" 7 "Mode7" 8 "Mode8" 9 "Mode9" 10 "Mode10" 11 "Mode11" 12 "Mode12" 13 "Mode13" 14 "Mode14" 15 "Reset request";
VAL_ 1519 MC_PositionCalculate 0 "No Request (default value)" 1 "Calculate position 1" 2 "Calculate position 2" 3 "Calculate position 3" 4 "Calculate position 4" 5 "Calculate position 5" 6 "Calculate position 6" 7 "Calculate position 7" 8 "Calculate position 8" 9 "Calculate position 9" 10 "Calculate position 10" 11 "Calculate position 11" 12 "Calculate position 12" 13 "Calculate position 13" 14 "Calculate position 14" 15 "Calculate MC all positions";
VAL_ 1519 MC_PositionSaveRequest 0 "No request" 1 "Save MC position 1" 2 "Save MC position 2" 3 "Save MC position 3" 4 "Save MC position 4" 5 "Save MC position 5" 6 "Save MC position 6" 7 "Save MC position 7" 8 "Save MC position 8" 9 "Save MC position 9" 10 "Save MC position 10" 11 "Save MC position 11" 12 "Save MC position 12" 13 "Save MC position 13" 14 "Save MC position 14" 15 "Unavailable";
VAL_ 1523 HVchargeDisplayState 0 "Meter HMI during charge desactivated" 1 "Meter HMI during charge activated";
VAL_ 1526 CHG_FaultType_BLMS 0 "No failure" 1 "Failure 1" 2 "Failure 2" 3 "Failure 3" 4 "Failure 4" 5 "Failure 5" 6 "Failure 6" 7 "Failure 7";
VAL_ 1529 HUD_ActivationRequest2 0 "No request" 1 "Deployment Activation request" 2 "Deployment Deactivation request" 3 "Reset request";
VAL_ 1529 BSWson_ActivationRequest2 0 "No request" 1 "Activation request" 2 "Deactivation request" 3 "Reset request";
VAL_ 1529 BCI_ActivationRequest2 0 "No request" 1 "Activation" 2 "Deactivation" 3 "Reset request";
VAL_ 1529 ELKA_ActivationRequest2 0 "No request" 1 "Activation" 2 "Deactivation" 3 "Reset request";
VAL_ 1529 HUD_PositionRequest2 0 "No request" 1 "Step 1" 2 "Step 2" 3 "Step 3" 4 "Step 4" 5 "Step 5" 6 "Step 6" 7 "Step 7" 8 "Step 8" 9 "Step 9" 10 "Step 10" 11 "Step 11" 12 "Step 12" 13 "Step 13" 14 "Step 14" 15 "Step 15" 16 "Step 16" 17 "Step 17" 18 "Step 18" 19 "Step 19" 20 "Step 20" 21 "Step 21" 22 "Not used" 23 "Not used" 24 "Not used" 25 "Not used" 26 "Not used" 27 "Not used" 28 "Not used" 29 "Not used" 30 "Not used" 31 "Reset request";
VAL_ 1529 FCW_SensibilityRequest2 0 "No Request" 1 "Early" 2 "Standard" 3 "Late" 4 "ResetRequest" 5 "Not used" 6 "Not used" 7 "Not used";
VAL_ 1529 HUD_NightLuminosityRequest2 0 "No Request" 1 "Step 1" 2 "Step 2" 3 "Step 3" 4 "Step 4" 5 "Step 5" 6 "Step 6" 7 "Step 7" 8 "Step 8" 9 "Step 9" 10 "Step 10" 11 "Step 11" 12 "Step 12" 13 "Step 13" 14 "Step 14" 15 "Step 15" 16 "Step 16" 17 "Step 17" 18 "Step 18" 19 "Step 19" 20 "Step 20" 21 "Step 21" 22 "Not used" 23 "Not used" 24 "Not used" 25 "Not used" 26 "Not used" 27 "Not used" 28 "Not used" 29 "Not used" 30 "Not used" 31 "Reset request";
VAL_ 1529 WAL_ActivationRequest2 0 "No request" 1 "WAL activation request" 2 "WAL deactivation request" 3 "WAL factory setting reset request";
VAL_ 1529 APPRUN_ActivationRequest2 0 "No Request" 1 "Approach Unlock Activation request" 2 "Approach Unlock Desactivation request" 3 "Approach Unlock Factory setting reset request";
VAL_ 1531 AutoFrontWiperActivationRequest2 0 "No automatic front wiper activation deactivation request" 1 "Automatic Front wiper activation requested" 2 "Automatic Front wiper de-activation requested" 3 "Automatic Front wiper Reset requested";
VAL_ 1531 AHL_ActivationRequest2 0 "No Request" 1 "Automatic High Low beam activation requested" 2 "Automatic High Low beam de-activation requested" 3 "Reset Request";
VAL_ 1531 ParkAssistVolumeRequest2 0 "No request " 1 "Level 0 (off)" 2 "Level 1" 3 "Level 2" 4 "Level 3" 5 "Level 4" 6 "Level 5" 7 "Reset request";
VAL_ 1531 IKeyAccessActivationRequest2 0 "No Request" 1 "iKey Access Activation request" 2 "iKey Access Desactivation request" 3 "Reset Request";
VAL_ 1531 FrontRearWiperDropRequest2 0 "No drop wiper activation de-activation request" 1 "Drop wiper activation requested" 2 "Drop wiper de-activation requested" 3 "Drop wiper reset requested";
VAL_ 1531 FrontParkAssistActivationReq2 0 "No request" 1 "Front parking assistance activation requested" 2 "Front parking assistance de-activation requested" 3 "Reset Request";
VAL_ 1531 AutoRearWiperActivationRequest2 0 "No automatic rear wiper activation de-activation request" 1 "Automatic Rear wiper activation requested" 2 "Automatic Rear wiper de-activation requested" 3 "Reset request";
VAL_ 1531 WGSactivationRequest2 0 "No request" 1 "Activation" 2 "Deactivation" 3 "Reset request";
VAL_ 1531 SingleDoorOpeningActivationReq2 0 "No single door opening request" 1 "Single door opening activation requested" 2 "Single door opening de-activation requested" 3 "Reset Request";
VAL_ 1531 RearParkAssistActivationReq2 0 "No request" 1 "Rear parking assistance activation requested" 2 "Rear parking assistance de-activation requested" 3 "Reset Request";
VAL_ 1531 AutoLightSensitivityRequest2 0 "No request" 1 "Configuration 1" 2 "Configuration 2" 3 "Configuration 3" 4 "Configuration 4" 5 "Not used" 6 "Not used" 7 "Reset request";
VAL_ 1531 AutoReLockActivationReq2 0 "No Request" 1 "Auto ReLock ON request" 2 "Auto ReLock OFF request" 3 "Reset Value Request";
VAL_ 1531 MotorwayFlashersNumberRequest2 0 "No request" 1 "1 flash per CSW mode request" 2 "3 flash per CSW mode request" 3 "5 flash per CSW mode request" 4 "Not used" 5 "Not used" 6 "Not used" 7 "Reset request";
VAL_ 1531 AutoFMHactivationRequest2 0 "No request" 1 "Activation" 2 "Deactivation" 3 "Reset request";
VAL_ 1531 SilentModeActivationRequest2 0 "No Request " 1 "Silent mode Activation Request " 2 "Silent Mode Deactivation Request " 3 "Reset Request";
VAL_ 1531 AutoLockActivationReq2 0 "No request" 1 "Auto Lock with Speed Activation request" 2 "Auto Lock with Park-out Activation request" 3 "No Auto Lock" 4 "Not used" 5 "Not used" 6 "Not used" 7 "Reset Request";
VAL_ 1531 AutoUnLockActivationReq2 0 "No Request" 1 "Auto UnLock with IGN OFF request" 2 "Auto UnLock with Park request" 3 "No Auto UnLock" 4 "Not used" 5 "Not used" 6 "Not used" 7 "Reset Request";
VAL_ 1531 ParkAssistSensitivityRequest2 0 "No Request " 1 "Far Range Detection " 2 "Middle Range Detection" 3 "Near Range Detection" 4 "Not used" 5 "Not used " 6 "Not used" 7 "Reset Request";
VAL_ 1531 AutoFoldingActivationRequest2 0 "No request" 1 "Disable" 2 "IGN Unfold" 3 "Unlock + IGN Unfold" 4 "Not used" 5 "Not used" 6 "Not used" 7 "Reset request";
VAL_ 1531 PredictiveShiftActivationRequest2 0 "No request" 1 "Activation request" 2 "Deactivation request" 3 "Reset request";
VAL_ 1531 AirCondEcoActivationRequest2 0 "No request" 1 "Eco activation request" 2 "Eco deactivation request" 3 "Reset request";
VAL_ 1531 CruiseEcoActivationRequest2 0 "No request" 1 "Activation (Eco) request" 2 "De-activation (Normal) request" 3 "Reset request";
VAL_ 1531 AutoFMHdurationRequest2 0 "No request" 1 "30 sec" 2 "45 sec" 3 "60 sec" 4 "90 sec" 5 "120 sec" 6 "150 sec" 7 "180 sec" 8 "Not used" 9 "Not used" 10 "Not used" 11 "Not used" 12 "Not used" 13 "Not used" 14 "Not used" 15 "Reset request";
VAL_ 1531 ISS_EcoActivationRequest2 0 "No request" 1 "Eco activation request" 2 "Eco deactivation request" 3 "Reset request";
VAL_ 1537 ACC_TargetDistanceAlert 0 "No ACC warning" 1 "ACC approach warning" 2 "ACC collision warning" 3 "ACC cancel warning";
VAL_ 1537 LCA_OverrideDisplay 0 "No override" 1 "Override";
VAL_ 1537 LCA_ActivationState 0 "Activated" 1 "Deactivated";
VAL_ 1537 ADL3_DisclaimerAcknowledgement 0 "Not acknowledged" 1 "Acknowledgment";
VAL_ 1537 ContextSpeed_ActivationState 0 "Unavailable" 1 "AutoMode OFF" 2 "AutoMode ON" 3 "Prompt mode activated";
VAL_ 1537 ContextRoad_ActivationState 0 "AutoMode OFF" 1 "AutoMode ON" 2 "Not Used" 3 "Unavailable";
VAL_ 1538 BCI_FailureDisplay 0 "No display" 1 "Temporary Failure Display" 2 "Permanent Failure Display" 3 "Not used";
VAL_ 1538 LDW_AlertStatus 0 "No alert" 1 "Right alert" 2 "Left alert" 3 "Not used";
VAL_ 1538 EAP_AlertDisplay 0 "No display" 1 "Alert display";
VAL_ 1538 LCA_LineCrossingAlert 0 "No alert" 1 "Right alert" 2 "Left alert" 3 "RIght and left alert";
VAL_ 1538 RAB_AlertStatus 0 "No alert" 1 "Alert 1" 2 "Alert 2" 3 "Not used";
VAL_ 1538 RAB_ActivationState 0 "Activated" 1 "Deactivated";
VAL_ 1538 WDA_ActivationState 0 "Activated" 1 "Deactivated";
VAL_ 1538 RAB_StatusDisplay 0 "No display" 1 "Not operational" 2 "Operational" 3 "Not used";
VAL_ 1538 RAB_FailureDisplay 0 "No display" 1 "Temporary failure display" 2 "Permanent failure display" 3 "Not used";
